VERSION ""

NS_ :

BS_:

BU_: VMCU TECU OBDScanT2 IC3 HPCU EMS ECUspare2 ECUspare1 DACU CIOM BBM

BO_ 2671813364 DiagReqMsgIntTGW2_A2_F4_BB2: 8 IC3
 SG_ InternalTesterDiagSig_A2_F4_ISig : 0|64@1+ (1,0) [0|0] ""  CIOM

BO_ 2671813108 DiagReqMsgIntTGW2_A1_F4_BB2: 8 IC3
 SG_ InternalTesterDiagSig_A1_F4_ISig : 0|64@1+ (1,0) [0|0] ""  CIOM

BO_ 2671812852 DiagReqMsgIntTGW2_A0_F4_BB2: 8 IC3
 SG_ InternalTesterDiagSig_A0_F4_ISig : 0|64@1+ (1,0) [0|0] ""  CIOM

BO_ 2671810804 DiagReqMsgIntTGW2_98_F4_BB2: 8 IC3
 SG_ InternalTesterDiagSig_98_F4_ISig : 0|64@1+ (1,0) [0|0] ""  CIOM

BO_ 2671807732 DiagReqMsgIntTGW2_8C_F4_BB2: 8 IC3
 SG_ InternalTesterDiagSig_8C_F4_ISig : 0|64@1+ (1,0) [0|0] ""  DACU

BO_ 2671801076 DiagReqMsgIntTGW2_72_F4_BB2: 8 IC3
 SG_ InternalTesterDiagSig_72_F4_ISig : 0|64@1+ (1,0) [0|0] ""  VMCU

BO_ 2671800820 DiagReqMsgIntTGW2_71_F4_BB2: 8 IC3
 SG_ InternalTesterDiagSig_71_F4_ISig : 0|64@1+ (1,0) [0|0] ""  VMCU

BO_ 2671793140 DiagReqMsgIntTGW2_53_F4_BB2: 8 IC3
 SG_ InternalTesterDiagSig_53_F4_ISig : 0|64@1+ (1,0) [0|0] ""  CIOM

BO_ 2671792884 DiagReqMsgIntTGW2_52_F4_BB2: 8 IC3
 SG_ InternalTesterDiagSig_52_F4_ISig : 0|64@1+ (1,0) [0|0] ""  DACU

BO_ 2671792628 DiagReqMsgIntTGW2_51_F4_BB2: 8 IC3
 SG_ InternalTesterDiagSig_51_F4_ISig : 0|64@1+ (1,0) [0|0] ""  DACU

BO_ 2671792372 DiagReqMsgIntTGW2_50_F4_BB2: 8 IC3
 SG_ InternalTesterDiagSig_50_F4_ISig : 0|64@1+ (1,0) [0|0] ""  DACU

BO_ 2671788276 DiagReqMsgIntTGW2_40_F4_BB2: 8 IC3
 SG_ InternalTesterDiagSig_40_F4_ISig : 0|64@1+ (1,0) [0|0] ""  CIOM

BO_ 2671784436 DiagReqMsgIntTGW2_31_F4_BB2: 8 IC3
 SG_ InternalTesterDiagSig_31_F4_ISig : 0|64@1+ (1,0) [0|0] ""  VMCU

BO_ 2671784180 DiagReqMsgIntTGW2_30_F4_BB2: 8 IC3
 SG_ InternalTesterDiagSig_30_F4_ISig : 0|64@1+ (1,0) [0|0] ""  VMCU

BO_ 2671781620 DiagReqMsgIntTGW2_26_F4_BB2: 8 IC3
 SG_ InternalTesterDiagSig_26_F4_ISig : 0|64@1+ (1,0) [0|0] ""  CIOM

BO_ 2671781364 DiagReqMsgIntTGW2_25_F4_BB2: 8 IC3
 SG_ InternalTesterDiagSig_25_F4_ISig : 0|64@1+ (1,0) [0|0] ""  VMCU

BO_ 2671781108 DiagReqMsgIntTGW2_24_F4_BB2: 8 IC3
 SG_ InternalTesterDiagSig_24_F4_ISig : 0|64@1+ (1,0) [0|0] ""  VMCU

BO_ 2671780852 DiagReqMsgIntTGW2_23_F4_BB2: 8 IC3
 SG_ InternalTesterDiagSig_23_F4_ISig : 0|64@1+ (1,0) [0|0] ""  VMCU

BO_ 2671780596 DiagReqMsgIntTGW2_22_F4_BB2: 8 IC3
 SG_ InternalTesterDiagSig_22_F4_ISig : 0|64@1+ (1,0) [0|0] ""  VMCU

BO_ 2671780340 DiagReqMsgIntTGW2_21_F4_BB2: 8 IC3
 SG_ InternalTesterDiagSig_21_F4_ISig : 0|64@1+ (1,0) [0|0] ""  VMCU

BO_ 2671780084 DiagReqMsgIntTGW2_20_F4_BB2: 8 IC3
 SG_ InternalTesterDiagSig_20_F4_ISig : 0|64@1+ (1,0) [0|0] ""  VMCU

BO_ 2671778548 DiagReqMsgIntTGW2_1A_F4_BB2: 8 IC3
 SG_ InternalTesterDiagSig_1A_F4_ISig : 0|64@1+ (1,0) [0|0] ""  VMCU

BO_ 2671778036 DiagReqMsgIntTGW2_18_F4_BB2: 8 IC3
 SG_ InternalTesterDiagSig_18_F4_ISig : 0|64@1+ (1,0) [0|0] ""  TECU

BO_ 2671775988 DiagReqMsgIntTGW2_10_F4_BB2: 8 IC3
 SG_ InternalTesterDiagSig_10_F4_ISig : 0|64@1+ (1,0) [0|0] ""  EMS

BO_ 2671833075 DiagReqMsgIntIC_EF_F3_BB2: 8 IC3
 SG_ InternalTesterDiagSig_EF_F3 : 0|64@1+ (1,0) [0|0] ""  HPCU

BO_ 2671821555 DiagReqMsgIntIC_C2_F3_BB2: 8 IC3
 SG_ InternalTesterDiagSig_C2_F3 : 0|64@1+ (1,0) [0|0] ""  HPCU

BO_ 2671814131 DiagReqMsgIntIC_A5_F3_BB2: 8 IC3
 SG_ InternalTesterDiagSig_A5_F3_ISig : 0|64@1+ (1,0) [0|0] ""  VMCU

BO_ 2671801331 DiagReqMsgIntIC_73_F3_BB2: 8 IC3
 SG_ InternalTesterDiagSig_73_F3_ISig : 0|64@1+ (1,0) [0|0] ""  VMCU

BO_ 2671797747 DiagReqMsgIntIC_65_F3_BB2: 8 IC3
 SG_ InternalTesterDiagSig_65_F3_ISig : 0|64@1+ (1,0) [0|0] ""  VMCU

BO_ 2671786227 DiagReqMsgIntIC_38_F3_BB2: 8 IC3
 SG_ InternalTesterDiagSig_38_F3_ISig : 0|64@1+ (1,0) [0|0] ""  VMCU

BO_ 2671830771 DiagReqMsgIntHMIIOM_E6_F3_BB2: 8 IC3
 SG_ InternalTesterDiagSig_E6_F3 : 0|64@1+ (1,0) [0|0] ""  BBM

BO_ 2671830515 DiagReqMsgIntHMIIOM_E5_F3_BB2: 8 IC3
 SG_ InternalTesterDiagSig_E5_F3_ISig : 0|64@1+ (1,0) [0|0] ""  BBM

BO_ 2671821043 DiagReqMsgIntHMIIOM_C0_F3_BB2: 8 IC3
 SG_ InternalTesterDiagSig_C0_F3_ISig : 0|64@1+ (1,0) [0|0] ""  CIOM

BO_ 2671813363 DiagReqMsgIntHMIIOM_A2_F3_BB2: 8 IC3
 SG_ InternalTesterDiagSig_A2_F3_ISig : 0|64@1+ (1,0) [0|0] ""  CIOM

BO_ 2671813107 DiagReqMsgIntHMIIOM_A1_F3_BB2: 8 IC3
 SG_ InternalTesterDiagSig_A1_F3_ISig : 0|64@1+ (1,0) [0|0] ""  CIOM

BO_ 2671812851 DiagReqMsgIntHMIIOM_A0_F3_BB2: 8 IC3
 SG_ InternalTesterDiagSig_A0_F3_ISig : 0|64@1+ (1,0) [0|0] ""  CIOM

BO_ 2671810803 DiagReqMsgIntHMIIOM_98_F3_BB2: 8 IC3
 SG_ InternalTesterDiagSig_98_F3_ISig : 0|64@1+ (1,0) [0|0] ""  CIOM

BO_ 2671807731 DiagReqMsgIntHMIIOM_8C_F3_BB2: 8 IC3
 SG_ InternalTesterDiagSig_8C_F3_ISig : 0|64@1+ (1,0) [0|0] ""  DACU

BO_ 2671801075 DiagReqMsgIntHMIIOM_72_F3_BB2: 8 IC3
 SG_ InternalTesterDiagSig_72_F3_ISig : 0|64@1+ (1,0) [0|0] ""  VMCU

BO_ 2671800819 DiagReqMsgIntHMIIOM_71_F3_BB2: 8 IC3
 SG_ InternalTesterDiagSig_71_F3_ISig : 0|64@1+ (1,0) [0|0] ""  VMCU

BO_ 2671793139 DiagReqMsgIntHMIIOM_53_F3_BB2: 8 IC3
 SG_ InternalTesterDiagSig_53_F3_ISig : 0|64@1+ (1,0) [0|0] ""  CIOM

BO_ 2671792883 DiagReqMsgIntHMIIOM_52_F3_BB2: 8 IC3
 SG_ InternalTesterDiagSig_52_F3_ISig : 0|64@1+ (1,0) [0|0] ""  DACU

BO_ 2671792627 DiagReqMsgIntHMIIOM_51_F3_BB2: 8 IC3
 SG_ InternalTesterDiagSig_51_F3_ISig : 0|64@1+ (1,0) [0|0] ""  DACU

BO_ 2671792371 DiagReqMsgIntHMIIOM_50_F3_BB2: 8 IC3
 SG_ InternalTesterDiagSig_50_F3 : 0|64@1+ (1,0) [0|0] ""  DACU

BO_ 2671788275 DiagReqMsgIntHMIIOM_40_F3_BB2: 8 IC3
 SG_ InternalTesterDiagSig_40_F3 : 0|64@1+ (1,0) [0|0] ""  CIOM

BO_ 2671784435 DiagReqMsgIntHMIIOM_31_F3_BB2: 8 IC3
 SG_ InternalTesterDiagSig_31_F3_ISig : 0|64@1+ (1,0) [0|0] ""  VMCU

BO_ 2671784179 DiagReqMsgIntHMIIOM_30_F3_BB2: 8 IC3
 SG_ InternalTesterDiagSig_30_F3_ISig : 0|64@1+ (1,0) [0|0] ""  VMCU

BO_ 2671781619 DiagReqMsgIntHMIIOM_26_F3_BB2: 8 IC3
 SG_ InternalTesterDiagSig_26_F3_ISig : 0|64@1+ (1,0) [0|0] ""  CIOM

BO_ 2671781363 DiagReqMsgIntHMIIOM_25_F3_BB2: 8 IC3
 SG_ InternalTesterDiagSig_25_F3_ISig : 0|64@1+ (1,0) [0|0] ""  VMCU

BO_ 2671781107 DiagReqMsgIntHMIIOM_24_F3_BB2: 8 IC3
 SG_ InternalTesterDiagSig_24_F3 : 0|64@1+ (1,0) [0|0] ""  VMCU

BO_ 2671780851 DiagReqMsgIntHMIIOM_23_F3_BB2: 8 IC3
 SG_ InternalTesterDiagSig_23_F3_ISig : 0|64@1+ (1,0) [0|0] ""  VMCU

BO_ 2671780595 DiagReqMsgIntHMIIOM_22_F3_BB2: 8 IC3
 SG_ InternalTesterDiagSig_22_F3_ISig : 0|64@1+ (1,0) [0|0] ""  VMCU

BO_ 2671780339 DiagReqMsgIntHMIIOM_21_F3_BB2: 8 IC3
 SG_ InternalTesterDiagSig_21_F3_ISig : 0|64@1+ (1,0) [0|0] ""  VMCU

BO_ 2671780083 DiagReqMsgIntHMIIOM_20_F3_BB2: 8 IC3
 SG_ InternalTesterDiagSig_20_F3_ISig : 0|64@1+ (1,0) [0|0] ""  VMCU

BO_ 2671778547 DiagReqMsgIntHMIIOM_1A_F3_BB2: 8 IC3
 SG_ InternalTesterDiagSig_1A_F3_ISig : 0|64@1+ (1,0) [0|0] ""  VMCU

BO_ 2671778035 DiagReqMsgIntHMIIOM_18_F3_BB2: 8 IC3
 SG_ InternalTesterDiagSig_18_F3 : 0|64@1+ (1,0) [0|0] ""  TECU

BO_ 2671775987 DiagReqMsgIntHMIIOM_10_F3_BB2: 8 IC3
 SG_ InternalTesterDiagSig_10_F3 : 0|64@1+ (1,0) [0|0] ""  EMS

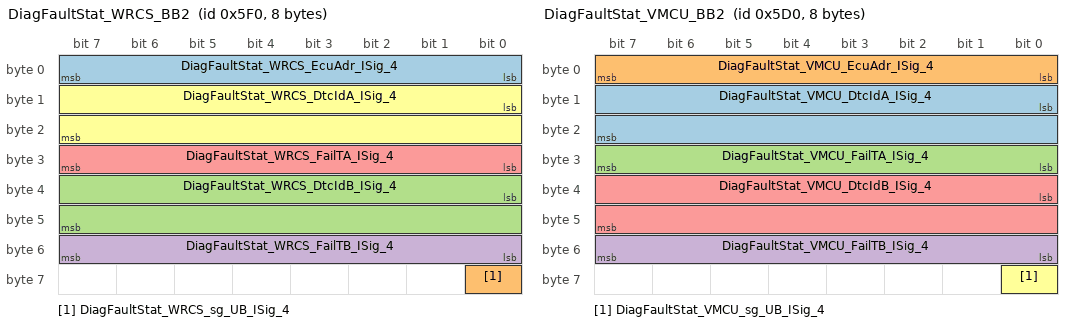
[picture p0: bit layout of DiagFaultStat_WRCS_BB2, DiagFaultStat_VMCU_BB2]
BO_ 1520 DiagFaultStat_WRCS_BB2: 8 CIOM
 SG_ DiagFaultStat_WRCS_EcuAdr_ISig_4 : 0|8@1+ (1,0) [0|255] ""  IC3
 SG_ DiagFaultStat_WRCS_sg_UB_ISig_4 : 56|1@1+ (1,0) [0|0] ""  IC3
 SG_ DiagFaultStat_WRCS_DtcIdB_ISig_4 : 32|16@1+ (1,0) [0|65535] ""  IC3
 SG_ DiagFaultStat_WRCS_FailTB_ISig_4 : 48|8@1+ (1,0) [0|255] ""  IC3
 SG_ DiagFaultStat_WRCS_FailTA_ISig_4 : 24|8@1+ (1,0) [0|255] ""  IC3
 SG_ DiagFaultStat_WRCS_DtcIdA_ISig_4 : 8|16@1+ (1,0) [0|65535] ""  IC3

BO_ 1488 DiagFaultStat_VMCU_BB2: 8 VMCU
 SG_ DiagFaultStat_VMCU_DtcIdA_ISig_4 : 8|16@1+ (1,0) [0|65535] ""  IC3
 SG_ DiagFaultStat_VMCU_EcuAdr_ISig_4 : 0|8@1+ (1,0) [0|255] ""  IC3
 SG_ DiagFaultStat_VMCU_FailTA_ISig_4 : 24|8@1+ (1,0) [0|255] ""  IC3
 SG_ DiagFaultStat_VMCU_FailTB_ISig_4 : 48|8@1+ (1,0) [0|255] ""  IC3
 SG_ DiagFaultStat_VMCU_DtcIdB_ISig_4 : 32|16@1+ (1,0) [0|65535] ""  IC3
 SG_ DiagFaultStat_VMCU_sg_UB_ISig_4 : 56|1@1+ (1,0) [0|0] ""  IC3

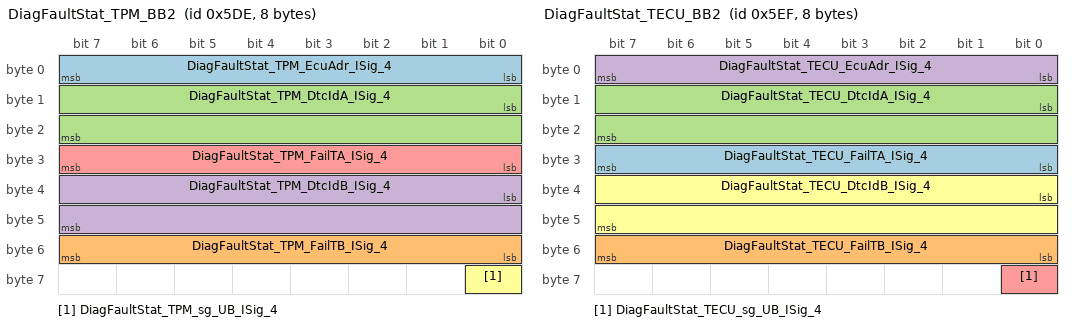
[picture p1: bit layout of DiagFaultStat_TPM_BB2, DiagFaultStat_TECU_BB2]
BO_ 1502 DiagFaultStat_TPM_BB2: 8 VMCU
 SG_ DiagFaultStat_TPM_EcuAdr_ISig_4 : 0|8@1+ (1,0) [0|255] ""  IC3
 SG_ DiagFaultStat_TPM_FailTB_ISig_4 : 48|8@1+ (1,0) [0|255] ""  IC3
 SG_ DiagFaultStat_TPM_DtcIdA_ISig_4 : 8|16@1+ (1,0) [0|65535] ""  IC3
 SG_ DiagFaultStat_TPM_DtcIdB_ISig_4 : 32|16@1+ (1,0) [0|65535] ""  IC3
 SG_ DiagFaultStat_TPM_FailTA_ISig_4 : 24|8@1+ (1,0) [0|255] ""  IC3
 SG_ DiagFaultStat_TPM_sg_UB_ISig_4 : 56|1@1+ (1,0) [0|0] ""  IC3

BO_ 1519 DiagFaultStat_TECU_BB2: 8 TECU
 SG_ DiagFaultStat_TECU_FailTA_ISig_4 : 24|8@1+ (1,0) [0|255] ""  IC3
 SG_ DiagFaultStat_TECU_FailTB_ISig_4 : 48|8@1+ (1,0) [0|255] ""  IC3
 SG_ DiagFaultStat_TECU_DtcIdA_ISig_4 : 8|16@1+ (1,0) [0|65535] ""  IC3
 SG_ DiagFaultStat_TECU_EcuAdr_ISig_4 : 0|8@1+ (1,0) [0|255] ""  IC3
 SG_ DiagFaultStat_TECU_sg_UB_ISig_4 : 56|1@1+ (1,0) [0|0] ""  IC3
 SG_ DiagFaultStat_TECU_DtcIdB_ISig_4 : 32|16@1+ (1,0) [0|65535] ""  IC3

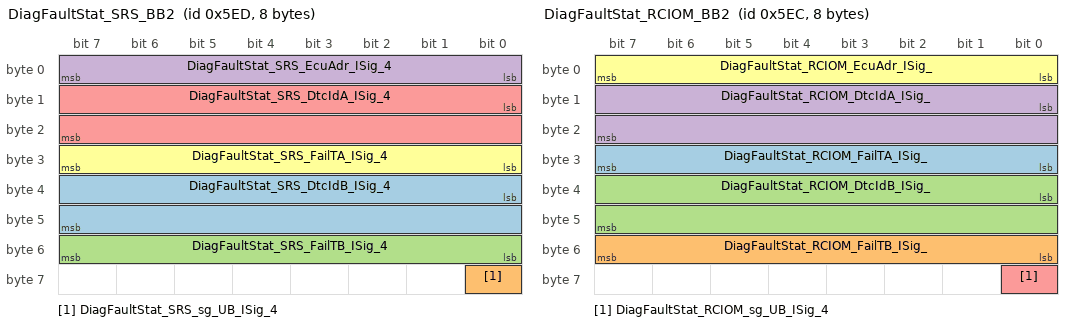
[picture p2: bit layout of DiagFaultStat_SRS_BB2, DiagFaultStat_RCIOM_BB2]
BO_ 1517 DiagFaultStat_SRS_BB2: 8 CIOM
 SG_ DiagFaultStat_SRS_DtcIdB_ISig_4 : 32|16@1+ (1,0) [0|65535] ""  IC3
 SG_ DiagFaultStat_SRS_sg_UB_ISig_4 : 56|1@1+ (1,0) [0|0] ""  IC3
 SG_ DiagFaultStat_SRS_FailTB_ISig_4 : 48|8@1+ (1,0) [0|255] ""  IC3
 SG_ DiagFaultStat_SRS_EcuAdr_ISig_4 : 0|8@1+ (1,0) [0|255] ""  IC3
 SG_ DiagFaultStat_SRS_DtcIdA_ISig_4 : 8|16@1+ (1,0) [0|65535] ""  IC3
 SG_ DiagFaultStat_SRS_FailTA_ISig_4 : 24|8@1+ (1,0) [0|255] ""  IC3

BO_ 1516 DiagFaultStat_RCIOM_BB2: 8 VMCU
 SG_ DiagFaultStat_RCIOM_FailTA_ISig_ : 24|8@1+ (1,0) [0|255] ""  IC3
 SG_ DiagFaultStat_RCIOM_FailTB_ISig_ : 48|8@1+ (1,0) [0|255] ""  IC3
 SG_ DiagFaultStat_RCIOM_DtcIdB_ISig_ : 32|16@1+ (1,0) [0|65535] ""  IC3
 SG_ DiagFaultStat_RCIOM_DtcIdA_ISig_ : 8|16@1+ (1,0) [0|65535] ""  IC3
 SG_ DiagFaultStat_RCIOM_sg_UB_ISig_4 : 56|1@1+ (1,0) [0|0] ""  IC3
 SG_ DiagFaultStat_RCIOM_EcuAdr_ISig_ : 0|8@1+ (1,0) [0|255] ""  IC3

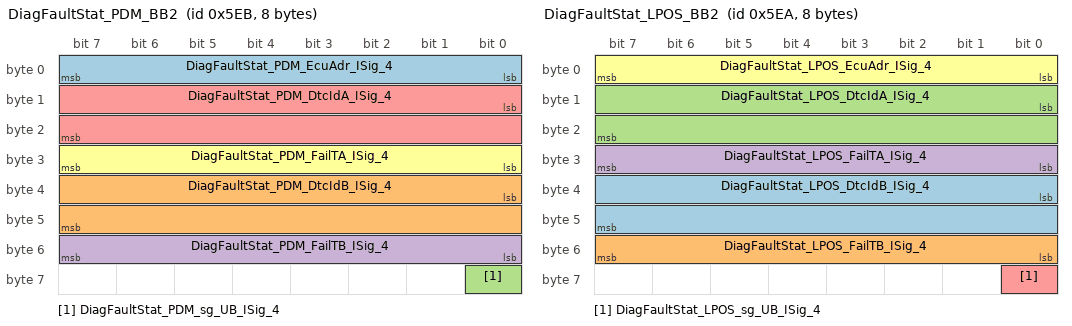
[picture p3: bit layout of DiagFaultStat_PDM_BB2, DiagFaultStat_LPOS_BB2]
BO_ 1515 DiagFaultStat_PDM_BB2: 8 CIOM
 SG_ DiagFaultStat_PDM_EcuAdr_ISig_4 : 0|8@1+ (1,0) [0|255] ""  IC3
 SG_ DiagFaultStat_PDM_DtcIdB_ISig_4 : 32|16@1+ (1,0) [0|65535] ""  IC3
 SG_ DiagFaultStat_PDM_sg_UB_ISig_4 : 56|1@1+ (1,0) [0|0] ""  IC3
 SG_ DiagFaultStat_PDM_FailTB_ISig_4 : 48|8@1+ (1,0) [0|255] ""  IC3
 SG_ DiagFaultStat_PDM_DtcIdA_ISig_4 : 8|16@1+ (1,0) [0|65535] ""  IC3
 SG_ DiagFaultStat_PDM_FailTA_ISig_4 : 24|8@1+ (1,0) [0|255] ""  IC3

BO_ 1514 DiagFaultStat_LPOS_BB2: 8 DACU
 SG_ DiagFaultStat_LPOS_DtcIdB_ISig_4 : 32|16@1+ (1,0) [0|65535] ""  IC3
 SG_ DiagFaultStat_LPOS_FailTB_ISig_4 : 48|8@1+ (1,0) [0|255] ""  IC3
 SG_ DiagFaultStat_LPOS_DtcIdA_ISig_4 : 8|16@1+ (1,0) [0|65535] ""  IC3
 SG_ DiagFaultStat_LPOS_FailTA_ISig_4 : 24|8@1+ (1,0) [0|255] ""  IC3
 SG_ DiagFaultStat_LPOS_sg_UB_ISig_4 : 56|1@1+ (1,0) [0|0] ""  IC3
 SG_ DiagFaultStat_LPOS_EcuAdr_ISig_4 : 0|8@1+ (1,0) [0|255] ""  IC3

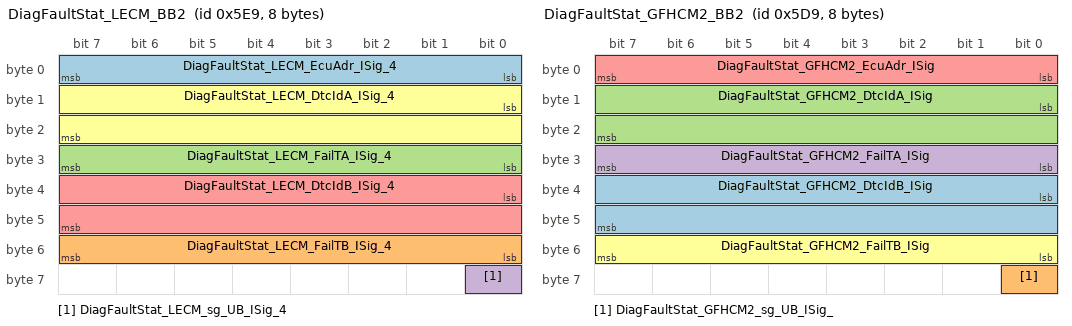
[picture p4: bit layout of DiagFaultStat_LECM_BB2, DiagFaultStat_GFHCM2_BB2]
BO_ 1513 DiagFaultStat_LECM_BB2: 8 CIOM
 SG_ DiagFaultStat_LECM_EcuAdr_ISig_4 : 0|8@1+ (1,0) [0|255] ""  IC3
 SG_ DiagFaultStat_LECM_FailTB_ISig_4 : 48|8@1+ (1,0) [0|255] ""  IC3
 SG_ DiagFaultStat_LECM_FailTA_ISig_4 : 24|8@1+ (1,0) [0|255] ""  IC3
 SG_ DiagFaultStat_LECM_sg_UB_ISig_4 : 56|1@1+ (1,0) [0|0] ""  IC3
 SG_ DiagFaultStat_LECM_DtcIdB_ISig_4 : 32|16@1+ (1,0) [0|65535] ""  IC3
 SG_ DiagFaultStat_LECM_DtcIdA_ISig_4 : 8|16@1+ (1,0) [0|65535] ""  IC3

BO_ 1497 DiagFaultStat_GFHCM2_BB2: 8 VMCU
 SG_ DiagFaultStat_GFHCM2_DtcIdB_ISig : 32|16@1+ (1,0) [0|65535] ""  IC3
 SG_ DiagFaultStat_GFHCM2_sg_UB_ISig_ : 56|1@1+ (1,0) [0|0] ""  IC3
 SG_ DiagFaultStat_GFHCM2_DtcIdA_ISig : 8|16@1+ (1,0) [0|65535] ""  IC3
 SG_ DiagFaultStat_GFHCM2_FailTA_ISig : 24|8@1+ (1,0) [0|255] ""  IC3
 SG_ DiagFaultStat_GFHCM2_EcuAdr_ISig : 0|8@1+ (1,0) [0|255] ""  IC3
 SG_ DiagFaultStat_GFHCM2_FailTB_ISig : 48|8@1+ (1,0) [0|255] ""  IC3

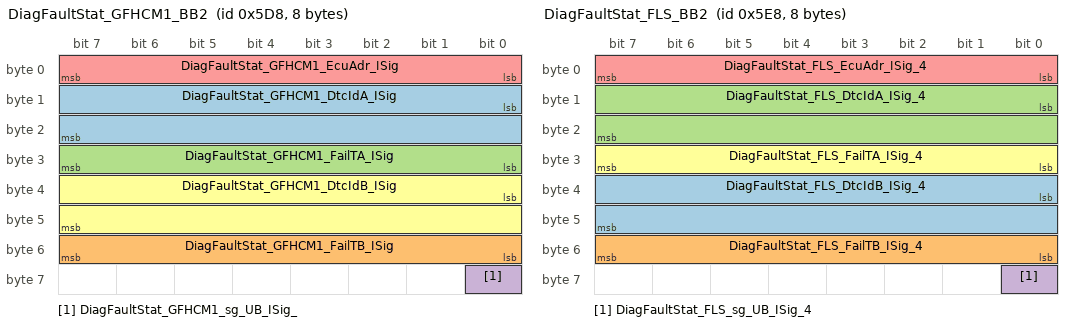
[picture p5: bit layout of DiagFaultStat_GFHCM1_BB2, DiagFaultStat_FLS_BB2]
BO_ 1496 DiagFaultStat_GFHCM1_BB2: 8 VMCU
 SG_ DiagFaultStat_GFHCM1_DtcIdA_ISig : 8|16@1+ (1,0) [0|65535] ""  IC3
 SG_ DiagFaultStat_GFHCM1_FailTB_ISig : 48|8@1+ (1,0) [0|255] ""  IC3
 SG_ DiagFaultStat_GFHCM1_FailTA_ISig : 24|8@1+ (1,0) [0|255] ""  IC3
 SG_ DiagFaultStat_GFHCM1_sg_UB_ISig_ : 56|1@1+ (1,0) [0|0] ""  IC3
 SG_ DiagFaultStat_GFHCM1_EcuAdr_ISig : 0|8@1+ (1,0) [0|255] ""  IC3
 SG_ DiagFaultStat_GFHCM1_DtcIdB_ISig : 32|16@1+ (1,0) [0|65535] ""  IC3

BO_ 1512 DiagFaultStat_FLS_BB2: 8 DACU
 SG_ DiagFaultStat_FLS_DtcIdB_ISig_4 : 32|16@1+ (1,0) [0|65535] ""  IC3
 SG_ DiagFaultStat_FLS_FailTB_ISig_4 : 48|8@1+ (1,0) [0|255] ""  IC3
 SG_ DiagFaultStat_FLS_DtcIdA_ISig_4 : 8|16@1+ (1,0) [0|65535] ""  IC3
 SG_ DiagFaultStat_FLS_sg_UB_ISig_4 : 56|1@1+ (1,0) [0|0] ""  IC3
 SG_ DiagFaultStat_FLS_EcuAdr_ISig_4 : 0|8@1+ (1,0) [0|255] ""  IC3
 SG_ DiagFaultStat_FLS_FailTA_ISig_4 : 24|8@1+ (1,0) [0|255] ""  IC3

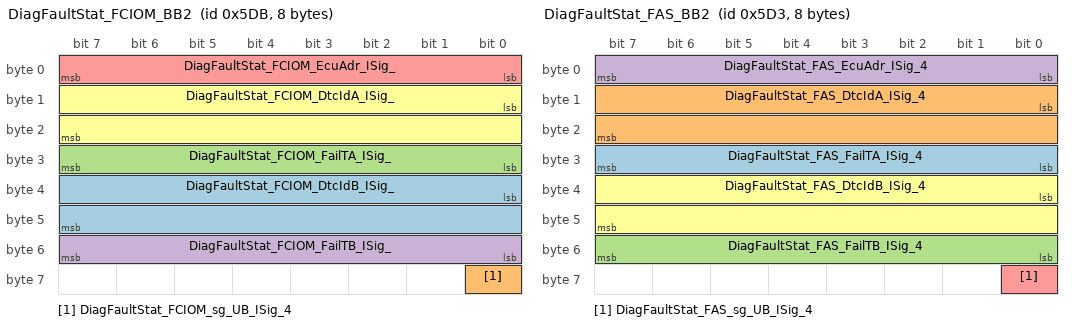
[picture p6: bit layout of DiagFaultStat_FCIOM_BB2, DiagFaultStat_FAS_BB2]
BO_ 1499 DiagFaultStat_FCIOM_BB2: 8 VMCU
 SG_ DiagFaultStat_FCIOM_DtcIdB_ISig_ : 32|16@1+ (1,0) [0|65535] ""  IC3
 SG_ DiagFaultStat_FCIOM_sg_UB_ISig_4 : 56|1@1+ (1,0) [0|0] ""  IC3
 SG_ DiagFaultStat_FCIOM_FailTA_ISig_ : 24|8@1+ (1,0) [0|255] ""  IC3
 SG_ DiagFaultStat_FCIOM_FailTB_ISig_ : 48|8@1+ (1,0) [0|255] ""  IC3
 SG_ DiagFaultStat_FCIOM_EcuAdr_ISig_ : 0|8@1+ (1,0) [0|255] ""  IC3
 SG_ DiagFaultStat_FCIOM_DtcIdA_ISig_ : 8|16@1+ (1,0) [0|65535] ""  IC3

BO_ 1491 DiagFaultStat_FAS_BB2: 8 VMCU
 SG_ DiagFaultStat_FAS_FailTA_ISig_4 : 24|8@1+ (1,0) [0|255] ""  IC3
 SG_ DiagFaultStat_FAS_DtcIdA_ISig_4 : 8|16@1+ (1,0) [0|65535] ""  IC3
 SG_ DiagFaultStat_FAS_FailTB_ISig_4 : 48|8@1+ (1,0) [0|255] ""  IC3
 SG_ DiagFaultStat_FAS_EcuAdr_ISig_4 : 0|8@1+ (1,0) [0|255] ""  IC3
 SG_ DiagFaultStat_FAS_sg_UB_ISig_4 : 56|1@1+ (1,0) [0|0] ""  IC3
 SG_ DiagFaultStat_FAS_DtcIdB_ISig_4 : 32|16@1+ (1,0) [0|65535] ""  IC3

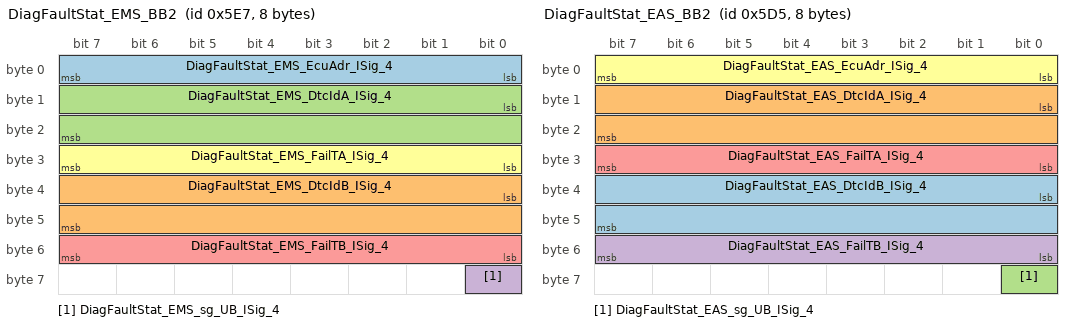
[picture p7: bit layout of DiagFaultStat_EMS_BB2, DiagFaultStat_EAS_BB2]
BO_ 1511 DiagFaultStat_EMS_BB2: 8 EMS
 SG_ DiagFaultStat_EMS_EcuAdr_ISig_4 : 0|8@1+ (1,0) [0|255] ""  IC3
 SG_ DiagFaultStat_EMS_DtcIdB_ISig_4 : 32|16@1+ (1,0) [0|65535] ""  IC3
 SG_ DiagFaultStat_EMS_DtcIdA_ISig_4 : 8|16@1+ (1,0) [0|65535] ""  IC3
 SG_ DiagFaultStat_EMS_sg_UB_ISig_4 : 56|1@1+ (1,0) [0|0] ""  IC3
 SG_ DiagFaultStat_EMS_FailTB_ISig_4 : 48|8@1+ (1,0) [0|255] ""  IC3
 SG_ DiagFaultStat_EMS_FailTA_ISig_4 : 24|8@1+ (1,0) [0|255] ""  IC3

BO_ 1493 DiagFaultStat_EAS_BB2: 8 VMCU
 SG_ DiagFaultStat_EAS_DtcIdB_ISig_4 : 32|16@1+ (1,0) [0|65535] ""  IC3
 SG_ DiagFaultStat_EAS_DtcIdA_ISig_4 : 8|16@1+ (1,0) [0|65535] ""  IC3
 SG_ DiagFaultStat_EAS_sg_UB_ISig_4 : 56|1@1+ (1,0) [0|0] ""  IC3
 SG_ DiagFaultStat_EAS_FailTB_ISig_4 : 48|8@1+ (1,0) [0|255] ""  IC3
 SG_ DiagFaultStat_EAS_FailTA_ISig_4 : 24|8@1+ (1,0) [0|255] ""  IC3
 SG_ DiagFaultStat_EAS_EcuAdr_ISig_4 : 0|8@1+ (1,0) [0|255] ""  IC3

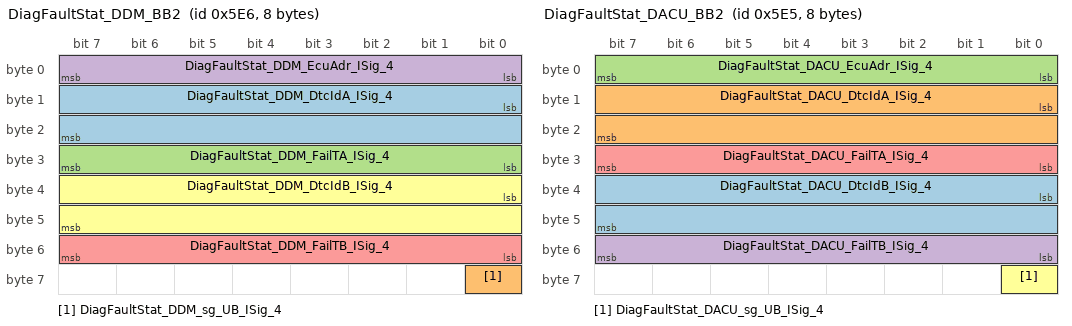
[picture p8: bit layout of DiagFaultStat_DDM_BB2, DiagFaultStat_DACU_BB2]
BO_ 1510 DiagFaultStat_DDM_BB2: 8 CIOM
 SG_ DiagFaultStat_DDM_DtcIdA_ISig_4 : 8|16@1+ (1,0) [0|65535] ""  IC3
 SG_ DiagFaultStat_DDM_sg_UB_ISig_4 : 56|1@1+ (1,0) [0|0] ""  IC3
 SG_ DiagFaultStat_DDM_FailTA_ISig_4 : 24|8@1+ (1,0) [0|255] ""  IC3
 SG_ DiagFaultStat_DDM_EcuAdr_ISig_4 : 0|8@1+ (1,0) [0|255] ""  IC3
 SG_ DiagFaultStat_DDM_FailTB_ISig_4 : 48|8@1+ (1,0) [0|255] ""  IC3
 SG_ DiagFaultStat_DDM_DtcIdB_ISig_4 : 32|16@1+ (1,0) [0|65535] ""  IC3

BO_ 1509 DiagFaultStat_DACU_BB2: 8 DACU
 SG_ DiagFaultStat_DACU_DtcIdB_ISig_4 : 32|16@1+ (1,0) [0|65535] ""  IC3
 SG_ DiagFaultStat_DACU_DtcIdA_ISig_4 : 8|16@1+ (1,0) [0|65535] ""  IC3
 SG_ DiagFaultStat_DACU_EcuAdr_ISig_4 : 0|8@1+ (1,0) [0|255] ""  IC3
 SG_ DiagFaultStat_DACU_FailTB_ISig_4 : 48|8@1+ (1,0) [0|255] ""  IC3
 SG_ DiagFaultStat_DACU_FailTA_ISig_4 : 24|8@1+ (1,0) [0|255] ""  IC3
 SG_ DiagFaultStat_DACU_sg_UB_ISig_4 : 56|1@1+ (1,0) [0|0] ""  IC3

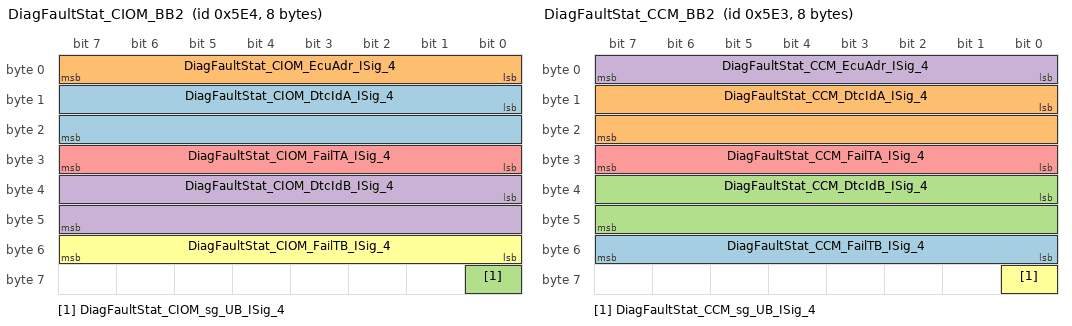
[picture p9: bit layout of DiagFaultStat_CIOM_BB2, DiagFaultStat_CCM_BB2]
BO_ 1508 DiagFaultStat_CIOM_BB2: 8 CIOM
 SG_ DiagFaultStat_CIOM_DtcIdA_ISig_4 : 8|16@1+ (1,0) [0|65535] ""  IC3
 SG_ DiagFaultStat_CIOM_EcuAdr_ISig_4 : 0|8@1+ (1,0) [0|255] ""  IC3
 SG_ DiagFaultStat_CIOM_sg_UB_ISig_4 : 56|1@1+ (1,0) [0|0] ""  IC3
 SG_ DiagFaultStat_CIOM_DtcIdB_ISig_4 : 32|16@1+ (1,0) [0|65535] ""  IC3
 SG_ DiagFaultStat_CIOM_FailTA_ISig_4 : 24|8@1+ (1,0) [0|255] ""  IC3
 SG_ DiagFaultStat_CIOM_FailTB_ISig_4 : 48|8@1+ (1,0) [0|255] ""  IC3

BO_ 1507 DiagFaultStat_CCM_BB2: 8 CIOM
 SG_ DiagFaultStat_CCM_FailTB_ISig_4 : 48|8@1+ (1,0) [0|255] ""  IC3
 SG_ DiagFaultStat_CCM_DtcIdA_ISig_4 : 8|16@1+ (1,0) [0|65535] ""  IC3
 SG_ DiagFaultStat_CCM_DtcIdB_ISig_4 : 32|16@1+ (1,0) [0|65535] ""  IC3
 SG_ DiagFaultStat_CCM_EcuAdr_ISig_4 : 0|8@1+ (1,0) [0|255] ""  IC3
 SG_ DiagFaultStat_CCM_FailTA_ISig_4 : 24|8@1+ (1,0) [0|255] ""  IC3
 SG_ DiagFaultStat_CCM_sg_UB_ISig_4 : 56|1@1+ (1,0) [0|0] ""  IC3

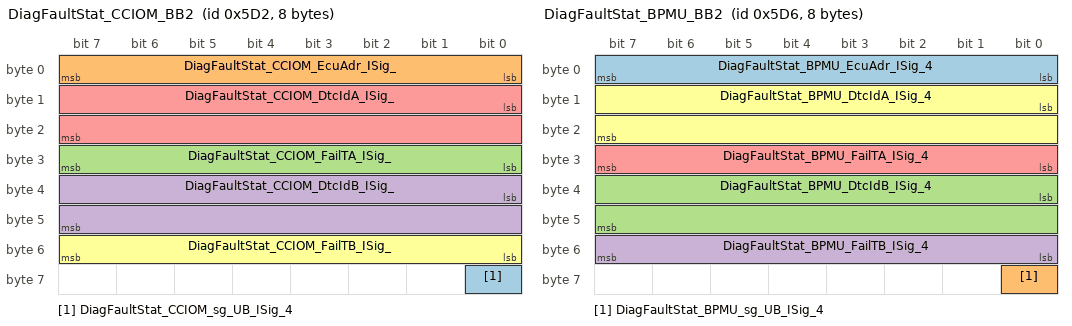
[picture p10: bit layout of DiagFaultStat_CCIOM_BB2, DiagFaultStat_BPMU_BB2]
BO_ 1490 DiagFaultStat_CCIOM_BB2: 8 VMCU
 SG_ DiagFaultStat_CCIOM_sg_UB_ISig_4 : 56|1@1+ (1,0) [0|0] ""  IC3
 SG_ DiagFaultStat_CCIOM_EcuAdr_ISig_ : 0|8@1+ (1,0) [0|255] ""  IC3
 SG_ DiagFaultStat_CCIOM_FailTA_ISig_ : 24|8@1+ (1,0) [0|255] ""  IC3
 SG_ DiagFaultStat_CCIOM_DtcIdB_ISig_ : 32|16@1+ (1,0) [0|65535] ""  IC3
 SG_ DiagFaultStat_CCIOM_DtcIdA_ISig_ : 8|16@1+ (1,0) [0|65535] ""  IC3
 SG_ DiagFaultStat_CCIOM_FailTB_ISig_ : 48|8@1+ (1,0) [0|255] ""  IC3

BO_ 1494 DiagFaultStat_BPMU_BB2: 8 VMCU
 SG_ DiagFaultStat_BPMU_EcuAdr_ISig_4 : 0|8@1+ (1,0) [0|255] ""  IC3
 SG_ DiagFaultStat_BPMU_sg_UB_ISig_4 : 56|1@1+ (1,0) [0|0] ""  IC3
 SG_ DiagFaultStat_BPMU_DtcIdB_ISig_4 : 32|16@1+ (1,0) [0|65535] ""  IC3
 SG_ DiagFaultStat_BPMU_FailTB_ISig_4 : 48|8@1+ (1,0) [0|255] ""  IC3
 SG_ DiagFaultStat_BPMU_FailTA_ISig_4 : 24|8@1+ (1,0) [0|255] ""  IC3
 SG_ DiagFaultStat_BPMU_DtcIdA_ISig_4 : 8|16@1+ (1,0) [0|65535] ""  IC3

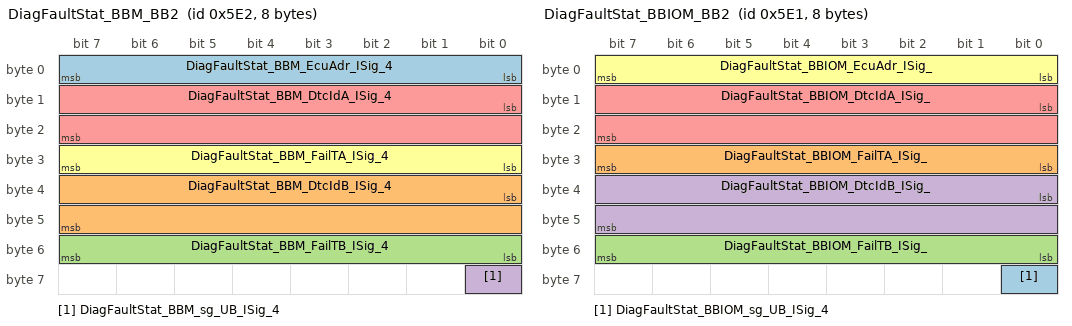
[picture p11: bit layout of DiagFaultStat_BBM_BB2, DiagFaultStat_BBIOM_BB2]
BO_ 1506 DiagFaultStat_BBM_BB2: 8 BBM
 SG_ DiagFaultStat_BBM_EcuAdr_ISig_4 : 0|8@1+ (1,0) [0|255] ""  IC3
 SG_ DiagFaultStat_BBM_DtcIdB_ISig_4 : 32|16@1+ (1,0) [0|65535] ""  IC3
 SG_ DiagFaultStat_BBM_FailTB_ISig_4 : 48|8@1+ (1,0) [0|255] ""  IC3
 SG_ DiagFaultStat_BBM_sg_UB_ISig_4 : 56|1@1+ (1,0) [0|0] ""  IC3
 SG_ DiagFaultStat_BBM_DtcIdA_ISig_4 : 8|16@1+ (1,0) [0|65535] ""  IC3
 SG_ DiagFaultStat_BBM_FailTA_ISig_4 : 24|8@1+ (1,0) [0|255] ""  IC3

BO_ 1505 DiagFaultStat_BBIOM_BB2: 8 BBM
 SG_ DiagFaultStat_BBIOM_sg_UB_ISig_4 : 56|1@1+ (1,0) [0|0] ""  IC3
 SG_ DiagFaultStat_BBIOM_FailTA_ISig_ : 24|8@1+ (1,0) [0|255] ""  IC3
 SG_ DiagFaultStat_BBIOM_FailTB_ISig_ : 48|8@1+ (1,0) [0|255] ""  IC3
 SG_ DiagFaultStat_BBIOM_DtcIdB_ISig_ : 32|16@1+ (1,0) [0|65535] ""  IC3
 SG_ DiagFaultStat_BBIOM_DtcIdA_ISig_ : 8|16@1+ (1,0) [0|65535] ""  IC3
 SG_ DiagFaultStat_BBIOM_EcuAdr_ISig_ : 0|8@1+ (1,0) [0|255] ""  IC3

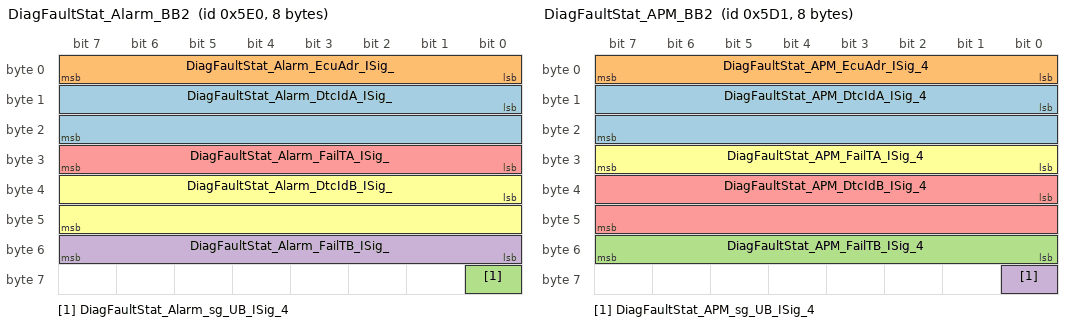
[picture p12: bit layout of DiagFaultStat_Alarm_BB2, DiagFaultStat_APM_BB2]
BO_ 1504 DiagFaultStat_Alarm_BB2: 8 CIOM
 SG_ DiagFaultStat_Alarm_DtcIdA_ISig_ : 8|16@1+ (1,0) [0|65535] ""  IC3
 SG_ DiagFaultStat_Alarm_EcuAdr_ISig_ : 0|8@1+ (1,0) [0|255] ""  IC3
 SG_ DiagFaultStat_Alarm_sg_UB_ISig_4 : 56|1@1+ (1,0) [0|0] ""  IC3
 SG_ DiagFaultStat_Alarm_FailTB_ISig_ : 48|8@1+ (1,0) [0|255] ""  IC3
 SG_ DiagFaultStat_Alarm_FailTA_ISig_ : 24|8@1+ (1,0) [0|255] ""  IC3
 SG_ DiagFaultStat_Alarm_DtcIdB_ISig_ : 32|16@1+ (1,0) [0|65535] ""  IC3

BO_ 1489 DiagFaultStat_APM_BB2: 8 VMCU
 SG_ DiagFaultStat_APM_DtcIdA_ISig_4 : 8|16@1+ (1,0) [0|65535] ""  IC3
 SG_ DiagFaultStat_APM_EcuAdr_ISig_4 : 0|8@1+ (1,0) [0|255] ""  IC3
 SG_ DiagFaultStat_APM_FailTB_ISig_4 : 48|8@1+ (1,0) [0|255] ""  IC3
 SG_ DiagFaultStat_APM_sg_UB_ISig_4 : 56|1@1+ (1,0) [0|0] ""  IC3
 SG_ DiagFaultStat_APM_DtcIdB_ISig_4 : 32|16@1+ (1,0) [0|65535] ""  IC3
 SG_ DiagFaultStat_APM_FailTA_ISig_4 : 24|8@1+ (1,0) [0|255] ""  IC3

BO_ 1919 Debug9_TECU_BB2: 8 TECU
 SG_ Debug_9_TECU : 0|64@1+ (1,0) [0|0] "" Vector__XXX

BO_ 1972 Debug9_DACU_BB2: 8 DACU
 SG_ Debug_9_DACU : 0|64@1+ (1,0) [0|0] "" Vector__XXX

BO_ 1918 Debug8_TECU_BB2: 8 TECU
 SG_ Debug_8_TECU : 0|64@1+ (1,0) [0|0] "" Vector__XXX

BO_ 1976 Debug8_IC_BB2: 8 IC3
 SG_ Debug_8_IC_BB2 : 0|64@1+ (1,0) [0|0] "" Vector__XXX

BO_ 1971 Debug8_DACU_BB2: 8 DACU
 SG_ Debug_8_DACU : 0|64@1+ (1,0) [0|0] "" Vector__XXX

BO_ 1917 Debug7_TECU_BB2: 8 TECU
 SG_ Debug_7_TECU : 0|64@1+ (1,0) [0|0] "" Vector__XXX

BO_ 1975 Debug7_IC_BB2: 8 IC3
 SG_ Debug_7_IC_BB2 : 0|64@1+ (1,0) [0|0] "" Vector__XXX

BO_ 1969 Debug7_DACU_BB2: 8 DACU
 SG_ Debug_7_DACU : 0|64@1+ (1,0) [0|0] "" Vector__XXX

BO_ 1970 Debug7_BBM_BB2: 8 BBM
 SG_ Debug_7_BBM : 0|64@1+ (1,0) [0|0] "" Vector__XXX

BO_ 1963 Debug6_VMCU_BB2: 8 VMCU
 SG_ Debug_6_VMCU : 0|64@1+ (1,0) [0|0] "" Vector__XXX

BO_ 1916 Debug6_TECU_BB2: 8 TECU
 SG_ Debug_6_TECU : 0|64@1+ (1,0) [0|0] "" Vector__XXX

BO_ 1878 Debug6_HPCU_BB2: 8 HPCU
 SG_ Debug_6_HPCU : 0|64@1+ (1,0) [0|0] "" Vector__XXX

BO_ 1966 Debug6_HMIIOM_BB2: 8 IC3
 SG_ Debug_6_HMIIOM : 0|64@1+ (1,0) [0|0] "" Vector__XXX

BO_ 1961 Debug6_EMS_BB2: 8 EMS
 SG_ Debug_6_EMS : 0|64@1+ (1,0) [0|0] "" Vector__XXX

BO_ 1965 Debug6_DACU_BB2: 8 DACU
 SG_ Debug_6_DACU : 0|64@1+ (1,0) [0|0] "" Vector__XXX

BO_ 1964 Debug6_CIOM_BB2: 8 CIOM
 SG_ Debug_6_CIOM : 0|64@1+ (1,0) [0|0] "" Vector__XXX

BO_ 1967 Debug6_BBM_BB2: 8 BBM
 SG_ Debug_6_BBM : 0|64@1+ (1,0) [0|0] "" Vector__XXX

BO_ 1956 Debug5_VMCU_BB2: 8 VMCU
 SG_ Debug_5_VMCU : 0|64@1+ (1,0) [0|0] "" Vector__XXX

BO_ 1915 Debug5_TECU_BB2: 8 TECU
 SG_ Debug_5_TECU : 0|64@1+ (1,0) [0|0] "" Vector__XXX

BO_ 1877 Debug5_HPCU_BB2: 8 HPCU
 SG_ Debug_5_HPCU : 0|64@1+ (1,0) [0|0] "" Vector__XXX

BO_ 1959 Debug5_HMIIOM_BB2: 8 IC3
 SG_ Debug_5_HMIIOM : 0|64@1+ (1,0) [0|0] "" Vector__XXX

BO_ 1954 Debug5_EMS_BB2: 8 EMS
 SG_ Debug_5_EMS : 0|64@1+ (1,0) [0|0] "" Vector__XXX

BO_ 1958 Debug5_DACU_BB2: 8 DACU
 SG_ Debug_5_DACU : 0|64@1+ (1,0) [0|0] "" Vector__XXX

BO_ 1957 Debug5_CIOM_BB2: 8 CIOM
 SG_ Debug_5_CIOM : 0|64@1+ (1,0) [0|0] "" Vector__XXX

BO_ 1960 Debug5_BBM_BB2: 8 BBM
 SG_ Debug_5_BBM : 0|64@1+ (1,0) [0|0] "" Vector__XXX

BO_ 1949 Debug4_VMCU_BB2: 8 VMCU
 SG_ Debug_4_VMCU : 0|64@1+ (1,0) [0|0] "" Vector__XXX

BO_ 1914 Debug4_TECU_BB2: 8 TECU
 SG_ Debug_4_TECU : 0|64@1+ (1,0) [0|0] "" Vector__XXX

BO_ 1876 Debug4_HPCU_BB2: 8 HPCU
 SG_ Debug_4_HPCU : 0|64@1+ (1,0) [0|0] "" Vector__XXX

BO_ 1952 Debug4_HMIIOM_BB2: 8 IC3
 SG_ Debug_4_HMIIOM : 0|64@1+ (1,0) [0|0] "" Vector__XXX

BO_ 1947 Debug4_EMS_BB2: 8 EMS
 SG_ Debug_4_EMS : 0|64@1+ (1,0) [0|0] "" Vector__XXX

BO_ 1951 Debug4_DACU_BB2: 8 DACU
 SG_ Debug_4_DACU : 0|64@1+ (1,0) [0|0] "" Vector__XXX

BO_ 1950 Debug4_CIOM_BB2: 8 CIOM
 SG_ Debug_4_CIOM : 0|64@1+ (1,0) [0|0] "" Vector__XXX

BO_ 1953 Debug4_BBM_BB2: 8 BBM
 SG_ Debug_4_BBM : 0|64@1+ (1,0) [0|0] "" Vector__XXX

BO_ 1942 Debug3_VMCU_BB2: 8 VMCU
 SG_ Debug_3_VMCU : 0|64@1+ (1,0) [0|0] "" Vector__XXX

BO_ 1897 Debug3_TECU_BB2: 8 TECU
 SG_ Debug_3_TECU : 0|64@1+ (1,0) [0|0] "" Vector__XXX

BO_ 1875 Debug3_HPCU_BB2: 8 HPCU
 SG_ Debug_3_HPCU : 0|64@1+ (1,0) [0|0] "" Vector__XXX

BO_ 1945 Debug3_HMIIOM_BB2: 8 IC3
 SG_ Debug_3_HMIIOM : 0|64@1+ (1,0) [0|0] "" Vector__XXX

BO_ 1940 Debug3_EMS_BB2: 8 EMS
 SG_ Debug_3_EMS : 0|64@1+ (1,0) [0|0] "" Vector__XXX

BO_ 1944 Debug3_DACU_BB2: 8 DACU
 SG_ Debug_3_DACU : 0|64@1+ (1,0) [0|0] "" Vector__XXX

BO_ 1943 Debug3_CIOM_BB2: 8 CIOM
 SG_ Debug_3_CIOM : 0|64@1+ (1,0) [0|0] "" Vector__XXX

BO_ 1946 Debug3_BBM_BB2: 8 BBM
 SG_ Debug_3_BBM : 0|64@1+ (1,0) [0|0] "" Vector__XXX

BO_ 1935 Debug2_VMCU_BB2: 8 VMCU
 SG_ Debug_2_VMCU : 0|64@1+ (1,0) [0|0] "" Vector__XXX

BO_ 1896 Debug2_TECU_BB2: 8 TECU
 SG_ Debug_2_TECU : 0|64@1+ (1,0) [0|0] "" Vector__XXX

BO_ 1874 Debug2_HPCU_BB2: 8 HPCU
 SG_ Debug_2_HPCU : 0|64@1+ (1,0) [0|0] "" Vector__XXX

BO_ 1938 Debug2_HMIIOM_BB2: 8 IC3
 SG_ Debug_2_HMIIOM : 0|64@1+ (1,0) [0|0] "" Vector__XXX

BO_ 1933 Debug2_EMS_BB2: 8 EMS
 SG_ Debug_2_EMS : 0|64@1+ (1,0) [0|0] "" Vector__XXX

BO_ 1937 Debug2_DACU_BB2: 8 DACU
 SG_ Debug_2_DACU : 0|64@1+ (1,0) [0|0] "" Vector__XXX

BO_ 1936 Debug2_CIOM_BB2: 8 CIOM
 SG_ Debug_2_CIOM : 0|64@1+ (1,0) [0|0] "" Vector__XXX

BO_ 1939 Debug2_BBM_BB2: 8 BBM
 SG_ Debug_2_BBM : 0|64@1+ (1,0) [0|0] "" Vector__XXX

BO_ 1968 Debug21_TECU_BB2: 8 TECU
 SG_ Debug_21_TECU : 0|64@1+ (1,0) [0|0] "" Vector__XXX

BO_ 1962 Debug20_TECU_BB2: 8 TECU
 SG_ Debug_20_TECU : 0|64@1+ (1,0) [0|0] "" Vector__XXX

BO_ 1928 Debug1_VMCU_BB2: 8 Vector__XXX
 SG_ Debug_1_VMCU : 0|64@1+ (1,0) [0|0] ""  VMCU

BO_ 1927 Debug1_TECU_BB2: 8 Vector__XXX
 SG_ Debug_1_TECU : 0|64@1+ (1,0) [0|0] ""  TECU

BO_ 1873 Debug1_HPCU_BB2: 8 Vector__XXX
 SG_ Debug_1_HPCU : 0|64@1+ (1,0) [0|0] ""  HPCU

BO_ 1931 Debug1_HMIIOM_BB2: 8 Vector__XXX
 SG_ Debug_1_HMIIOM : 0|64@1+ (1,0) [0|0] ""  IC3

BO_ 1926 Debug1_EMS_BB2: 8 Vector__XXX
 SG_ Debug_1_EMS : 0|64@1+ (1,0) [0|0] ""  EMS

BO_ 1930 Debug1_DACU_BB2: 8 Vector__XXX
 SG_ Debug_1_DACU : 0|64@1+ (1,0) [0|0] ""  DACU

BO_ 1929 Debug1_CIOM_BB2: 8 Vector__XXX
 SG_ Debug_1_CIOM : 0|64@1+ (1,0) [0|0] ""  CIOM

BO_ 1932 Debug1_BBM_BB2: 8 Vector__XXX
 SG_ Debug_1_BBM : 0|64@1+ (1,0) [0|0] ""  BBM

BO_ 1955 Debug19_TECU_BB2: 8 TECU
 SG_ Debug_19_TECU : 0|64@1+ (1,0) [0|0] "" Vector__XXX

BO_ 1948 Debug18_TECU_BB2: 8 TECU
 SG_ Debug_18_TECU : 0|64@1+ (1,0) [0|0] "" Vector__XXX

BO_ 1941 Debug17_TECU_BB2: 8 TECU
 SG_ Debug_17_TECU : 0|64@1+ (1,0) [0|0] "" Vector__XXX

BO_ 1934 Debug16_TECU_BB2: 8 TECU
 SG_ Debug_16_TECU : 0|64@1+ (1,0) [0|0] "" Vector__XXX

BO_ 1925 Debug15_TECU_BB2: 8 TECU
 SG_ Debug_15_TECU : 0|64@1+ (1,0) [0|0] "" Vector__XXX

BO_ 1924 Debug14_TECU_BB2: 8 TECU
 SG_ Debug_14_TECU : 0|64@1+ (1,0) [0|0] "" Vector__XXX

BO_ 1923 Debug13_TECU_BB2: 8 TECU
 SG_ Debug_13_TECU : 0|64@1+ (1,0) [0|0] "" Vector__XXX

BO_ 1922 Debug12_TECU_BB2: 8 TECU
 SG_ Debug_12_TECU : 0|64@1+ (1,0) [0|0] "" Vector__XXX

BO_ 1921 Debug11_TECU_BB2: 8 TECU
 SG_ Debug_11_TECU : 0|64@1+ (1,0) [0|0] "" Vector__XXX

BO_ 1974 Debug11_DACU_BB2: 8 DACU
 SG_ Debug_11_DACU : 0|64@1+ (1,0) [0|0] "" Vector__XXX

BO_ 1920 Debug10_TECU_BB2: 8 TECU
 SG_ Debug_10_TECU : 0|64@1+ (1,0) [0|0] "" Vector__XXX

BO_ 1973 Debug10_DACU_BB2: 8 DACU
 SG_ Debug_10_DACU : 0|64@1+ (1,0) [0|0] "" Vector__XXX

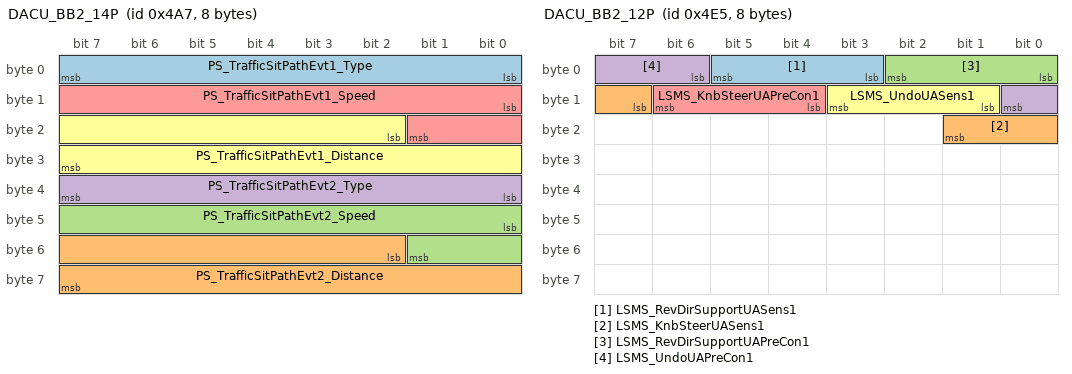
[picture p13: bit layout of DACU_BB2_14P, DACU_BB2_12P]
BO_ 1191 DACU_BB2_14P: 8 DACU
 SG_ PS_TrafficSitPathEvt1_Type : 0|8@1+ (1,0) [0|0] ""  IC3
 SG_ PS_TrafficSitPathEvt2_Distance : 50|14@1+ (1,0) [0|16383] "m"  IC3
 SG_ PS_TrafficSitPathEvt2_Speed : 40|10@1+ (0.25,0) [0|255.75] "Km_per_h"  IC3
 SG_ PS_TrafficSitPathEvt2_Type : 32|8@1+ (1,0) [0|0] ""  IC3
 SG_ PS_TrafficSitPathEvt1_Speed : 8|10@1+ (0.25,0) [0|255.75] "Km_per_h"  IC3
 SG_ PS_TrafficSitPathEvt1_Distance : 18|14@1+ (1,0) [0|16383] "m"  IC3

BO_ 1484 DACU_BB2_13P: 8 DACU
 SG_ DACU_Available_Log_ISig_4 : 0|8@1+ (1,0) [0|0] ""  IC3

BO_ 1253 DACU_BB2_12P: 8 DACU
 SG_ LSMS_RevDirSupportUASens1 : 3|3@1+ (1,0) [0|0] ""  IC3
 SG_ LSMS_KnbSteerUASens1 : 15|3@1+ (1,0) [0|0] ""  IC3
 SG_ LSMS_RevDirSupportUAPreCon1 : 0|3@1+ (1,0) [0|0] ""  IC3
 SG_ LSMS_UndoUAPreCon1 : 6|3@1+ (1,0) [0|0] ""  IC3
 SG_ LSMS_KnbSteerUAPreCon1 : 12|3@1+ (1,0) [0|0] ""  IC3
 SG_ LSMS_UndoUASens1 : 9|3@1+ (1,0) [0|0] ""  IC3

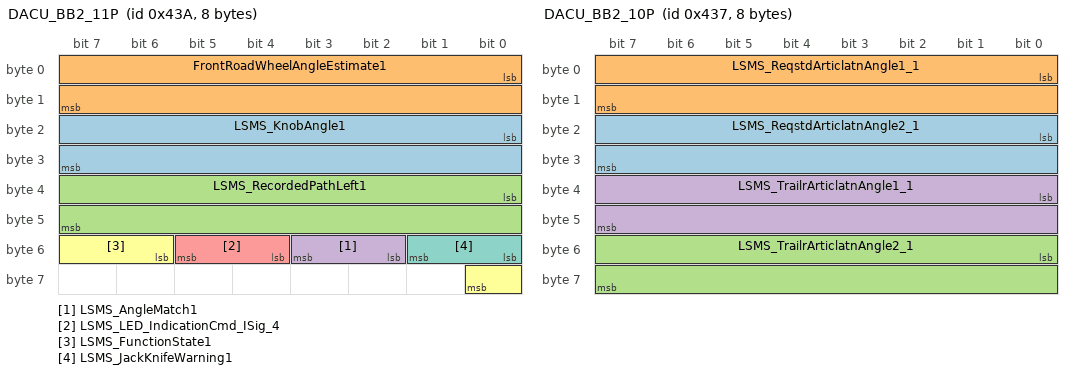
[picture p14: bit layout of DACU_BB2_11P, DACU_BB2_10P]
BO_ 1082 DACU_BB2_11P: 8 DACU
 SG_ LSMS_KnobAngle1 : 16|16@1+ (5E-005,-1.6) [-1.6|1.67675] ""  IC3
 SG_ FrontRoadWheelAngleEstimate1 : 0|16@1+ (5E-005,-1.6) [-1.6|1.67675] "rad"  IC3
 SG_ LSMS_RecordedPathLeft1 : 32|16@1+ (0.1,0) [0|6553.5] "m"  IC3
 SG_ LSMS_AngleMatch1 : 50|2@1+ (1,0) [0|0] ""  IC3
 SG_ LSMS_LED_IndicationCmd_ISig_4 : 52|2@1+ (1,0) [0|0] ""  IC3
 SG_ LSMS_FunctionState1 : 54|3@1+ (1,0) [0|0] ""  IC3
 SG_ LSMS_JackKnifeWarning1 : 48|2@1+ (1,0) [0|0] ""  IC3

BO_ 1079 DACU_BB2_10P: 8 DACU
 SG_ LSMS_ReqstdArticlatnAngle2_1 : 16|16@1+ (0.0001,-3.14) [-3.14|3.4135] "rad"  IC3
 SG_ LSMS_ReqstdArticlatnAngle1_1 : 0|16@1+ (0.0001,-3.14) [-3.14|3.4135] "rad"  IC3
 SG_ LSMS_TrailrArticlatnAngle2_1 : 48|16@1+ (0.0001,-3.14) [-3.14|3.4135] "rad"  IC3
 SG_ LSMS_TrailrArticlatnAngle1_1 : 32|16@1+ (0.0001,-3.14) [-3.14|3.4135] "rad"  IC3

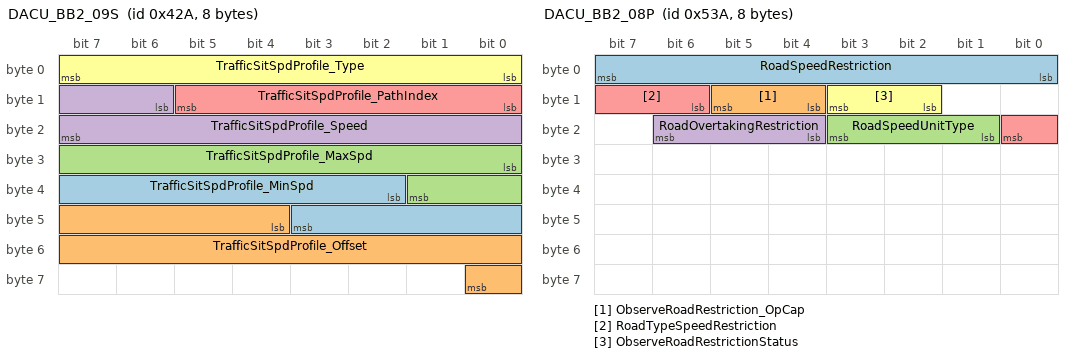
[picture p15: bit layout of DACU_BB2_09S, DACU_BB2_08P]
BO_ 1066 DACU_BB2_09S: 8 DACU
 SG_ TrafficSitSpdProfile_MinSpd : 34|10@1+ (0.25,0) [0|255.75] "Km_per_h"  TECU
 SG_ TrafficSitSpdProfile_Offset : 44|13@1+ (1,0) [0|8191] "m"  TECU
 SG_ TrafficSitSpdProfile_MaxSpd : 24|10@1+ (0.25,0) [0|255.75] "Km_per_h"  TECU
 SG_ TrafficSitSpdProfile_Speed : 14|10@1+ (0.25,0) [0|255.75] "Km_per_h"  TECU
 SG_ TrafficSitSpdProfile_PathIndex : 8|6@1+ (1,0) [0|0] ""  TECU
 SG_ TrafficSitSpdProfile_Type : 0|8@1+ (1,0) [0|0] ""  TECU

BO_ 1338 DACU_BB2_08P: 8 DACU
 SG_ RoadSpeedRestriction : 0|8@1+ (1,0) [0|255] "NotApplicable"  IC3
 SG_ ObserveRoadRestriction_OpCap : 12|2@1+ (1,0) [0|0] ""  IC3
 SG_ RoadSpeedUnitType : 17|3@1+ (1,0) [0|0] ""  IC3
 SG_ RoadOvertakingRestriction : 20|3@1+ (1,0) [0|0] ""  IC3
 SG_ RoadTypeSpeedRestriction : 14|3@1+ (1,0) [0|0] ""  IC3
 SG_ ObserveRoadRestrictionStatus : 10|2@1+ (1,0) [0|0] ""  IC3

BA_DEF_ BO_  "GenMsgStartDelayTime" INT 0 0;
BA_DEF_ BO_  "GenMsgDelayTime" INT 0 0;
BA_DEF_ BO_  "GenMsgCycleTime" INT 0 0;
BA_DEF_ BO_  "GenMsgSendType" ENUM  "Cyclic","NotUsed","NotUsed","NotUsed","NotUsed","NotUsed","NotUsed","IfActive","NoMsgSendType","NotUsed";
BA_DEF_ SG_  "GenSigStartValue" INT 0 0;
BA_DEF_ SG_  "GenSigCycleTimeActive" INT 0 0;
BA_DEF_ SG_  "GenSigCycleTime" INT 0 0;
BA_DEF_ SG_  "GenSigSendType" ENUM  "Cyclic","OnWrite","OnWriteWithRepetition","OnChange","OnChangeWithRepetition","IfActive","IfActiveWithRepetition","NoSigSendType","NotUsed","NotUsed","NotUsed","NotUsed","NotUsed";
BA_DEF_ BO_  "VFrameFormat" ENUM  "StandardCAN","ExtendedCAN","reserved","J1939PG","reserved","reserved","reserved","reserved","reserved","reserved","reserved","reserved","reserved","reserved","StandardCAN_FD","ExtendedCAN_FD";
BA_DEF_ SG_  "SigType" ENUM  "Default","Range","RangeSigned","ASCII","Discrete","Control","ReferencePGN","DTC","StringDelimiter","StringLength","StringLengthControl";
BA_DEF_ SG_  "SeToolVersion_SIGNAL" STRING ;
BA_DEF_ SG_  "SeToolUniqueID_SIGNAL" STRING ;
BA_DEF_ SG_  "SeToolOwnerSigGroup_SIGNAL" STRING ;
BA_DEF_ SG_  "SeToolOwnerSigGroupID_SIGNAL" STRING ;
BA_DEF_ SG_  "SeToolName_SIGNAL" STRING ;
BA_DEF_ SG_  "SeToolItemID_SIGNAL" STRING ;
BA_DEF_ SG_  "SeToolAncestorID_SIGNAL" STRING ;
BA_DEF_ SG_  "Platform_VMCU1_Sig" ENUM  "No","Yes";
BA_DEF_ SG_  "Platform_FactoryIf_Sig" ENUM  "No","Yes";
BA_DEF_ BO_  "NmAsrMessage" ENUM  "No","Yes";
BA_DEF_ SG_  "NeedsUpdateBit" ENUM  "No","Yes";
BA_DEF_ SG_  "MmAnSignal" ENUM  "No","Yes";
BA_DEF_ SG_  "GenSigMaxLatency" INT 0 65535;
BA_DEF_ SG_  "GenSigILSupport" ENUM  "Yes","No";
BA_DEF_ BO_  "GenMsgILSupport" ENUM  "No","Yes";
BA_DEF_ BO_  "DiagUUDTResponse" ENUM  "No","Yes";
BA_DEF_ BO_  "DiagState" ENUM  "No","Yes";
BA_DEF_ BO_  "DiagResponse" ENUM  "No","Yes";
BA_DEF_ BO_  "DiagRequest" ENUM  "No","Yes";
BA_DEF_ BO_  "DiagConnection" HEX 0 65535;
BA_DEF_ BO_  "CanTpSTmin" INT 0 255;
BA_DEF_ BO_  "CanTpFcFrameId" HEX 0 2147483647;
BA_DEF_ BO_  "CanTpBs" INT 0 255;
BA_DEF_ SG_  "SystemSignalLongSymbol" STRING ;
BA_DEF_REL_ BU_SG_REL_  "GenSigTimeoutTime" INT 0 65535;
BA_DEF_REL_ BU_SG_REL_  "GenSigFirstTimeoutTime" INT 0 65535;
BA_DEF_DEF_  "GenMsgStartDelayTime" 0;
BA_DEF_DEF_  "GenMsgDelayTime" 0;
BA_DEF_DEF_  "GenMsgCycleTime" 0;
BA_DEF_DEF_  "GenMsgSendType" "Cyclic";
BA_DEF_DEF_  "GenSigStartValue" 0;
BA_DEF_DEF_  "GenSigCycleTimeActive" 0;
BA_DEF_DEF_  "GenSigCycleTime" 0;
BA_DEF_DEF_  "GenSigSendType" "Cyclic";
BA_DEF_DEF_  "VFrameFormat" "ExtendedCAN";
BA_DEF_DEF_  "SigType" "Default";
BA_DEF_DEF_  "SeToolVersion_SIGNAL" "";
BA_DEF_DEF_  "SeToolUniqueID_SIGNAL" "";
BA_DEF_DEF_  "SeToolOwnerSigGroup_SIGNAL" "";
BA_DEF_DEF_  "SeToolOwnerSigGroupID_SIGNAL" "";
BA_DEF_DEF_  "SeToolName_SIGNAL" "";
BA_DEF_DEF_  "SeToolItemID_SIGNAL" "";
BA_DEF_DEF_  "SeToolAncestorID_SIGNAL" "";
BA_DEF_DEF_  "Platform_VMCU1_Sig" "No";
BA_DEF_DEF_  "Platform_FactoryIf_Sig" "No";
BA_DEF_DEF_  "NmAsrMessage" "No";
BA_DEF_DEF_  "NeedsUpdateBit" "No";
BA_DEF_DEF_  "MmAnSignal" "No";
BA_DEF_DEF_  "GenSigMaxLatency" 0;
BA_DEF_DEF_  "GenSigILSupport" "Yes";
BA_DEF_DEF_  "GenMsgILSupport" "Yes";
BA_DEF_DEF_  "DiagUUDTResponse" "No";
BA_DEF_DEF_  "DiagState" "No";
BA_DEF_DEF_  "DiagResponse" "No";
BA_DEF_DEF_  "DiagRequest" "No";
BA_DEF_DEF_  "DiagConnection" 0;
BA_DEF_DEF_  "CanTpSTmin" 0;
BA_DEF_DEF_  "CanTpFcFrameId" 2147483647;
BA_DEF_DEF_  "CanTpBs" 255;
BA_DEF_DEF_REL_ "GenSigTimeoutTime" 0;
BA_DEF_DEF_REL_ "GenSigFirstTimeoutTime" 0;
BA_DEF_DEF_  "SystemSignalLongSymbol" "";
BA_ "DiagConnection" BO_ 2671813364 62626;
BA_ "DiagRequest" BO_ 2671813364 1;
BA_ "GenMsgILSupport" BO_ 2671813364 0;
BA_ "GenMsgSendType" BO_ 2671813364 8;
BA_ "DiagConnection" BO_ 2671813108 62625;
BA_ "DiagRequest" BO_ 2671813108 1;
BA_ "GenMsgILSupport" BO_ 2671813108 0;
BA_ "GenMsgSendType" BO_ 2671813108 8;
BA_ "DiagConnection" BO_ 2671812852 62624;
BA_ "DiagRequest" BO_ 2671812852 1;
BA_ "GenMsgILSupport" BO_ 2671812852 0;
BA_ "GenMsgSendType" BO_ 2671812852 8;
BA_ "DiagConnection" BO_ 2671810804 62616;
BA_ "DiagRequest" BO_ 2671810804 1;
BA_ "GenMsgILSupport" BO_ 2671810804 0;
BA_ "GenMsgSendType" BO_ 2671810804 8;
BA_ "DiagConnection" BO_ 2671807732 62604;
BA_ "DiagRequest" BO_ 2671807732 1;
BA_ "GenMsgILSupport" BO_ 2671807732 0;
BA_ "GenMsgSendType" BO_ 2671807732 8;
BA_ "DiagConnection" BO_ 2671801076 62578;
BA_ "DiagRequest" BO_ 2671801076 1;
BA_ "GenMsgILSupport" BO_ 2671801076 0;
BA_ "GenMsgSendType" BO_ 2671801076 8;
BA_ "DiagConnection" BO_ 2671800820 62577;
BA_ "DiagRequest" BO_ 2671800820 1;
BA_ "GenMsgILSupport" BO_ 2671800820 0;
BA_ "GenMsgSendType" BO_ 2671800820 8;
BA_ "DiagConnection" BO_ 2671793140 62547;
BA_ "DiagRequest" BO_ 2671793140 1;
BA_ "GenMsgILSupport" BO_ 2671793140 0;
BA_ "GenMsgSendType" BO_ 2671793140 8;
BA_ "DiagConnection" BO_ 2671792884 62546;
BA_ "DiagRequest" BO_ 2671792884 1;
BA_ "GenMsgILSupport" BO_ 2671792884 0;
BA_ "GenMsgSendType" BO_ 2671792884 8;
BA_ "DiagConnection" BO_ 2671792628 62545;
BA_ "DiagRequest" BO_ 2671792628 1;
BA_ "GenMsgILSupport" BO_ 2671792628 0;
BA_ "GenMsgSendType" BO_ 2671792628 8;
BA_ "DiagConnection" BO_ 2671792372 62544;
BA_ "DiagRequest" BO_ 2671792372 1;
BA_ "GenMsgILSupport" BO_ 2671792372 0;
BA_ "GenMsgSendType" BO_ 2671792372 8;
BA_ "DiagConnection" BO_ 2671788276 62528;
BA_ "DiagRequest" BO_ 2671788276 1;
BA_ "GenMsgILSupport" BO_ 2671788276 0;
BA_ "GenMsgSendType" BO_ 2671788276 8;
BA_ "DiagConnection" BO_ 2671784436 62513;
BA_ "DiagRequest" BO_ 2671784436 1;
BA_ "GenMsgILSupport" BO_ 2671784436 0;
BA_ "GenMsgSendType" BO_ 2671784436 8;
BA_ "DiagConnection" BO_ 2671784180 62512;
BA_ "DiagRequest" BO_ 2671784180 1;
BA_ "GenMsgILSupport" BO_ 2671784180 0;
BA_ "GenMsgSendType" BO_ 2671784180 8;
BA_ "DiagConnection" BO_ 2671781620 62502;
BA_ "DiagRequest" BO_ 2671781620 1;
BA_ "GenMsgILSupport" BO_ 2671781620 0;
BA_ "GenMsgSendType" BO_ 2671781620 8;
BA_ "DiagConnection" BO_ 2671781364 62501;
BA_ "DiagRequest" BO_ 2671781364 1;
BA_ "GenMsgILSupport" BO_ 2671781364 0;
BA_ "GenMsgSendType" BO_ 2671781364 8;
BA_ "DiagConnection" BO_ 2671781108 62500;
BA_ "DiagRequest" BO_ 2671781108 1;
BA_ "GenMsgILSupport" BO_ 2671781108 0;
BA_ "GenMsgSendType" BO_ 2671781108 8;
BA_ "DiagConnection" BO_ 2671780852 62499;
BA_ "DiagRequest" BO_ 2671780852 1;
BA_ "GenMsgILSupport" BO_ 2671780852 0;
BA_ "GenMsgSendType" BO_ 2671780852 8;
BA_ "DiagConnection" BO_ 2671780596 62498;
BA_ "DiagRequest" BO_ 2671780596 1;
BA_ "GenMsgILSupport" BO_ 2671780596 0;
BA_ "GenMsgSendType" BO_ 2671780596 8;
BA_ "DiagConnection" BO_ 2671780340 62497;
BA_ "DiagRequest" BO_ 2671780340 1;
BA_ "GenMsgILSupport" BO_ 2671780340 0;
BA_ "GenMsgSendType" BO_ 2671780340 8;
BA_ "DiagConnection" BO_ 2671780084 62496;
BA_ "DiagRequest" BO_ 2671780084 1;
BA_ "GenMsgILSupport" BO_ 2671780084 0;
BA_ "GenMsgSendType" BO_ 2671780084 8;
BA_ "DiagConnection" BO_ 2671778548 62490;
BA_ "DiagRequest" BO_ 2671778548 1;
BA_ "GenMsgILSupport" BO_ 2671778548 0;
BA_ "GenMsgSendType" BO_ 2671778548 8;
BA_ "DiagConnection" BO_ 2671778036 62488;
BA_ "DiagRequest" BO_ 2671778036 1;
BA_ "GenMsgILSupport" BO_ 2671778036 0;
BA_ "GenMsgSendType" BO_ 2671778036 8;
BA_ "DiagConnection" BO_ 2671775988 62480;
BA_ "DiagRequest" BO_ 2671775988 1;
BA_ "GenMsgILSupport" BO_ 2671775988 0;
BA_ "GenMsgSendType" BO_ 2671775988 8;
BA_ "DiagConnection" BO_ 2671833075 62447;
BA_ "DiagRequest" BO_ 2671833075 1;
BA_ "GenMsgILSupport" BO_ 2671833075 0;
BA_ "GenMsgSendType" BO_ 2671833075 8;
BA_ "DiagConnection" BO_ 2671821555 62402;
BA_ "DiagRequest" BO_ 2671821555 1;
BA_ "GenMsgILSupport" BO_ 2671821555 0;
BA_ "GenMsgSendType" BO_ 2671821555 8;
BA_ "DiagConnection" BO_ 2671814131 62373;
BA_ "DiagRequest" BO_ 2671814131 1;
BA_ "GenMsgILSupport" BO_ 2671814131 0;
BA_ "GenMsgSendType" BO_ 2671814131 8;
BA_ "DiagConnection" BO_ 2671801331 62323;
BA_ "DiagRequest" BO_ 2671801331 1;
BA_ "GenMsgILSupport" BO_ 2671801331 0;
BA_ "GenMsgSendType" BO_ 2671801331 8;
BA_ "DiagConnection" BO_ 2671797747 62309;
BA_ "DiagRequest" BO_ 2671797747 1;
BA_ "GenMsgILSupport" BO_ 2671797747 0;
BA_ "GenMsgSendType" BO_ 2671797747 8;
BA_ "DiagConnection" BO_ 2671786227 62264;
BA_ "DiagRequest" BO_ 2671786227 1;
BA_ "GenMsgILSupport" BO_ 2671786227 0;
BA_ "GenMsgSendType" BO_ 2671786227 8;
BA_ "DiagConnection" BO_ 2671830771 62438;
BA_ "DiagRequest" BO_ 2671830771 1;
BA_ "GenMsgILSupport" BO_ 2671830771 0;
BA_ "GenMsgSendType" BO_ 2671830771 8;
BA_ "DiagConnection" BO_ 2671830515 62437;
BA_ "DiagRequest" BO_ 2671830515 1;
BA_ "GenMsgILSupport" BO_ 2671830515 0;
BA_ "GenMsgSendType" BO_ 2671830515 8;
BA_ "DiagConnection" BO_ 2671821043 62400;
BA_ "DiagRequest" BO_ 2671821043 1;
BA_ "GenMsgILSupport" BO_ 2671821043 0;
BA_ "GenMsgSendType" BO_ 2671821043 8;
BA_ "DiagConnection" BO_ 2671813363 62370;
BA_ "DiagRequest" BO_ 2671813363 1;
BA_ "GenMsgILSupport" BO_ 2671813363 0;
BA_ "GenMsgSendType" BO_ 2671813363 8;
BA_ "DiagConnection" BO_ 2671813107 62369;
BA_ "DiagRequest" BO_ 2671813107 1;
BA_ "GenMsgILSupport" BO_ 2671813107 0;
BA_ "GenMsgSendType" BO_ 2671813107 8;
BA_ "DiagConnection" BO_ 2671812851 62368;
BA_ "DiagRequest" BO_ 2671812851 1;
BA_ "GenMsgILSupport" BO_ 2671812851 0;
BA_ "GenMsgSendType" BO_ 2671812851 8;
BA_ "DiagConnection" BO_ 2671810803 62360;
BA_ "DiagRequest" BO_ 2671810803 1;
BA_ "GenMsgILSupport" BO_ 2671810803 0;
BA_ "GenMsgSendType" BO_ 2671810803 8;
BA_ "DiagConnection" BO_ 2671807731 62348;
BA_ "DiagRequest" BO_ 2671807731 1;
BA_ "GenMsgILSupport" BO_ 2671807731 0;
BA_ "GenMsgSendType" BO_ 2671807731 8;
BA_ "DiagConnection" BO_ 2671801075 62322;
BA_ "DiagRequest" BO_ 2671801075 1;
BA_ "GenMsgILSupport" BO_ 2671801075 0;
BA_ "GenMsgSendType" BO_ 2671801075 8;
BA_ "DiagConnection" BO_ 2671800819 62321;
BA_ "DiagRequest" BO_ 2671800819 1;
BA_ "GenMsgILSupport" BO_ 2671800819 0;
BA_ "GenMsgSendType" BO_ 2671800819 8;
BA_ "DiagConnection" BO_ 2671793139 62291;
BA_ "DiagRequest" BO_ 2671793139 1;
BA_ "GenMsgILSupport" BO_ 2671793139 0;
BA_ "GenMsgSendType" BO_ 2671793139 8;
BA_ "DiagConnection" BO_ 2671792883 62290;
BA_ "DiagRequest" BO_ 2671792883 1;
BA_ "GenMsgILSupport" BO_ 2671792883 0;
BA_ "GenMsgSendType" BO_ 2671792883 8;
BA_ "DiagConnection" BO_ 2671792627 62289;
BA_ "DiagRequest" BO_ 2671792627 1;
BA_ "GenMsgILSupport" BO_ 2671792627 0;
BA_ "GenMsgSendType" BO_ 2671792627 8;
BA_ "DiagConnection" BO_ 2671792371 62288;
BA_ "DiagRequest" BO_ 2671792371 1;
BA_ "GenMsgILSupport" BO_ 2671792371 0;
BA_ "GenMsgSendType" BO_ 2671792371 8;
BA_ "DiagConnection" BO_ 2671788275 62272;
BA_ "DiagRequest" BO_ 2671788275 1;
BA_ "GenMsgILSupport" BO_ 2671788275 0;
BA_ "GenMsgSendType" BO_ 2671788275 8;
BA_ "DiagConnection" BO_ 2671784435 62257;
BA_ "DiagRequest" BO_ 2671784435 1;
BA_ "GenMsgILSupport" BO_ 2671784435 0;
BA_ "GenMsgSendType" BO_ 2671784435 8;
BA_ "DiagConnection" BO_ 2671784179 62256;
BA_ "DiagRequest" BO_ 2671784179 1;
BA_ "GenMsgILSupport" BO_ 2671784179 0;
BA_ "GenMsgSendType" BO_ 2671784179 8;
BA_ "DiagConnection" BO_ 2671781619 62246;
BA_ "DiagRequest" BO_ 2671781619 1;
BA_ "GenMsgILSupport" BO_ 2671781619 0;
BA_ "GenMsgSendType" BO_ 2671781619 8;
BA_ "DiagConnection" BO_ 2671781363 62245;
BA_ "DiagRequest" BO_ 2671781363 1;
BA_ "GenMsgILSupport" BO_ 2671781363 0;
BA_ "GenMsgSendType" BO_ 2671781363 8;
BA_ "DiagConnection" BO_ 2671781107 62244;
BA_ "DiagRequest" BO_ 2671781107 1;
BA_ "GenMsgILSupport" BO_ 2671781107 0;
BA_ "GenMsgSendType" BO_ 2671781107 8;
BA_ "DiagConnection" BO_ 2671780851 62243;
BA_ "DiagRequest" BO_ 2671780851 1;
BA_ "GenMsgILSupport" BO_ 2671780851 0;
BA_ "GenMsgSendType" BO_ 2671780851 8;
BA_ "DiagConnection" BO_ 2671780595 62242;
BA_ "DiagRequest" BO_ 2671780595 1;
BA_ "GenMsgILSupport" BO_ 2671780595 0;
BA_ "GenMsgSendType" BO_ 2671780595 8;
BA_ "DiagConnection" BO_ 2671780339 62241;
BA_ "DiagRequest" BO_ 2671780339 1;
BA_ "GenMsgILSupport" BO_ 2671780339 0;
BA_ "GenMsgSendType" BO_ 2671780339 8;
BA_ "DiagConnection" BO_ 2671780083 62240;
BA_ "DiagRequest" BO_ 2671780083 1;
BA_ "GenMsgILSupport" BO_ 2671780083 0;
BA_ "GenMsgSendType" BO_ 2671780083 8;
BA_ "DiagConnection" BO_ 2671778547 62234;
BA_ "DiagRequest" BO_ 2671778547 1;
BA_ "GenMsgILSupport" BO_ 2671778547 0;
BA_ "GenMsgSendType" BO_ 2671778547 8;
BA_ "DiagConnection" BO_ 2671778035 62232;
BA_ "DiagRequest" BO_ 2671778035 1;
BA_ "GenMsgILSupport" BO_ 2671778035 0;
BA_ "GenMsgSendType" BO_ 2671778035 8;
BA_ "DiagConnection" BO_ 2671775987 62224;
BA_ "DiagRequest" BO_ 2671775987 1;
BA_ "GenMsgILSupport" BO_ 2671775987 0;
BA_ "GenMsgSendType" BO_ 2671775987 8;
BA_ "VFrameFormat" BO_ 1520 0;
BA_ "GenMsgSendType" BO_ 1520 8;
BA_ "GenMsgDelayTime" BO_ 1520 75;
BA_ "VFrameFormat" BO_ 1488 0;
BA_ "GenMsgCycleTime" BO_ 1488 1000;
BA_ "GenMsgDelayTime" BO_ 1488 85;
BA_ "GenMsgStartDelayTime" BO_ 1488 15;
BA_ "VFrameFormat" BO_ 1502 0;
BA_ "GenMsgSendType" BO_ 1502 8;
BA_ "GenMsgDelayTime" BO_ 1502 75;
BA_ "VFrameFormat" BO_ 1519 0;
BA_ "GenMsgCycleTime" BO_ 1519 1000;
BA_ "GenMsgDelayTime" BO_ 1519 85;
BA_ "GenMsgStartDelayTime" BO_ 1519 25;
BA_ "VFrameFormat" BO_ 1517 0;
BA_ "GenMsgSendType" BO_ 1517 8;
BA_ "GenMsgDelayTime" BO_ 1517 75;
BA_ "VFrameFormat" BO_ 1516 0;
BA_ "GenMsgSendType" BO_ 1516 8;
BA_ "GenMsgDelayTime" BO_ 1516 75;
BA_ "VFrameFormat" BO_ 1515 0;
BA_ "GenMsgSendType" BO_ 1515 8;
BA_ "GenMsgDelayTime" BO_ 1515 75;
BA_ "VFrameFormat" BO_ 1514 0;
BA_ "GenMsgSendType" BO_ 1514 8;
BA_ "GenMsgDelayTime" BO_ 1514 75;
BA_ "VFrameFormat" BO_ 1513 0;
BA_ "GenMsgSendType" BO_ 1513 8;
BA_ "GenMsgDelayTime" BO_ 1513 75;
BA_ "VFrameFormat" BO_ 1497 0;
BA_ "GenMsgSendType" BO_ 1497 8;
BA_ "GenMsgDelayTime" BO_ 1497 75;
BA_ "VFrameFormat" BO_ 1496 0;
BA_ "GenMsgSendType" BO_ 1496 8;
BA_ "GenMsgDelayTime" BO_ 1496 75;
BA_ "VFrameFormat" BO_ 1512 0;
BA_ "GenMsgSendType" BO_ 1512 8;
BA_ "GenMsgDelayTime" BO_ 1512 75;
BA_ "VFrameFormat" BO_ 1499 0;
BA_ "GenMsgSendType" BO_ 1499 8;
BA_ "GenMsgDelayTime" BO_ 1499 75;
BA_ "VFrameFormat" BO_ 1491 0;
BA_ "GenMsgSendType" BO_ 1491 8;
BA_ "GenMsgDelayTime" BO_ 1491 75;
BA_ "VFrameFormat" BO_ 1511 0;
BA_ "GenMsgCycleTime" BO_ 1511 1000;
BA_ "GenMsgDelayTime" BO_ 1511 85;
BA_ "GenMsgStartDelayTime" BO_ 1511 25;
BA_ "VFrameFormat" BO_ 1493 0;
BA_ "GenMsgSendType" BO_ 1493 8;
BA_ "GenMsgDelayTime" BO_ 1493 75;
BA_ "VFrameFormat" BO_ 1510 0;
BA_ "GenMsgSendType" BO_ 1510 8;
BA_ "GenMsgDelayTime" BO_ 1510 75;
BA_ "VFrameFormat" BO_ 1509 0;
BA_ "GenMsgCycleTime" BO_ 1509 1000;
BA_ "GenMsgDelayTime" BO_ 1509 85;
BA_ "GenMsgStartDelayTime" BO_ 1509 25;
BA_ "VFrameFormat" BO_ 1508 0;
BA_ "GenMsgCycleTime" BO_ 1508 1000;
BA_ "GenMsgDelayTime" BO_ 1508 85;
BA_ "GenMsgStartDelayTime" BO_ 1508 145;
BA_ "VFrameFormat" BO_ 1507 0;
BA_ "GenMsgSendType" BO_ 1507 8;
BA_ "GenMsgDelayTime" BO_ 1507 75;
BA_ "VFrameFormat" BO_ 1490 0;
BA_ "GenMsgSendType" BO_ 1490 8;
BA_ "GenMsgDelayTime" BO_ 1490 75;
BA_ "VFrameFormat" BO_ 1494 0;
BA_ "GenMsgSendType" BO_ 1494 8;
BA_ "GenMsgDelayTime" BO_ 1494 75;
BA_ "VFrameFormat" BO_ 1506 0;
BA_ "GenMsgCycleTime" BO_ 1506 1000;
BA_ "GenMsgDelayTime" BO_ 1506 85;
BA_ "GenMsgStartDelayTime" BO_ 1506 35;
BA_ "VFrameFormat" BO_ 1505 0;
BA_ "GenMsgSendType" BO_ 1505 8;
BA_ "GenMsgDelayTime" BO_ 1505 85;
BA_ "VFrameFormat" BO_ 1504 0;
BA_ "GenMsgSendType" BO_ 1504 8;
BA_ "GenMsgDelayTime" BO_ 1504 75;
BA_ "VFrameFormat" BO_ 1489 0;
BA_ "GenMsgSendType" BO_ 1489 8;
BA_ "GenMsgDelayTime" BO_ 1489 75;
BA_ "VFrameFormat" BO_ 1919 0;
BA_ "GenMsgSendType" BO_ 1919 8;
BA_ "GenMsgDelayTime" BO_ 1919 15;
BA_ "GenMsgStartDelayTime" BO_ 1919 50;
BA_ "VFrameFormat" BO_ 1972 0;
BA_ "GenMsgSendType" BO_ 1972 8;
BA_ "GenMsgDelayTime" BO_ 1972 20;
BA_ "GenMsgStartDelayTime" BO_ 1972 50;
BA_ "VFrameFormat" BO_ 1918 0;
BA_ "GenMsgSendType" BO_ 1918 8;
BA_ "GenMsgDelayTime" BO_ 1918 15;
BA_ "GenMsgStartDelayTime" BO_ 1918 50;
BA_ "VFrameFormat" BO_ 1976 0;
BA_ "GenMsgSendType" BO_ 1976 8;
BA_ "VFrameFormat" BO_ 1971 0;
BA_ "GenMsgSendType" BO_ 1971 8;
BA_ "GenMsgDelayTime" BO_ 1971 20;
BA_ "GenMsgStartDelayTime" BO_ 1971 50;
BA_ "VFrameFormat" BO_ 1917 0;
BA_ "GenMsgSendType" BO_ 1917 8;
BA_ "GenMsgDelayTime" BO_ 1917 15;
BA_ "GenMsgStartDelayTime" BO_ 1917 50;
BA_ "VFrameFormat" BO_ 1975 0;
BA_ "GenMsgSendType" BO_ 1975 8;
BA_ "VFrameFormat" BO_ 1969 0;
BA_ "GenMsgSendType" BO_ 1969 8;
BA_ "GenMsgDelayTime" BO_ 1969 20;
BA_ "GenMsgStartDelayTime" BO_ 1969 50;
BA_ "VFrameFormat" BO_ 1970 0;
BA_ "GenMsgSendType" BO_ 1970 8;
BA_ "GenMsgDelayTime" BO_ 1970 50;
BA_ "VFrameFormat" BO_ 1963 0;
BA_ "GenMsgSendType" BO_ 1963 8;
BA_ "GenMsgDelayTime" BO_ 1963 40;
BA_ "GenMsgStartDelayTime" BO_ 1963 50;
BA_ "VFrameFormat" BO_ 1916 0;
BA_ "GenMsgSendType" BO_ 1916 8;
BA_ "GenMsgDelayTime" BO_ 1916 15;
BA_ "GenMsgStartDelayTime" BO_ 1916 50;
BA_ "VFrameFormat" BO_ 1878 0;
BA_ "GenMsgSendType" BO_ 1878 8;
BA_ "GenMsgDelayTime" BO_ 1878 50;
BA_ "VFrameFormat" BO_ 1966 0;
BA_ "GenMsgSendType" BO_ 1966 8;
BA_ "GenMsgDelayTime" BO_ 1966 40;
BA_ "GenMsgStartDelayTime" BO_ 1966 50;
BA_ "VFrameFormat" BO_ 1961 0;
BA_ "GenMsgSendType" BO_ 1961 8;
BA_ "GenMsgDelayTime" BO_ 1961 40;
BA_ "GenMsgStartDelayTime" BO_ 1961 50;
BA_ "VFrameFormat" BO_ 1965 0;
BA_ "GenMsgSendType" BO_ 1965 8;
BA_ "GenMsgDelayTime" BO_ 1965 20;
BA_ "GenMsgStartDelayTime" BO_ 1965 50;
BA_ "VFrameFormat" BO_ 1964 0;
BA_ "GenMsgSendType" BO_ 1964 8;
BA_ "GenMsgDelayTime" BO_ 1964 50;
BA_ "GenMsgStartDelayTime" BO_ 1964 50;
BA_ "VFrameFormat" BO_ 1967 0;
BA_ "GenMsgSendType" BO_ 1967 8;
BA_ "GenMsgDelayTime" BO_ 1967 50;
BA_ "GenMsgStartDelayTime" BO_ 1967 50;
BA_ "VFrameFormat" BO_ 1956 0;
BA_ "GenMsgSendType" BO_ 1956 8;
BA_ "GenMsgDelayTime" BO_ 1956 40;
BA_ "GenMsgStartDelayTime" BO_ 1956 50;
BA_ "VFrameFormat" BO_ 1915 0;
BA_ "GenMsgSendType" BO_ 1915 8;
BA_ "GenMsgDelayTime" BO_ 1915 15;
BA_ "GenMsgStartDelayTime" BO_ 1915 50;
BA_ "VFrameFormat" BO_ 1877 0;
BA_ "GenMsgSendType" BO_ 1877 8;
BA_ "GenMsgDelayTime" BO_ 1877 50;
BA_ "VFrameFormat" BO_ 1959 0;
BA_ "GenMsgSendType" BO_ 1959 8;
BA_ "GenMsgDelayTime" BO_ 1959 40;
BA_ "GenMsgStartDelayTime" BO_ 1959 50;
BA_ "VFrameFormat" BO_ 1954 0;
BA_ "GenMsgSendType" BO_ 1954 8;
BA_ "GenMsgDelayTime" BO_ 1954 40;
BA_ "GenMsgStartDelayTime" BO_ 1954 50;
BA_ "VFrameFormat" BO_ 1958 0;
BA_ "GenMsgSendType" BO_ 1958 8;
BA_ "GenMsgDelayTime" BO_ 1958 20;
BA_ "GenMsgStartDelayTime" BO_ 1958 50;
BA_ "VFrameFormat" BO_ 1957 0;
BA_ "GenMsgSendType" BO_ 1957 8;
BA_ "GenMsgDelayTime" BO_ 1957 50;
BA_ "GenMsgStartDelayTime" BO_ 1957 50;
BA_ "VFrameFormat" BO_ 1960 0;
BA_ "GenMsgSendType" BO_ 1960 8;
BA_ "GenMsgDelayTime" BO_ 1960 50;
BA_ "GenMsgStartDelayTime" BO_ 1960 50;
BA_ "VFrameFormat" BO_ 1949 0;
BA_ "GenMsgSendType" BO_ 1949 8;
BA_ "GenMsgDelayTime" BO_ 1949 40;
BA_ "GenMsgStartDelayTime" BO_ 1949 50;
BA_ "VFrameFormat" BO_ 1914 0;
BA_ "GenMsgSendType" BO_ 1914 8;
BA_ "GenMsgDelayTime" BO_ 1914 15;
BA_ "GenMsgStartDelayTime" BO_ 1914 50;
BA_ "VFrameFormat" BO_ 1876 0;
BA_ "GenMsgSendType" BO_ 1876 8;
BA_ "GenMsgDelayTime" BO_ 1876 50;
BA_ "VFrameFormat" BO_ 1952 0;
BA_ "GenMsgSendType" BO_ 1952 8;
BA_ "GenMsgDelayTime" BO_ 1952 40;
BA_ "GenMsgStartDelayTime" BO_ 1952 50;
BA_ "VFrameFormat" BO_ 1947 0;
BA_ "GenMsgSendType" BO_ 1947 8;
BA_ "GenMsgDelayTime" BO_ 1947 40;
BA_ "GenMsgStartDelayTime" BO_ 1947 50;
BA_ "VFrameFormat" BO_ 1951 0;
BA_ "GenMsgSendType" BO_ 1951 8;
BA_ "GenMsgDelayTime" BO_ 1951 20;
BA_ "GenMsgStartDelayTime" BO_ 1951 50;
BA_ "VFrameFormat" BO_ 1950 0;
BA_ "GenMsgSendType" BO_ 1950 8;
BA_ "GenMsgDelayTime" BO_ 1950 50;
BA_ "GenMsgStartDelayTime" BO_ 1950 50;
BA_ "VFrameFormat" BO_ 1953 0;
BA_ "GenMsgSendType" BO_ 1953 8;
BA_ "GenMsgDelayTime" BO_ 1953 50;
BA_ "GenMsgStartDelayTime" BO_ 1953 50;
BA_ "VFrameFormat" BO_ 1942 0;
BA_ "GenMsgSendType" BO_ 1942 8;
BA_ "GenMsgDelayTime" BO_ 1942 40;
BA_ "GenMsgStartDelayTime" BO_ 1942 50;
BA_ "VFrameFormat" BO_ 1897 0;
BA_ "GenMsgSendType" BO_ 1897 8;
BA_ "GenMsgDelayTime" BO_ 1897 5;
BA_ "GenMsgStartDelayTime" BO_ 1897 50;
BA_ "VFrameFormat" BO_ 1875 0;
BA_ "GenMsgSendType" BO_ 1875 8;
BA_ "GenMsgDelayTime" BO_ 1875 50;
BA_ "VFrameFormat" BO_ 1945 0;
BA_ "GenMsgSendType" BO_ 1945 8;
BA_ "GenMsgDelayTime" BO_ 1945 40;
BA_ "GenMsgStartDelayTime" BO_ 1945 50;
BA_ "VFrameFormat" BO_ 1940 0;
BA_ "GenMsgSendType" BO_ 1940 8;
BA_ "GenMsgDelayTime" BO_ 1940 50;
BA_ "GenMsgStartDelayTime" BO_ 1940 50;
BA_ "VFrameFormat" BO_ 1944 0;
BA_ "GenMsgSendType" BO_ 1944 8;
BA_ "GenMsgDelayTime" BO_ 1944 10;
BA_ "VFrameFormat" BO_ 1943 0;
BA_ "GenMsgSendType" BO_ 1943 8;
BA_ "GenMsgDelayTime" BO_ 1943 50;
BA_ "GenMsgStartDelayTime" BO_ 1943 50;
BA_ "VFrameFormat" BO_ 1946 0;
BA_ "GenMsgSendType" BO_ 1946 8;
BA_ "GenMsgDelayTime" BO_ 1946 50;
BA_ "GenMsgStartDelayTime" BO_ 1946 50;
BA_ "VFrameFormat" BO_ 1935 0;
BA_ "GenMsgSendType" BO_ 1935 8;
BA_ "GenMsgDelayTime" BO_ 1935 40;
BA_ "GenMsgStartDelayTime" BO_ 1935 50;
BA_ "VFrameFormat" BO_ 1896 0;
BA_ "GenMsgSendType" BO_ 1896 8;
BA_ "GenMsgDelayTime" BO_ 1896 5;
BA_ "GenMsgStartDelayTime" BO_ 1896 50;
BA_ "VFrameFormat" BO_ 1874 0;
BA_ "GenMsgSendType" BO_ 1874 8;
BA_ "GenMsgDelayTime" BO_ 1874 50;
BA_ "VFrameFormat" BO_ 1938 0;
BA_ "GenMsgSendType" BO_ 1938 8;
BA_ "GenMsgDelayTime" BO_ 1938 40;
BA_ "GenMsgStartDelayTime" BO_ 1938 50;
BA_ "VFrameFormat" BO_ 1933 0;
BA_ "GenMsgSendType" BO_ 1933 8;
BA_ "GenMsgDelayTime" BO_ 1933 50;
BA_ "GenMsgStartDelayTime" BO_ 1933 50;
BA_ "VFrameFormat" BO_ 1937 0;
BA_ "GenMsgSendType" BO_ 1937 8;
BA_ "GenMsgDelayTime" BO_ 1937 10;
BA_ "VFrameFormat" BO_ 1936 0;
BA_ "GenMsgSendType" BO_ 1936 8;
BA_ "GenMsgDelayTime" BO_ 1936 50;
BA_ "GenMsgStartDelayTime" BO_ 1936 50;
BA_ "VFrameFormat" BO_ 1939 0;
BA_ "GenMsgSendType" BO_ 1939 8;
BA_ "GenMsgDelayTime" BO_ 1939 50;
BA_ "GenMsgStartDelayTime" BO_ 1939 50;
BA_ "VFrameFormat" BO_ 1968 0;
BA_ "GenMsgSendType" BO_ 1968 8;
BA_ "GenMsgDelayTime" BO_ 1968 155;
BA_ "GenMsgStartDelayTime" BO_ 1968 50;
BA_ "VFrameFormat" BO_ 1962 0;
BA_ "GenMsgSendType" BO_ 1962 8;
BA_ "GenMsgDelayTime" BO_ 1962 155;
BA_ "GenMsgStartDelayTime" BO_ 1962 50;
BA_ "VFrameFormat" BO_ 1928 0;
BA_ "VFrameFormat" BO_ 1927 0;
BA_ "VFrameFormat" BO_ 1873 0;
BA_ "VFrameFormat" BO_ 1931 0;
BA_ "VFrameFormat" BO_ 1926 0;
BA_ "VFrameFormat" BO_ 1930 0;
BA_ "VFrameFormat" BO_ 1929 0;
BA_ "VFrameFormat" BO_ 1932 0;
BA_ "VFrameFormat" BO_ 1955 0;
BA_ "GenMsgSendType" BO_ 1955 8;
BA_ "GenMsgDelayTime" BO_ 1955 4995;
BA_ "GenMsgStartDelayTime" BO_ 1955 50;
BA_ "VFrameFormat" BO_ 1948 0;
BA_ "GenMsgSendType" BO_ 1948 8;
BA_ "GenMsgDelayTime" BO_ 1948 995;
BA_ "GenMsgStartDelayTime" BO_ 1948 50;
BA_ "VFrameFormat" BO_ 1941 0;
BA_ "GenMsgSendType" BO_ 1941 8;
BA_ "GenMsgDelayTime" BO_ 1941 155;
BA_ "GenMsgStartDelayTime" BO_ 1941 50;
BA_ "VFrameFormat" BO_ 1934 0;
BA_ "GenMsgSendType" BO_ 1934 8;
BA_ "GenMsgDelayTime" BO_ 1934 155;
BA_ "GenMsgStartDelayTime" BO_ 1934 50;
BA_ "VFrameFormat" BO_ 1925 0;
BA_ "GenMsgSendType" BO_ 1925 8;
BA_ "GenMsgDelayTime" BO_ 1925 155;
BA_ "GenMsgStartDelayTime" BO_ 1925 50;
BA_ "VFrameFormat" BO_ 1924 0;
BA_ "GenMsgSendType" BO_ 1924 8;
BA_ "GenMsgDelayTime" BO_ 1924 155;
BA_ "GenMsgStartDelayTime" BO_ 1924 50;
BA_ "VFrameFormat" BO_ 1923 0;
BA_ "GenMsgSendType" BO_ 1923 8;
BA_ "GenMsgDelayTime" BO_ 1923 155;
BA_ "GenMsgStartDelayTime" BO_ 1923 50;
BA_ "VFrameFormat" BO_ 1922 0;
BA_ "GenMsgSendType" BO_ 1922 8;
BA_ "GenMsgDelayTime" BO_ 1922 155;
BA_ "GenMsgStartDelayTime" BO_ 1922 50;
BA_ "VFrameFormat" BO_ 1921 0;
BA_ "GenMsgSendType" BO_ 1921 8;
BA_ "GenMsgDelayTime" BO_ 1921 155;
BA_ "GenMsgStartDelayTime" BO_ 1921 50;
BA_ "VFrameFormat" BO_ 1974 0;
BA_ "GenMsgSendType" BO_ 1974 8;
BA_ "GenMsgDelayTime" BO_ 1974 20;
BA_ "GenMsgStartDelayTime" BO_ 1974 50;
BA_ "VFrameFormat" BO_ 1920 0;
BA_ "GenMsgSendType" BO_ 1920 8;
BA_ "GenMsgDelayTime" BO_ 1920 15;
BA_ "GenMsgStartDelayTime" BO_ 1920 50;
BA_ "VFrameFormat" BO_ 1973 0;
BA_ "GenMsgSendType" BO_ 1973 8;
BA_ "GenMsgDelayTime" BO_ 1973 20;
BA_ "GenMsgStartDelayTime" BO_ 1973 50;
BA_ "VFrameFormat" BO_ 1191 0;
BA_ "GenMsgCycleTime" BO_ 1191 100;
BA_ "GenMsgStartDelayTime" BO_ 1191 25;
BA_ "VFrameFormat" BO_ 1484 0;
BA_ "GenMsgCycleTime" BO_ 1484 5000;
BA_ "GenMsgStartDelayTime" BO_ 1484 185;
BA_ "VFrameFormat" BO_ 1253 0;
BA_ "GenMsgCycleTime" BO_ 1253 250;
BA_ "GenMsgStartDelayTime" BO_ 1253 70;
BA_ "VFrameFormat" BO_ 1082 0;
BA_ "GenMsgCycleTime" BO_ 1082 100;
BA_ "GenMsgStartDelayTime" BO_ 1082 45;
BA_ "VFrameFormat" BO_ 1079 0;
BA_ "GenMsgCycleTime" BO_ 1079 100;
BA_ "GenMsgStartDelayTime" BO_ 1079 30;
BA_ "VFrameFormat" BO_ 1066 0;
BA_ "GenMsgSendType" BO_ 1066 8;
BA_ "GenMsgDelayTime" BO_ 1066 20;
BA_ "VFrameFormat" BO_ 1338 0;
BA_ "GenMsgCycleTime" BO_ 1338 500;
BA_ "GenMsgStartDelayTime" BO_ 1338 35;
BA_ "GenSigSendType" SG_ 2671813364 InternalTesterDiagSig_A2_F4_ISig 7;
BA_ "Platform_VMCU1_Sig" SG_ 2671813364 InternalTesterDiagSig_A2_F4_ISig 1;
BA_ "SystemSignalLongSymbol" SG_ 2671813364 InternalTesterDiagSig_A2_F4_ISig "InternalTesterDiagSig_A2_F4_ISig_4";
BA_ "GenSigSendType" SG_ 2671813108 InternalTesterDiagSig_A1_F4_ISig 7;
BA_ "Platform_VMCU1_Sig" SG_ 2671813108 InternalTesterDiagSig_A1_F4_ISig 1;
BA_ "SystemSignalLongSymbol" SG_ 2671813108 InternalTesterDiagSig_A1_F4_ISig "InternalTesterDiagSig_A1_F4_ISig_4";
BA_ "GenSigSendType" SG_ 2671812852 InternalTesterDiagSig_A0_F4_ISig 7;
BA_ "Platform_VMCU1_Sig" SG_ 2671812852 InternalTesterDiagSig_A0_F4_ISig 1;
BA_ "SystemSignalLongSymbol" SG_ 2671812852 InternalTesterDiagSig_A0_F4_ISig "InternalTesterDiagSig_A0_F4_ISig_4";
BA_ "GenSigSendType" SG_ 2671810804 InternalTesterDiagSig_98_F4_ISig 7;
BA_ "Platform_VMCU1_Sig" SG_ 2671810804 InternalTesterDiagSig_98_F4_ISig 1;
BA_ "SystemSignalLongSymbol" SG_ 2671810804 InternalTesterDiagSig_98_F4_ISig "InternalTesterDiagSig_98_F4_ISig_4";
BA_ "GenSigSendType" SG_ 2671807732 InternalTesterDiagSig_8C_F4_ISig 7;
BA_ "SystemSignalLongSymbol" SG_ 2671807732 InternalTesterDiagSig_8C_F4_ISig "InternalTesterDiagSig_8C_F4_ISig_4";
BA_ "GenSigSendType" SG_ 2671801076 InternalTesterDiagSig_72_F4_ISig 7;
BA_ "SystemSignalLongSymbol" SG_ 2671801076 InternalTesterDiagSig_72_F4_ISig "InternalTesterDiagSig_72_F4_ISig_4";
BA_ "GenSigSendType" SG_ 2671800820 InternalTesterDiagSig_71_F4_ISig 7;
BA_ "SystemSignalLongSymbol" SG_ 2671800820 InternalTesterDiagSig_71_F4_ISig "InternalTesterDiagSig_71_F4_ISig_4";
BA_ "GenSigSendType" SG_ 2671793140 InternalTesterDiagSig_53_F4_ISig 7;
BA_ "Platform_VMCU1_Sig" SG_ 2671793140 InternalTesterDiagSig_53_F4_ISig 1;
BA_ "SystemSignalLongSymbol" SG_ 2671793140 InternalTesterDiagSig_53_F4_ISig "InternalTesterDiagSig_53_F4_ISig_4";
BA_ "GenSigSendType" SG_ 2671792884 InternalTesterDiagSig_52_F4_ISig 7;
BA_ "Platform_VMCU1_Sig" SG_ 2671792884 InternalTesterDiagSig_52_F4_ISig 1;
BA_ "SystemSignalLongSymbol" SG_ 2671792884 InternalTesterDiagSig_52_F4_ISig "InternalTesterDiagSig_52_F4_ISig_4";
BA_ "GenSigSendType" SG_ 2671792628 InternalTesterDiagSig_51_F4_ISig 7;
BA_ "Platform_VMCU1_Sig" SG_ 2671792628 InternalTesterDiagSig_51_F4_ISig 1;
BA_ "SystemSignalLongSymbol" SG_ 2671792628 InternalTesterDiagSig_51_F4_ISig "InternalTesterDiagSig_51_F4_ISig_4";
BA_ "GenSigSendType" SG_ 2671792372 InternalTesterDiagSig_50_F4_ISig 7;
BA_ "Platform_VMCU1_Sig" SG_ 2671792372 InternalTesterDiagSig_50_F4_ISig 1;
BA_ "SystemSignalLongSymbol" SG_ 2671792372 InternalTesterDiagSig_50_F4_ISig "InternalTesterDiagSig_50_F4_ISig_4";
BA_ "GenSigSendType" SG_ 2671788276 InternalTesterDiagSig_40_F4_ISig 7;
BA_ "Platform_VMCU1_Sig" SG_ 2671788276 InternalTesterDiagSig_40_F4_ISig 1;
BA_ "SystemSignalLongSymbol" SG_ 2671788276 InternalTesterDiagSig_40_F4_ISig "InternalTesterDiagSig_40_F4_ISig_4";
BA_ "GenSigSendType" SG_ 2671784436 InternalTesterDiagSig_31_F4_ISig 7;
BA_ "Platform_VMCU1_Sig" SG_ 2671784436 InternalTesterDiagSig_31_F4_ISig 1;
BA_ "SystemSignalLongSymbol" SG_ 2671784436 InternalTesterDiagSig_31_F4_ISig "InternalTesterDiagSig_31_F4_ISig_4";
BA_ "GenSigSendType" SG_ 2671784180 InternalTesterDiagSig_30_F4_ISig 7;
BA_ "Platform_VMCU1_Sig" SG_ 2671784180 InternalTesterDiagSig_30_F4_ISig 1;
BA_ "SystemSignalLongSymbol" SG_ 2671784180 InternalTesterDiagSig_30_F4_ISig "InternalTesterDiagSig_30_F4_ISig_4";
BA_ "GenSigSendType" SG_ 2671781620 InternalTesterDiagSig_26_F4_ISig 7;
BA_ "Platform_VMCU1_Sig" SG_ 2671781620 InternalTesterDiagSig_26_F4_ISig 1;
BA_ "SystemSignalLongSymbol" SG_ 2671781620 InternalTesterDiagSig_26_F4_ISig "InternalTesterDiagSig_26_F4_ISig_4";
BA_ "GenSigSendType" SG_ 2671781364 InternalTesterDiagSig_25_F4_ISig 7;
BA_ "Platform_VMCU1_Sig" SG_ 2671781364 InternalTesterDiagSig_25_F4_ISig 1;
BA_ "SystemSignalLongSymbol" SG_ 2671781364 InternalTesterDiagSig_25_F4_ISig "InternalTesterDiagSig_25_F4_ISig_4";
BA_ "GenSigSendType" SG_ 2671781108 InternalTesterDiagSig_24_F4_ISig 7;
BA_ "Platform_VMCU1_Sig" SG_ 2671781108 InternalTesterDiagSig_24_F4_ISig 1;
BA_ "SystemSignalLongSymbol" SG_ 2671781108 InternalTesterDiagSig_24_F4_ISig "InternalTesterDiagSig_24_F4_ISig_4";
BA_ "GenSigSendType" SG_ 2671780852 InternalTesterDiagSig_23_F4_ISig 7;
BA_ "Platform_VMCU1_Sig" SG_ 2671780852 InternalTesterDiagSig_23_F4_ISig 1;
BA_ "SystemSignalLongSymbol" SG_ 2671780852 InternalTesterDiagSig_23_F4_ISig "InternalTesterDiagSig_23_F4_ISig_4";
BA_ "GenSigSendType" SG_ 2671780596 InternalTesterDiagSig_22_F4_ISig 7;
BA_ "Platform_VMCU1_Sig" SG_ 2671780596 InternalTesterDiagSig_22_F4_ISig 1;
BA_ "SystemSignalLongSymbol" SG_ 2671780596 InternalTesterDiagSig_22_F4_ISig "InternalTesterDiagSig_22_F4_ISig_4";
BA_ "GenSigSendType" SG_ 2671780340 InternalTesterDiagSig_21_F4_ISig 7;
BA_ "Platform_VMCU1_Sig" SG_ 2671780340 InternalTesterDiagSig_21_F4_ISig 1;
BA_ "SystemSignalLongSymbol" SG_ 2671780340 InternalTesterDiagSig_21_F4_ISig "InternalTesterDiagSig_21_F4_ISig_4";
BA_ "GenSigSendType" SG_ 2671780084 InternalTesterDiagSig_20_F4_ISig 7;
BA_ "Platform_VMCU1_Sig" SG_ 2671780084 InternalTesterDiagSig_20_F4_ISig 1;
BA_ "SystemSignalLongSymbol" SG_ 2671780084 InternalTesterDiagSig_20_F4_ISig "InternalTesterDiagSig_20_F4_ISig_4";
BA_ "GenSigSendType" SG_ 2671778548 InternalTesterDiagSig_1A_F4_ISig 7;
BA_ "SystemSignalLongSymbol" SG_ 2671778548 InternalTesterDiagSig_1A_F4_ISig "InternalTesterDiagSig_1A_F4_ISig_4";
BA_ "GenSigSendType" SG_ 2671778036 InternalTesterDiagSig_18_F4_ISig 7;
BA_ "Platform_VMCU1_Sig" SG_ 2671778036 InternalTesterDiagSig_18_F4_ISig 1;
BA_ "SystemSignalLongSymbol" SG_ 2671778036 InternalTesterDiagSig_18_F4_ISig "InternalTesterDiagSig_18_F4_ISig_4";
BA_ "GenSigSendType" SG_ 2671775988 InternalTesterDiagSig_10_F4_ISig 7;
BA_ "Platform_VMCU1_Sig" SG_ 2671775988 InternalTesterDiagSig_10_F4_ISig 1;
BA_ "SystemSignalLongSymbol" SG_ 2671775988 InternalTesterDiagSig_10_F4_ISig "InternalTesterDiagSig_10_F4_ISig_4";
BA_ "GenSigSendType" SG_ 2671833075 InternalTesterDiagSig_EF_F3 7;
BA_ "GenSigSendType" SG_ 2671821555 InternalTesterDiagSig_C2_F3 7;
BA_ "GenSigCycleTimeActive" SG_ 2671821555 InternalTesterDiagSig_C2_F3 100;
BA_ "GenSigSendType" SG_ 2671814131 InternalTesterDiagSig_A5_F3_ISig 7;
BA_ "SystemSignalLongSymbol" SG_ 2671814131 InternalTesterDiagSig_A5_F3_ISig "InternalTesterDiagSig_A5_F3_ISig_4";
BA_ "GenSigSendType" SG_ 2671801331 InternalTesterDiagSig_73_F3_ISig 7;
BA_ "SystemSignalLongSymbol" SG_ 2671801331 InternalTesterDiagSig_73_F3_ISig "InternalTesterDiagSig_73_F3_ISig_4";
BA_ "GenSigSendType" SG_ 2671797747 InternalTesterDiagSig_65_F3_ISig 7;
BA_ "SystemSignalLongSymbol" SG_ 2671797747 InternalTesterDiagSig_65_F3_ISig "InternalTesterDiagSig_65_F3_ISig_4";
BA_ "GenSigSendType" SG_ 2671786227 InternalTesterDiagSig_38_F3_ISig 7;
BA_ "SystemSignalLongSymbol" SG_ 2671786227 InternalTesterDiagSig_38_F3_ISig "InternalTesterDiagSig_38_F3_ISig_4";
BA_ "GenSigSendType" SG_ 2671830771 InternalTesterDiagSig_E6_F3 7;
BA_ "Platform_VMCU1_Sig" SG_ 2671830771 InternalTesterDiagSig_E6_F3 1;
BA_ "GenSigSendType" SG_ 2671830515 InternalTesterDiagSig_E5_F3_ISig 7;
BA_ "SystemSignalLongSymbol" SG_ 2671830515 InternalTesterDiagSig_E5_F3_ISig "InternalTesterDiagSig_E5_F3_ISig_4";
BA_ "GenSigSendType" SG_ 2671821043 InternalTesterDiagSig_C0_F3_ISig 7;
BA_ "Platform_VMCU1_Sig" SG_ 2671821043 InternalTesterDiagSig_C0_F3_ISig 1;
BA_ "SystemSignalLongSymbol" SG_ 2671821043 InternalTesterDiagSig_C0_F3_ISig "InternalTesterDiagSig_C0_F3_ISig_4";
BA_ "GenSigSendType" SG_ 2671813363 InternalTesterDiagSig_A2_F3_ISig 7;
BA_ "Platform_VMCU1_Sig" SG_ 2671813363 InternalTesterDiagSig_A2_F3_ISig 1;
BA_ "SystemSignalLongSymbol" SG_ 2671813363 InternalTesterDiagSig_A2_F3_ISig "InternalTesterDiagSig_A2_F3_ISig_4";
BA_ "GenSigSendType" SG_ 2671813107 InternalTesterDiagSig_A1_F3_ISig 7;
BA_ "Platform_VMCU1_Sig" SG_ 2671813107 InternalTesterDiagSig_A1_F3_ISig 1;
BA_ "SystemSignalLongSymbol" SG_ 2671813107 InternalTesterDiagSig_A1_F3_ISig "InternalTesterDiagSig_A1_F3_ISig_4";
BA_ "GenSigSendType" SG_ 2671812851 InternalTesterDiagSig_A0_F3_ISig 7;
BA_ "Platform_VMCU1_Sig" SG_ 2671812851 InternalTesterDiagSig_A0_F3_ISig 1;
BA_ "SystemSignalLongSymbol" SG_ 2671812851 InternalTesterDiagSig_A0_F3_ISig "InternalTesterDiagSig_A0_F3_ISig_4";
BA_ "GenSigSendType" SG_ 2671810803 InternalTesterDiagSig_98_F3_ISig 7;
BA_ "Platform_VMCU1_Sig" SG_ 2671810803 InternalTesterDiagSig_98_F3_ISig 1;
BA_ "SystemSignalLongSymbol" SG_ 2671810803 InternalTesterDiagSig_98_F3_ISig "InternalTesterDiagSig_98_F3_ISig_4";
BA_ "GenSigSendType" SG_ 2671807731 InternalTesterDiagSig_8C_F3_ISig 7;
BA_ "SystemSignalLongSymbol" SG_ 2671807731 InternalTesterDiagSig_8C_F3_ISig "InternalTesterDiagSig_8C_F3_ISig_4";
BA_ "GenSigSendType" SG_ 2671801075 InternalTesterDiagSig_72_F3_ISig 7;
BA_ "SystemSignalLongSymbol" SG_ 2671801075 InternalTesterDiagSig_72_F3_ISig "InternalTesterDiagSig_72_F3_ISig_4";
BA_ "GenSigSendType" SG_ 2671800819 InternalTesterDiagSig_71_F3_ISig 7;
BA_ "SystemSignalLongSymbol" SG_ 2671800819 InternalTesterDiagSig_71_F3_ISig "InternalTesterDiagSig_71_F3_ISig_4";
BA_ "GenSigSendType" SG_ 2671793139 InternalTesterDiagSig_53_F3_ISig 7;
BA_ "Platform_VMCU1_Sig" SG_ 2671793139 InternalTesterDiagSig_53_F3_ISig 1;
BA_ "SystemSignalLongSymbol" SG_ 2671793139 InternalTesterDiagSig_53_F3_ISig "InternalTesterDiagSig_53_F3_ISig_4";
BA_ "GenSigSendType" SG_ 2671792883 InternalTesterDiagSig_52_F3_ISig 7;
BA_ "Platform_VMCU1_Sig" SG_ 2671792883 InternalTesterDiagSig_52_F3_ISig 1;
BA_ "SystemSignalLongSymbol" SG_ 2671792883 InternalTesterDiagSig_52_F3_ISig "InternalTesterDiagSig_52_F3_ISig_4";
BA_ "GenSigSendType" SG_ 2671792627 InternalTesterDiagSig_51_F3_ISig 7;
BA_ "Platform_VMCU1_Sig" SG_ 2671792627 InternalTesterDiagSig_51_F3_ISig 1;
BA_ "SystemSignalLongSymbol" SG_ 2671792627 InternalTesterDiagSig_51_F3_ISig "InternalTesterDiagSig_51_F3_ISig_4";
BA_ "GenSigSendType" SG_ 2671792371 InternalTesterDiagSig_50_F3 7;
BA_ "Platform_VMCU1_Sig" SG_ 2671792371 InternalTesterDiagSig_50_F3 1;
BA_ "GenSigSendType" SG_ 2671788275 InternalTesterDiagSig_40_F3 7;
BA_ "Platform_VMCU1_Sig" SG_ 2671788275 InternalTesterDiagSig_40_F3 1;
BA_ "GenSigSendType" SG_ 2671784435 InternalTesterDiagSig_31_F3_ISig 7;
BA_ "Platform_VMCU1_Sig" SG_ 2671784435 InternalTesterDiagSig_31_F3_ISig 1;
BA_ "SystemSignalLongSymbol" SG_ 2671784435 InternalTesterDiagSig_31_F3_ISig "InternalTesterDiagSig_31_F3_ISig_4";
BA_ "GenSigSendType" SG_ 2671784179 InternalTesterDiagSig_30_F3_ISig 7;
BA_ "Platform_VMCU1_Sig" SG_ 2671784179 InternalTesterDiagSig_30_F3_ISig 1;
BA_ "SystemSignalLongSymbol" SG_ 2671784179 InternalTesterDiagSig_30_F3_ISig "InternalTesterDiagSig_30_F3_ISig_4";
BA_ "GenSigSendType" SG_ 2671781619 InternalTesterDiagSig_26_F3_ISig 7;
BA_ "Platform_VMCU1_Sig" SG_ 2671781619 InternalTesterDiagSig_26_F3_ISig 1;
BA_ "SystemSignalLongSymbol" SG_ 2671781619 InternalTesterDiagSig_26_F3_ISig "InternalTesterDiagSig_26_F3_ISig_4";
BA_ "GenSigSendType" SG_ 2671781363 InternalTesterDiagSig_25_F3_ISig 7;
BA_ "Platform_VMCU1_Sig" SG_ 2671781363 InternalTesterDiagSig_25_F3_ISig 1;
BA_ "SystemSignalLongSymbol" SG_ 2671781363 InternalTesterDiagSig_25_F3_ISig "InternalTesterDiagSig_25_F3_ISig_4";
BA_ "GenSigSendType" SG_ 2671781107 InternalTesterDiagSig_24_F3 7;
BA_ "Platform_VMCU1_Sig" SG_ 2671781107 InternalTesterDiagSig_24_F3 1;
BA_ "GenSigSendType" SG_ 2671780851 InternalTesterDiagSig_23_F3_ISig 7;
BA_ "Platform_VMCU1_Sig" SG_ 2671780851 InternalTesterDiagSig_23_F3_ISig 1;
BA_ "SystemSignalLongSymbol" SG_ 2671780851 InternalTesterDiagSig_23_F3_ISig "InternalTesterDiagSig_23_F3_ISig_4";
BA_ "GenSigSendType" SG_ 2671780595 InternalTesterDiagSig_22_F3_ISig 7;
BA_ "Platform_VMCU1_Sig" SG_ 2671780595 InternalTesterDiagSig_22_F3_ISig 1;
BA_ "SystemSignalLongSymbol" SG_ 2671780595 InternalTesterDiagSig_22_F3_ISig "InternalTesterDiagSig_22_F3_ISig_4";
BA_ "GenSigSendType" SG_ 2671780339 InternalTesterDiagSig_21_F3_ISig 7;
BA_ "Platform_VMCU1_Sig" SG_ 2671780339 InternalTesterDiagSig_21_F3_ISig 1;
BA_ "SystemSignalLongSymbol" SG_ 2671780339 InternalTesterDiagSig_21_F3_ISig "InternalTesterDiagSig_21_F3_ISig_4";
BA_ "GenSigSendType" SG_ 2671780083 InternalTesterDiagSig_20_F3_ISig 7;
BA_ "Platform_VMCU1_Sig" SG_ 2671780083 InternalTesterDiagSig_20_F3_ISig 1;
BA_ "SystemSignalLongSymbol" SG_ 2671780083 InternalTesterDiagSig_20_F3_ISig "InternalTesterDiagSig_20_F3_ISig_4";
BA_ "GenSigSendType" SG_ 2671778547 InternalTesterDiagSig_1A_F3_ISig 7;
BA_ "SystemSignalLongSymbol" SG_ 2671778547 InternalTesterDiagSig_1A_F3_ISig "InternalTesterDiagSig_1A_F3_ISig_4";
BA_ "GenSigSendType" SG_ 2671778035 InternalTesterDiagSig_18_F3 7;
BA_ "Platform_VMCU1_Sig" SG_ 2671778035 InternalTesterDiagSig_18_F3 1;
BA_ "GenSigSendType" SG_ 2671775987 InternalTesterDiagSig_10_F3 7;
BA_ "Platform_VMCU1_Sig" SG_ 2671775987 InternalTesterDiagSig_10_F3 1;
BA_ "GenSigSendType" SG_ 1520 DiagFaultStat_WRCS_EcuAdr_ISig_4 1;
BA_ "GenSigStartValue" SG_ 1520 DiagFaultStat_WRCS_EcuAdr_ISig_4 255;
BA_ "NeedsUpdateBit" SG_ 1520 DiagFaultStat_WRCS_EcuAdr_ISig_4 1;
BA_ "Platform_VMCU1_Sig" SG_ 1520 DiagFaultStat_WRCS_EcuAdr_ISig_4 1;
BA_ "GenSigSendType" SG_ 1520 DiagFaultStat_WRCS_sg_UB_ISig_4 7;
BA_ "Platform_VMCU1_Sig" SG_ 1520 DiagFaultStat_WRCS_sg_UB_ISig_4 1;
BA_ "GenSigSendType" SG_ 1520 DiagFaultStat_WRCS_DtcIdB_ISig_4 1;
BA_ "NeedsUpdateBit" SG_ 1520 DiagFaultStat_WRCS_DtcIdB_ISig_4 1;
BA_ "Platform_VMCU1_Sig" SG_ 1520 DiagFaultStat_WRCS_DtcIdB_ISig_4 1;
BA_ "GenSigSendType" SG_ 1520 DiagFaultStat_WRCS_FailTB_ISig_4 1;
BA_ "NeedsUpdateBit" SG_ 1520 DiagFaultStat_WRCS_FailTB_ISig_4 1;
BA_ "Platform_VMCU1_Sig" SG_ 1520 DiagFaultStat_WRCS_FailTB_ISig_4 1;
BA_ "GenSigSendType" SG_ 1520 DiagFaultStat_WRCS_FailTA_ISig_4 1;
BA_ "NeedsUpdateBit" SG_ 1520 DiagFaultStat_WRCS_FailTA_ISig_4 1;
BA_ "Platform_VMCU1_Sig" SG_ 1520 DiagFaultStat_WRCS_FailTA_ISig_4 1;
BA_ "GenSigSendType" SG_ 1520 DiagFaultStat_WRCS_DtcIdA_ISig_4 1;
BA_ "NeedsUpdateBit" SG_ 1520 DiagFaultStat_WRCS_DtcIdA_ISig_4 1;
BA_ "Platform_VMCU1_Sig" SG_ 1520 DiagFaultStat_WRCS_DtcIdA_ISig_4 1;
BA_ "GenSigSendType" SG_ 1488 DiagFaultStat_VMCU_DtcIdA_ISig_4 3;
BA_ "NeedsUpdateBit" SG_ 1488 DiagFaultStat_VMCU_DtcIdA_ISig_4 1;
BA_ "Platform_VMCU1_Sig" SG_ 1488 DiagFaultStat_VMCU_DtcIdA_ISig_4 1;
BA_ "GenSigSendType" SG_ 1488 DiagFaultStat_VMCU_EcuAdr_ISig_4 3;
BA_ "GenSigStartValue" SG_ 1488 DiagFaultStat_VMCU_EcuAdr_ISig_4 255;
BA_ "NeedsUpdateBit" SG_ 1488 DiagFaultStat_VMCU_EcuAdr_ISig_4 1;
BA_ "Platform_VMCU1_Sig" SG_ 1488 DiagFaultStat_VMCU_EcuAdr_ISig_4 1;
BA_ "GenSigSendType" SG_ 1488 DiagFaultStat_VMCU_FailTA_ISig_4 3;
BA_ "NeedsUpdateBit" SG_ 1488 DiagFaultStat_VMCU_FailTA_ISig_4 1;
BA_ "Platform_VMCU1_Sig" SG_ 1488 DiagFaultStat_VMCU_FailTA_ISig_4 1;
BA_ "GenSigSendType" SG_ 1488 DiagFaultStat_VMCU_FailTB_ISig_4 3;
BA_ "NeedsUpdateBit" SG_ 1488 DiagFaultStat_VMCU_FailTB_ISig_4 1;
BA_ "Platform_VMCU1_Sig" SG_ 1488 DiagFaultStat_VMCU_FailTB_ISig_4 1;
BA_ "GenSigSendType" SG_ 1488 DiagFaultStat_VMCU_DtcIdB_ISig_4 3;
BA_ "NeedsUpdateBit" SG_ 1488 DiagFaultStat_VMCU_DtcIdB_ISig_4 1;
BA_ "Platform_VMCU1_Sig" SG_ 1488 DiagFaultStat_VMCU_DtcIdB_ISig_4 1;
BA_ "GenSigSendType" SG_ 1488 DiagFaultStat_VMCU_sg_UB_ISig_4 7;
BA_ "Platform_VMCU1_Sig" SG_ 1488 DiagFaultStat_VMCU_sg_UB_ISig_4 1;
BA_ "GenSigSendType" SG_ 1502 DiagFaultStat_TPM_EcuAdr_ISig_4 1;
BA_ "GenSigStartValue" SG_ 1502 DiagFaultStat_TPM_EcuAdr_ISig_4 255;
BA_ "NeedsUpdateBit" SG_ 1502 DiagFaultStat_TPM_EcuAdr_ISig_4 1;
BA_ "Platform_VMCU1_Sig" SG_ 1502 DiagFaultStat_TPM_EcuAdr_ISig_4 1;
BA_ "GenSigSendType" SG_ 1502 DiagFaultStat_TPM_FailTB_ISig_4 1;
BA_ "NeedsUpdateBit" SG_ 1502 DiagFaultStat_TPM_FailTB_ISig_4 1;
BA_ "Platform_VMCU1_Sig" SG_ 1502 DiagFaultStat_TPM_FailTB_ISig_4 1;
BA_ "GenSigSendType" SG_ 1502 DiagFaultStat_TPM_DtcIdA_ISig_4 1;
BA_ "NeedsUpdateBit" SG_ 1502 DiagFaultStat_TPM_DtcIdA_ISig_4 1;
BA_ "Platform_VMCU1_Sig" SG_ 1502 DiagFaultStat_TPM_DtcIdA_ISig_4 1;
BA_ "GenSigSendType" SG_ 1502 DiagFaultStat_TPM_DtcIdB_ISig_4 1;
BA_ "NeedsUpdateBit" SG_ 1502 DiagFaultStat_TPM_DtcIdB_ISig_4 1;
BA_ "Platform_VMCU1_Sig" SG_ 1502 DiagFaultStat_TPM_DtcIdB_ISig_4 1;
BA_ "GenSigSendType" SG_ 1502 DiagFaultStat_TPM_FailTA_ISig_4 1;
BA_ "NeedsUpdateBit" SG_ 1502 DiagFaultStat_TPM_FailTA_ISig_4 1;
BA_ "Platform_VMCU1_Sig" SG_ 1502 DiagFaultStat_TPM_FailTA_ISig_4 1;
BA_ "GenSigSendType" SG_ 1502 DiagFaultStat_TPM_sg_UB_ISig_4 7;
BA_ "Platform_VMCU1_Sig" SG_ 1502 DiagFaultStat_TPM_sg_UB_ISig_4 1;
BA_ "GenSigSendType" SG_ 1519 DiagFaultStat_TECU_FailTA_ISig_4 3;
BA_ "GenSigMaxLatency" SG_ 1519 DiagFaultStat_TECU_FailTA_ISig_4 85;
BA_ "NeedsUpdateBit" SG_ 1519 DiagFaultStat_TECU_FailTA_ISig_4 1;
BA_ "Platform_VMCU1_Sig" SG_ 1519 DiagFaultStat_TECU_FailTA_ISig_4 1;
BA_ "GenSigSendType" SG_ 1519 DiagFaultStat_TECU_FailTB_ISig_4 3;
BA_ "GenSigMaxLatency" SG_ 1519 DiagFaultStat_TECU_FailTB_ISig_4 85;
BA_ "NeedsUpdateBit" SG_ 1519 DiagFaultStat_TECU_FailTB_ISig_4 1;
BA_ "Platform_VMCU1_Sig" SG_ 1519 DiagFaultStat_TECU_FailTB_ISig_4 1;
BA_ "GenSigSendType" SG_ 1519 DiagFaultStat_TECU_DtcIdA_ISig_4 3;
BA_ "GenSigMaxLatency" SG_ 1519 DiagFaultStat_TECU_DtcIdA_ISig_4 85;
BA_ "NeedsUpdateBit" SG_ 1519 DiagFaultStat_TECU_DtcIdA_ISig_4 1;
BA_ "Platform_VMCU1_Sig" SG_ 1519 DiagFaultStat_TECU_DtcIdA_ISig_4 1;
BA_ "GenSigSendType" SG_ 1519 DiagFaultStat_TECU_EcuAdr_ISig_4 3;
BA_ "GenSigStartValue" SG_ 1519 DiagFaultStat_TECU_EcuAdr_ISig_4 255;
BA_ "GenSigMaxLatency" SG_ 1519 DiagFaultStat_TECU_EcuAdr_ISig_4 85;
BA_ "NeedsUpdateBit" SG_ 1519 DiagFaultStat_TECU_EcuAdr_ISig_4 1;
BA_ "Platform_VMCU1_Sig" SG_ 1519 DiagFaultStat_TECU_EcuAdr_ISig_4 1;
BA_ "GenSigSendType" SG_ 1519 DiagFaultStat_TECU_sg_UB_ISig_4 7;
BA_ "Platform_VMCU1_Sig" SG_ 1519 DiagFaultStat_TECU_sg_UB_ISig_4 1;
BA_ "GenSigSendType" SG_ 1519 DiagFaultStat_TECU_DtcIdB_ISig_4 3;
BA_ "GenSigMaxLatency" SG_ 1519 DiagFaultStat_TECU_DtcIdB_ISig_4 85;
BA_ "NeedsUpdateBit" SG_ 1519 DiagFaultStat_TECU_DtcIdB_ISig_4 1;
BA_ "Platform_VMCU1_Sig" SG_ 1519 DiagFaultStat_TECU_DtcIdB_ISig_4 1;
BA_ "GenSigSendType" SG_ 1517 DiagFaultStat_SRS_DtcIdB_ISig_4 1;
BA_ "NeedsUpdateBit" SG_ 1517 DiagFaultStat_SRS_DtcIdB_ISig_4 1;
BA_ "Platform_VMCU1_Sig" SG_ 1517 DiagFaultStat_SRS_DtcIdB_ISig_4 1;
BA_ "GenSigSendType" SG_ 1517 DiagFaultStat_SRS_sg_UB_ISig_4 7;
BA_ "Platform_VMCU1_Sig" SG_ 1517 DiagFaultStat_SRS_sg_UB_ISig_4 1;
BA_ "GenSigSendType" SG_ 1517 DiagFaultStat_SRS_FailTB_ISig_4 1;
BA_ "NeedsUpdateBit" SG_ 1517 DiagFaultStat_SRS_FailTB_ISig_4 1;
BA_ "Platform_VMCU1_Sig" SG_ 1517 DiagFaultStat_SRS_FailTB_ISig_4 1;
BA_ "GenSigSendType" SG_ 1517 DiagFaultStat_SRS_EcuAdr_ISig_4 1;
BA_ "GenSigStartValue" SG_ 1517 DiagFaultStat_SRS_EcuAdr_ISig_4 255;
BA_ "NeedsUpdateBit" SG_ 1517 DiagFaultStat_SRS_EcuAdr_ISig_4 1;
BA_ "Platform_VMCU1_Sig" SG_ 1517 DiagFaultStat_SRS_EcuAdr_ISig_4 1;
BA_ "GenSigSendType" SG_ 1517 DiagFaultStat_SRS_DtcIdA_ISig_4 1;
BA_ "NeedsUpdateBit" SG_ 1517 DiagFaultStat_SRS_DtcIdA_ISig_4 1;
BA_ "Platform_VMCU1_Sig" SG_ 1517 DiagFaultStat_SRS_DtcIdA_ISig_4 1;
BA_ "GenSigSendType" SG_ 1517 DiagFaultStat_SRS_FailTA_ISig_4 1;
BA_ "NeedsUpdateBit" SG_ 1517 DiagFaultStat_SRS_FailTA_ISig_4 1;
BA_ "Platform_VMCU1_Sig" SG_ 1517 DiagFaultStat_SRS_FailTA_ISig_4 1;
BA_ "GenSigSendType" SG_ 1516 DiagFaultStat_RCIOM_FailTA_ISig_ 1;
BA_ "NeedsUpdateBit" SG_ 1516 DiagFaultStat_RCIOM_FailTA_ISig_ 1;
BA_ "Platform_VMCU1_Sig" SG_ 1516 DiagFaultStat_RCIOM_FailTA_ISig_ 1;
BA_ "SystemSignalLongSymbol" SG_ 1516 DiagFaultStat_RCIOM_FailTA_ISig_ "DiagFaultStat_RCIOM_FailTA_ISig_4";
BA_ "GenSigSendType" SG_ 1516 DiagFaultStat_RCIOM_FailTB_ISig_ 1;
BA_ "NeedsUpdateBit" SG_ 1516 DiagFaultStat_RCIOM_FailTB_ISig_ 1;
BA_ "Platform_VMCU1_Sig" SG_ 1516 DiagFaultStat_RCIOM_FailTB_ISig_ 1;
BA_ "SystemSignalLongSymbol" SG_ 1516 DiagFaultStat_RCIOM_FailTB_ISig_ "DiagFaultStat_RCIOM_FailTB_ISig_4";
BA_ "GenSigSendType" SG_ 1516 DiagFaultStat_RCIOM_DtcIdB_ISig_ 1;
BA_ "NeedsUpdateBit" SG_ 1516 DiagFaultStat_RCIOM_DtcIdB_ISig_ 1;
BA_ "Platform_VMCU1_Sig" SG_ 1516 DiagFaultStat_RCIOM_DtcIdB_ISig_ 1;
BA_ "SystemSignalLongSymbol" SG_ 1516 DiagFaultStat_RCIOM_DtcIdB_ISig_ "DiagFaultStat_RCIOM_DtcIdB_ISig_4";
BA_ "GenSigSendType" SG_ 1516 DiagFaultStat_RCIOM_DtcIdA_ISig_ 1;
BA_ "NeedsUpdateBit" SG_ 1516 DiagFaultStat_RCIOM_DtcIdA_ISig_ 1;
BA_ "Platform_VMCU1_Sig" SG_ 1516 DiagFaultStat_RCIOM_DtcIdA_ISig_ 1;
BA_ "SystemSignalLongSymbol" SG_ 1516 DiagFaultStat_RCIOM_DtcIdA_ISig_ "DiagFaultStat_RCIOM_DtcIdA_ISig_4";
BA_ "GenSigSendType" SG_ 1516 DiagFaultStat_RCIOM_sg_UB_ISig_4 7;
BA_ "Platform_VMCU1_Sig" SG_ 1516 DiagFaultStat_RCIOM_sg_UB_ISig_4 1;
BA_ "GenSigSendType" SG_ 1516 DiagFaultStat_RCIOM_EcuAdr_ISig_ 1;
BA_ "GenSigStartValue" SG_ 1516 DiagFaultStat_RCIOM_EcuAdr_ISig_ 255;
BA_ "NeedsUpdateBit" SG_ 1516 DiagFaultStat_RCIOM_EcuAdr_ISig_ 1;
BA_ "Platform_VMCU1_Sig" SG_ 1516 DiagFaultStat_RCIOM_EcuAdr_ISig_ 1;
BA_ "SystemSignalLongSymbol" SG_ 1516 DiagFaultStat_RCIOM_EcuAdr_ISig_ "DiagFaultStat_RCIOM_EcuAdr_ISig_4";
BA_ "GenSigSendType" SG_ 1515 DiagFaultStat_PDM_EcuAdr_ISig_4 1;
BA_ "GenSigStartValue" SG_ 1515 DiagFaultStat_PDM_EcuAdr_ISig_4 255;
BA_ "NeedsUpdateBit" SG_ 1515 DiagFaultStat_PDM_EcuAdr_ISig_4 1;
BA_ "Platform_VMCU1_Sig" SG_ 1515 DiagFaultStat_PDM_EcuAdr_ISig_4 1;
BA_ "GenSigSendType" SG_ 1515 DiagFaultStat_PDM_DtcIdB_ISig_4 1;
BA_ "NeedsUpdateBit" SG_ 1515 DiagFaultStat_PDM_DtcIdB_ISig_4 1;
BA_ "Platform_VMCU1_Sig" SG_ 1515 DiagFaultStat_PDM_DtcIdB_ISig_4 1;
BA_ "GenSigSendType" SG_ 1515 DiagFaultStat_PDM_sg_UB_ISig_4 7;
BA_ "Platform_VMCU1_Sig" SG_ 1515 DiagFaultStat_PDM_sg_UB_ISig_4 1;
BA_ "GenSigSendType" SG_ 1515 DiagFaultStat_PDM_FailTB_ISig_4 1;
BA_ "NeedsUpdateBit" SG_ 1515 DiagFaultStat_PDM_FailTB_ISig_4 1;
BA_ "Platform_VMCU1_Sig" SG_ 1515 DiagFaultStat_PDM_FailTB_ISig_4 1;
BA_ "GenSigSendType" SG_ 1515 DiagFaultStat_PDM_DtcIdA_ISig_4 1;
BA_ "NeedsUpdateBit" SG_ 1515 DiagFaultStat_PDM_DtcIdA_ISig_4 1;
BA_ "Platform_VMCU1_Sig" SG_ 1515 DiagFaultStat_PDM_DtcIdA_ISig_4 1;
BA_ "GenSigSendType" SG_ 1515 DiagFaultStat_PDM_FailTA_ISig_4 1;
BA_ "NeedsUpdateBit" SG_ 1515 DiagFaultStat_PDM_FailTA_ISig_4 1;
BA_ "Platform_VMCU1_Sig" SG_ 1515 DiagFaultStat_PDM_FailTA_ISig_4 1;
BA_ "GenSigSendType" SG_ 1514 DiagFaultStat_LPOS_DtcIdB_ISig_4 1;
BA_ "NeedsUpdateBit" SG_ 1514 DiagFaultStat_LPOS_DtcIdB_ISig_4 1;
BA_ "Platform_VMCU1_Sig" SG_ 1514 DiagFaultStat_LPOS_DtcIdB_ISig_4 1;
BA_ "GenSigSendType" SG_ 1514 DiagFaultStat_LPOS_FailTB_ISig_4 1;
BA_ "NeedsUpdateBit" SG_ 1514 DiagFaultStat_LPOS_FailTB_ISig_4 1;
BA_ "Platform_VMCU1_Sig" SG_ 1514 DiagFaultStat_LPOS_FailTB_ISig_4 1;
BA_ "GenSigSendType" SG_ 1514 DiagFaultStat_LPOS_DtcIdA_ISig_4 1;
BA_ "NeedsUpdateBit" SG_ 1514 DiagFaultStat_LPOS_DtcIdA_ISig_4 1;
BA_ "Platform_VMCU1_Sig" SG_ 1514 DiagFaultStat_LPOS_DtcIdA_ISig_4 1;
BA_ "GenSigSendType" SG_ 1514 DiagFaultStat_LPOS_FailTA_ISig_4 1;
BA_ "NeedsUpdateBit" SG_ 1514 DiagFaultStat_LPOS_FailTA_ISig_4 1;
BA_ "Platform_VMCU1_Sig" SG_ 1514 DiagFaultStat_LPOS_FailTA_ISig_4 1;
BA_ "GenSigSendType" SG_ 1514 DiagFaultStat_LPOS_sg_UB_ISig_4 7;
BA_ "Platform_VMCU1_Sig" SG_ 1514 DiagFaultStat_LPOS_sg_UB_ISig_4 1;
BA_ "GenSigSendType" SG_ 1514 DiagFaultStat_LPOS_EcuAdr_ISig_4 1;
BA_ "GenSigStartValue" SG_ 1514 DiagFaultStat_LPOS_EcuAdr_ISig_4 255;
BA_ "NeedsUpdateBit" SG_ 1514 DiagFaultStat_LPOS_EcuAdr_ISig_4 1;
BA_ "Platform_VMCU1_Sig" SG_ 1514 DiagFaultStat_LPOS_EcuAdr_ISig_4 1;
BA_ "GenSigSendType" SG_ 1513 DiagFaultStat_LECM_EcuAdr_ISig_4 1;
BA_ "GenSigStartValue" SG_ 1513 DiagFaultStat_LECM_EcuAdr_ISig_4 255;
BA_ "NeedsUpdateBit" SG_ 1513 DiagFaultStat_LECM_EcuAdr_ISig_4 1;
BA_ "Platform_VMCU1_Sig" SG_ 1513 DiagFaultStat_LECM_EcuAdr_ISig_4 1;
BA_ "GenSigSendType" SG_ 1513 DiagFaultStat_LECM_FailTB_ISig_4 1;
BA_ "NeedsUpdateBit" SG_ 1513 DiagFaultStat_LECM_FailTB_ISig_4 1;
BA_ "Platform_VMCU1_Sig" SG_ 1513 DiagFaultStat_LECM_FailTB_ISig_4 1;
BA_ "GenSigSendType" SG_ 1513 DiagFaultStat_LECM_FailTA_ISig_4 1;
BA_ "NeedsUpdateBit" SG_ 1513 DiagFaultStat_LECM_FailTA_ISig_4 1;
BA_ "Platform_VMCU1_Sig" SG_ 1513 DiagFaultStat_LECM_FailTA_ISig_4 1;
BA_ "GenSigSendType" SG_ 1513 DiagFaultStat_LECM_sg_UB_ISig_4 7;
BA_ "Platform_VMCU1_Sig" SG_ 1513 DiagFaultStat_LECM_sg_UB_ISig_4 1;
BA_ "GenSigSendType" SG_ 1513 DiagFaultStat_LECM_DtcIdB_ISig_4 1;
BA_ "NeedsUpdateBit" SG_ 1513 DiagFaultStat_LECM_DtcIdB_ISig_4 1;
BA_ "Platform_VMCU1_Sig" SG_ 1513 DiagFaultStat_LECM_DtcIdB_ISig_4 1;
BA_ "GenSigSendType" SG_ 1513 DiagFaultStat_LECM_DtcIdA_ISig_4 1;
BA_ "NeedsUpdateBit" SG_ 1513 DiagFaultStat_LECM_DtcIdA_ISig_4 1;
BA_ "Platform_VMCU1_Sig" SG_ 1513 DiagFaultStat_LECM_DtcIdA_ISig_4 1;
BA_ "GenSigSendType" SG_ 1497 DiagFaultStat_GFHCM2_DtcIdB_ISig 1;
BA_ "NeedsUpdateBit" SG_ 1497 DiagFaultStat_GFHCM2_DtcIdB_ISig 1;
BA_ "SystemSignalLongSymbol" SG_ 1497 DiagFaultStat_GFHCM2_DtcIdB_ISig "DiagFaultStat_GFHCM2_DtcIdB_ISig_4";
BA_ "GenSigSendType" SG_ 1497 DiagFaultStat_GFHCM2_sg_UB_ISig_ 7;
BA_ "SystemSignalLongSymbol" SG_ 1497 DiagFaultStat_GFHCM2_sg_UB_ISig_ "DiagFaultStat_GFHCM2_sg_UB_ISig_4";
BA_ "GenSigSendType" SG_ 1497 DiagFaultStat_GFHCM2_DtcIdA_ISig 1;
BA_ "NeedsUpdateBit" SG_ 1497 DiagFaultStat_GFHCM2_DtcIdA_ISig 1;
BA_ "SystemSignalLongSymbol" SG_ 1497 DiagFaultStat_GFHCM2_DtcIdA_ISig "DiagFaultStat_GFHCM2_DtcIdA_ISig_4";
BA_ "GenSigSendType" SG_ 1497 DiagFaultStat_GFHCM2_FailTA_ISig 1;
BA_ "NeedsUpdateBit" SG_ 1497 DiagFaultStat_GFHCM2_FailTA_ISig 1;
BA_ "SystemSignalLongSymbol" SG_ 1497 DiagFaultStat_GFHCM2_FailTA_ISig "DiagFaultStat_GFHCM2_FailTA_ISig_4";
BA_ "GenSigSendType" SG_ 1497 DiagFaultStat_GFHCM2_EcuAdr_ISig 1;
BA_ "GenSigStartValue" SG_ 1497 DiagFaultStat_GFHCM2_EcuAdr_ISig 255;
BA_ "NeedsUpdateBit" SG_ 1497 DiagFaultStat_GFHCM2_EcuAdr_ISig 1;
BA_ "SystemSignalLongSymbol" SG_ 1497 DiagFaultStat_GFHCM2_EcuAdr_ISig "DiagFaultStat_GFHCM2_EcuAdr_ISig_4";
BA_ "GenSigSendType" SG_ 1497 DiagFaultStat_GFHCM2_FailTB_ISig 1;
BA_ "NeedsUpdateBit" SG_ 1497 DiagFaultStat_GFHCM2_FailTB_ISig 1;
BA_ "SystemSignalLongSymbol" SG_ 1497 DiagFaultStat_GFHCM2_FailTB_ISig "DiagFaultStat_GFHCM2_FailTB_ISig_4";
BA_ "GenSigSendType" SG_ 1496 DiagFaultStat_GFHCM1_DtcIdA_ISig 1;
BA_ "NeedsUpdateBit" SG_ 1496 DiagFaultStat_GFHCM1_DtcIdA_ISig 1;
BA_ "SystemSignalLongSymbol" SG_ 1496 DiagFaultStat_GFHCM1_DtcIdA_ISig "DiagFaultStat_GFHCM1_DtcIdA_ISig_4";
BA_ "GenSigSendType" SG_ 1496 DiagFaultStat_GFHCM1_FailTB_ISig 1;
BA_ "NeedsUpdateBit" SG_ 1496 DiagFaultStat_GFHCM1_FailTB_ISig 1;
BA_ "SystemSignalLongSymbol" SG_ 1496 DiagFaultStat_GFHCM1_FailTB_ISig "DiagFaultStat_GFHCM1_FailTB_ISig_4";
BA_ "GenSigSendType" SG_ 1496 DiagFaultStat_GFHCM1_FailTA_ISig 1;
BA_ "NeedsUpdateBit" SG_ 1496 DiagFaultStat_GFHCM1_FailTA_ISig 1;
BA_ "SystemSignalLongSymbol" SG_ 1496 DiagFaultStat_GFHCM1_FailTA_ISig "DiagFaultStat_GFHCM1_FailTA_ISig_4";
BA_ "GenSigSendType" SG_ 1496 DiagFaultStat_GFHCM1_sg_UB_ISig_ 7;
BA_ "SystemSignalLongSymbol" SG_ 1496 DiagFaultStat_GFHCM1_sg_UB_ISig_ "DiagFaultStat_GFHCM1_sg_UB_ISig_4";
BA_ "GenSigSendType" SG_ 1496 DiagFaultStat_GFHCM1_EcuAdr_ISig 1;
BA_ "GenSigStartValue" SG_ 1496 DiagFaultStat_GFHCM1_EcuAdr_ISig 255;
BA_ "NeedsUpdateBit" SG_ 1496 DiagFaultStat_GFHCM1_EcuAdr_ISig 1;
BA_ "SystemSignalLongSymbol" SG_ 1496 DiagFaultStat_GFHCM1_EcuAdr_ISig "DiagFaultStat_GFHCM1_EcuAdr_ISig_4";
BA_ "GenSigSendType" SG_ 1496 DiagFaultStat_GFHCM1_DtcIdB_ISig 1;
BA_ "NeedsUpdateBit" SG_ 1496 DiagFaultStat_GFHCM1_DtcIdB_ISig 1;
BA_ "SystemSignalLongSymbol" SG_ 1496 DiagFaultStat_GFHCM1_DtcIdB_ISig "DiagFaultStat_GFHCM1_DtcIdB_ISig_4";
BA_ "GenSigSendType" SG_ 1512 DiagFaultStat_FLS_DtcIdB_ISig_4 1;
BA_ "NeedsUpdateBit" SG_ 1512 DiagFaultStat_FLS_DtcIdB_ISig_4 1;
BA_ "Platform_VMCU1_Sig" SG_ 1512 DiagFaultStat_FLS_DtcIdB_ISig_4 1;
BA_ "GenSigSendType" SG_ 1512 DiagFaultStat_FLS_FailTB_ISig_4 1;
BA_ "NeedsUpdateBit" SG_ 1512 DiagFaultStat_FLS_FailTB_ISig_4 1;
BA_ "Platform_VMCU1_Sig" SG_ 1512 DiagFaultStat_FLS_FailTB_ISig_4 1;
BA_ "GenSigSendType" SG_ 1512 DiagFaultStat_FLS_DtcIdA_ISig_4 1;
BA_ "NeedsUpdateBit" SG_ 1512 DiagFaultStat_FLS_DtcIdA_ISig_4 1;
BA_ "Platform_VMCU1_Sig" SG_ 1512 DiagFaultStat_FLS_DtcIdA_ISig_4 1;
BA_ "GenSigSendType" SG_ 1512 DiagFaultStat_FLS_sg_UB_ISig_4 7;
BA_ "Platform_VMCU1_Sig" SG_ 1512 DiagFaultStat_FLS_sg_UB_ISig_4 1;
BA_ "GenSigSendType" SG_ 1512 DiagFaultStat_FLS_EcuAdr_ISig_4 1;
BA_ "GenSigStartValue" SG_ 1512 DiagFaultStat_FLS_EcuAdr_ISig_4 255;
BA_ "NeedsUpdateBit" SG_ 1512 DiagFaultStat_FLS_EcuAdr_ISig_4 1;
BA_ "Platform_VMCU1_Sig" SG_ 1512 DiagFaultStat_FLS_EcuAdr_ISig_4 1;
BA_ "GenSigSendType" SG_ 1512 DiagFaultStat_FLS_FailTA_ISig_4 1;
BA_ "NeedsUpdateBit" SG_ 1512 DiagFaultStat_FLS_FailTA_ISig_4 1;
BA_ "Platform_VMCU1_Sig" SG_ 1512 DiagFaultStat_FLS_FailTA_ISig_4 1;
BA_ "GenSigSendType" SG_ 1499 DiagFaultStat_FCIOM_DtcIdB_ISig_ 1;
BA_ "NeedsUpdateBit" SG_ 1499 DiagFaultStat_FCIOM_DtcIdB_ISig_ 1;
BA_ "Platform_VMCU1_Sig" SG_ 1499 DiagFaultStat_FCIOM_DtcIdB_ISig_ 1;
BA_ "SystemSignalLongSymbol" SG_ 1499 DiagFaultStat_FCIOM_DtcIdB_ISig_ "DiagFaultStat_FCIOM_DtcIdB_ISig_4";
BA_ "GenSigSendType" SG_ 1499 DiagFaultStat_FCIOM_sg_UB_ISig_4 7;
BA_ "Platform_VMCU1_Sig" SG_ 1499 DiagFaultStat_FCIOM_sg_UB_ISig_4 1;
BA_ "GenSigSendType" SG_ 1499 DiagFaultStat_FCIOM_FailTA_ISig_ 1;
BA_ "NeedsUpdateBit" SG_ 1499 DiagFaultStat_FCIOM_FailTA_ISig_ 1;
BA_ "Platform_VMCU1_Sig" SG_ 1499 DiagFaultStat_FCIOM_FailTA_ISig_ 1;
BA_ "SystemSignalLongSymbol" SG_ 1499 DiagFaultStat_FCIOM_FailTA_ISig_ "DiagFaultStat_FCIOM_FailTA_ISig_4";
BA_ "GenSigSendType" SG_ 1499 DiagFaultStat_FCIOM_FailTB_ISig_ 1;
BA_ "NeedsUpdateBit" SG_ 1499 DiagFaultStat_FCIOM_FailTB_ISig_ 1;
BA_ "Platform_VMCU1_Sig" SG_ 1499 DiagFaultStat_FCIOM_FailTB_ISig_ 1;
BA_ "SystemSignalLongSymbol" SG_ 1499 DiagFaultStat_FCIOM_FailTB_ISig_ "DiagFaultStat_FCIOM_FailTB_ISig_4";
BA_ "GenSigSendType" SG_ 1499 DiagFaultStat_FCIOM_EcuAdr_ISig_ 1;
BA_ "GenSigStartValue" SG_ 1499 DiagFaultStat_FCIOM_EcuAdr_ISig_ 255;
BA_ "NeedsUpdateBit" SG_ 1499 DiagFaultStat_FCIOM_EcuAdr_ISig_ 1;
BA_ "Platform_VMCU1_Sig" SG_ 1499 DiagFaultStat_FCIOM_EcuAdr_ISig_ 1;
BA_ "SystemSignalLongSymbol" SG_ 1499 DiagFaultStat_FCIOM_EcuAdr_ISig_ "DiagFaultStat_FCIOM_EcuAdr_ISig_4";
BA_ "GenSigSendType" SG_ 1499 DiagFaultStat_FCIOM_DtcIdA_ISig_ 1;
BA_ "NeedsUpdateBit" SG_ 1499 DiagFaultStat_FCIOM_DtcIdA_ISig_ 1;
BA_ "Platform_VMCU1_Sig" SG_ 1499 DiagFaultStat_FCIOM_DtcIdA_ISig_ 1;
BA_ "SystemSignalLongSymbol" SG_ 1499 DiagFaultStat_FCIOM_DtcIdA_ISig_ "DiagFaultStat_FCIOM_DtcIdA_ISig_4";
BA_ "GenSigSendType" SG_ 1491 DiagFaultStat_FAS_FailTA_ISig_4 1;
BA_ "NeedsUpdateBit" SG_ 1491 DiagFaultStat_FAS_FailTA_ISig_4 1;
BA_ "Platform_VMCU1_Sig" SG_ 1491 DiagFaultStat_FAS_FailTA_ISig_4 1;
BA_ "GenSigSendType" SG_ 1491 DiagFaultStat_FAS_DtcIdA_ISig_4 1;
BA_ "NeedsUpdateBit" SG_ 1491 DiagFaultStat_FAS_DtcIdA_ISig_4 1;
BA_ "Platform_VMCU1_Sig" SG_ 1491 DiagFaultStat_FAS_DtcIdA_ISig_4 1;
BA_ "GenSigSendType" SG_ 1491 DiagFaultStat_FAS_FailTB_ISig_4 1;
BA_ "NeedsUpdateBit" SG_ 1491 DiagFaultStat_FAS_FailTB_ISig_4 1;
BA_ "Platform_VMCU1_Sig" SG_ 1491 DiagFaultStat_FAS_FailTB_ISig_4 1;
BA_ "GenSigSendType" SG_ 1491 DiagFaultStat_FAS_EcuAdr_ISig_4 1;
BA_ "GenSigStartValue" SG_ 1491 DiagFaultStat_FAS_EcuAdr_ISig_4 255;
BA_ "NeedsUpdateBit" SG_ 1491 DiagFaultStat_FAS_EcuAdr_ISig_4 1;
BA_ "Platform_VMCU1_Sig" SG_ 1491 DiagFaultStat_FAS_EcuAdr_ISig_4 1;
BA_ "GenSigSendType" SG_ 1491 DiagFaultStat_FAS_sg_UB_ISig_4 7;
BA_ "Platform_VMCU1_Sig" SG_ 1491 DiagFaultStat_FAS_sg_UB_ISig_4 1;
BA_ "GenSigSendType" SG_ 1491 DiagFaultStat_FAS_DtcIdB_ISig_4 1;
BA_ "NeedsUpdateBit" SG_ 1491 DiagFaultStat_FAS_DtcIdB_ISig_4 1;
BA_ "Platform_VMCU1_Sig" SG_ 1491 DiagFaultStat_FAS_DtcIdB_ISig_4 1;
BA_ "GenSigSendType" SG_ 1511 DiagFaultStat_EMS_EcuAdr_ISig_4 3;
BA_ "GenSigStartValue" SG_ 1511 DiagFaultStat_EMS_EcuAdr_ISig_4 255;
BA_ "GenSigMaxLatency" SG_ 1511 DiagFaultStat_EMS_EcuAdr_ISig_4 85;
BA_ "NeedsUpdateBit" SG_ 1511 DiagFaultStat_EMS_EcuAdr_ISig_4 1;
BA_ "Platform_VMCU1_Sig" SG_ 1511 DiagFaultStat_EMS_EcuAdr_ISig_4 1;
BA_ "GenSigSendType" SG_ 1511 DiagFaultStat_EMS_DtcIdB_ISig_4 3;
BA_ "GenSigMaxLatency" SG_ 1511 DiagFaultStat_EMS_DtcIdB_ISig_4 85;
BA_ "NeedsUpdateBit" SG_ 1511 DiagFaultStat_EMS_DtcIdB_ISig_4 1;
BA_ "Platform_VMCU1_Sig" SG_ 1511 DiagFaultStat_EMS_DtcIdB_ISig_4 1;
BA_ "GenSigSendType" SG_ 1511 DiagFaultStat_EMS_DtcIdA_ISig_4 3;
BA_ "GenSigMaxLatency" SG_ 1511 DiagFaultStat_EMS_DtcIdA_ISig_4 85;
BA_ "NeedsUpdateBit" SG_ 1511 DiagFaultStat_EMS_DtcIdA_ISig_4 1;
BA_ "Platform_VMCU1_Sig" SG_ 1511 DiagFaultStat_EMS_DtcIdA_ISig_4 1;
BA_ "GenSigSendType" SG_ 1511 DiagFaultStat_EMS_sg_UB_ISig_4 7;
BA_ "Platform_VMCU1_Sig" SG_ 1511 DiagFaultStat_EMS_sg_UB_ISig_4 1;
BA_ "GenSigSendType" SG_ 1511 DiagFaultStat_EMS_FailTB_ISig_4 3;
BA_ "GenSigMaxLatency" SG_ 1511 DiagFaultStat_EMS_FailTB_ISig_4 85;
BA_ "NeedsUpdateBit" SG_ 1511 DiagFaultStat_EMS_FailTB_ISig_4 1;
BA_ "Platform_VMCU1_Sig" SG_ 1511 DiagFaultStat_EMS_FailTB_ISig_4 1;
BA_ "GenSigSendType" SG_ 1511 DiagFaultStat_EMS_FailTA_ISig_4 3;
BA_ "GenSigMaxLatency" SG_ 1511 DiagFaultStat_EMS_FailTA_ISig_4 85;
BA_ "NeedsUpdateBit" SG_ 1511 DiagFaultStat_EMS_FailTA_ISig_4 1;
BA_ "Platform_VMCU1_Sig" SG_ 1511 DiagFaultStat_EMS_FailTA_ISig_4 1;
BA_ "GenSigSendType" SG_ 1493 DiagFaultStat_EAS_DtcIdB_ISig_4 1;
BA_ "NeedsUpdateBit" SG_ 1493 DiagFaultStat_EAS_DtcIdB_ISig_4 1;
BA_ "Platform_VMCU1_Sig" SG_ 1493 DiagFaultStat_EAS_DtcIdB_ISig_4 1;
BA_ "GenSigSendType" SG_ 1493 DiagFaultStat_EAS_DtcIdA_ISig_4 1;
BA_ "NeedsUpdateBit" SG_ 1493 DiagFaultStat_EAS_DtcIdA_ISig_4 1;
BA_ "Platform_VMCU1_Sig" SG_ 1493 DiagFaultStat_EAS_DtcIdA_ISig_4 1;
BA_ "GenSigSendType" SG_ 1493 DiagFaultStat_EAS_sg_UB_ISig_4 7;
BA_ "Platform_VMCU1_Sig" SG_ 1493 DiagFaultStat_EAS_sg_UB_ISig_4 1;
BA_ "GenSigSendType" SG_ 1493 DiagFaultStat_EAS_FailTB_ISig_4 1;
BA_ "NeedsUpdateBit" SG_ 1493 DiagFaultStat_EAS_FailTB_ISig_4 1;
BA_ "Platform_VMCU1_Sig" SG_ 1493 DiagFaultStat_EAS_FailTB_ISig_4 1;
BA_ "GenSigSendType" SG_ 1493 DiagFaultStat_EAS_FailTA_ISig_4 1;
BA_ "NeedsUpdateBit" SG_ 1493 DiagFaultStat_EAS_FailTA_ISig_4 1;
BA_ "Platform_VMCU1_Sig" SG_ 1493 DiagFaultStat_EAS_FailTA_ISig_4 1;
BA_ "GenSigSendType" SG_ 1493 DiagFaultStat_EAS_EcuAdr_ISig_4 1;
BA_ "GenSigStartValue" SG_ 1493 DiagFaultStat_EAS_EcuAdr_ISig_4 255;
BA_ "NeedsUpdateBit" SG_ 1493 DiagFaultStat_EAS_EcuAdr_ISig_4 1;
BA_ "Platform_VMCU1_Sig" SG_ 1493 DiagFaultStat_EAS_EcuAdr_ISig_4 1;
BA_ "GenSigSendType" SG_ 1510 DiagFaultStat_DDM_DtcIdA_ISig_4 1;
BA_ "NeedsUpdateBit" SG_ 1510 DiagFaultStat_DDM_DtcIdA_ISig_4 1;
BA_ "Platform_VMCU1_Sig" SG_ 1510 DiagFaultStat_DDM_DtcIdA_ISig_4 1;
BA_ "GenSigSendType" SG_ 1510 DiagFaultStat_DDM_sg_UB_ISig_4 7;
BA_ "Platform_VMCU1_Sig" SG_ 1510 DiagFaultStat_DDM_sg_UB_ISig_4 1;
BA_ "GenSigSendType" SG_ 1510 DiagFaultStat_DDM_FailTA_ISig_4 1;
BA_ "NeedsUpdateBit" SG_ 1510 DiagFaultStat_DDM_FailTA_ISig_4 1;
BA_ "Platform_VMCU1_Sig" SG_ 1510 DiagFaultStat_DDM_FailTA_ISig_4 1;
BA_ "GenSigSendType" SG_ 1510 DiagFaultStat_DDM_EcuAdr_ISig_4 1;
BA_ "GenSigStartValue" SG_ 1510 DiagFaultStat_DDM_EcuAdr_ISig_4 255;
BA_ "NeedsUpdateBit" SG_ 1510 DiagFaultStat_DDM_EcuAdr_ISig_4 1;
BA_ "Platform_VMCU1_Sig" SG_ 1510 DiagFaultStat_DDM_EcuAdr_ISig_4 1;
BA_ "GenSigSendType" SG_ 1510 DiagFaultStat_DDM_FailTB_ISig_4 1;
BA_ "NeedsUpdateBit" SG_ 1510 DiagFaultStat_DDM_FailTB_ISig_4 1;
BA_ "Platform_VMCU1_Sig" SG_ 1510 DiagFaultStat_DDM_FailTB_ISig_4 1;
BA_ "GenSigSendType" SG_ 1510 DiagFaultStat_DDM_DtcIdB_ISig_4 1;
BA_ "NeedsUpdateBit" SG_ 1510 DiagFaultStat_DDM_DtcIdB_ISig_4 1;
BA_ "Platform_VMCU1_Sig" SG_ 1510 DiagFaultStat_DDM_DtcIdB_ISig_4 1;
BA_ "GenSigSendType" SG_ 1509 DiagFaultStat_DACU_DtcIdB_ISig_4 3;
BA_ "NeedsUpdateBit" SG_ 1509 DiagFaultStat_DACU_DtcIdB_ISig_4 1;
BA_ "Platform_VMCU1_Sig" SG_ 1509 DiagFaultStat_DACU_DtcIdB_ISig_4 1;
BA_ "GenSigSendType" SG_ 1509 DiagFaultStat_DACU_DtcIdA_ISig_4 3;
BA_ "NeedsUpdateBit" SG_ 1509 DiagFaultStat_DACU_DtcIdA_ISig_4 1;
BA_ "Platform_VMCU1_Sig" SG_ 1509 DiagFaultStat_DACU_DtcIdA_ISig_4 1;
BA_ "GenSigSendType" SG_ 1509 DiagFaultStat_DACU_EcuAdr_ISig_4 3;
BA_ "GenSigStartValue" SG_ 1509 DiagFaultStat_DACU_EcuAdr_ISig_4 255;
BA_ "NeedsUpdateBit" SG_ 1509 DiagFaultStat_DACU_EcuAdr_ISig_4 1;
BA_ "Platform_VMCU1_Sig" SG_ 1509 DiagFaultStat_DACU_EcuAdr_ISig_4 1;
BA_ "GenSigSendType" SG_ 1509 DiagFaultStat_DACU_FailTB_ISig_4 3;
BA_ "NeedsUpdateBit" SG_ 1509 DiagFaultStat_DACU_FailTB_ISig_4 1;
BA_ "Platform_VMCU1_Sig" SG_ 1509 DiagFaultStat_DACU_FailTB_ISig_4 1;
BA_ "GenSigSendType" SG_ 1509 DiagFaultStat_DACU_FailTA_ISig_4 3;
BA_ "NeedsUpdateBit" SG_ 1509 DiagFaultStat_DACU_FailTA_ISig_4 1;
BA_ "Platform_VMCU1_Sig" SG_ 1509 DiagFaultStat_DACU_FailTA_ISig_4 1;
BA_ "GenSigSendType" SG_ 1509 DiagFaultStat_DACU_sg_UB_ISig_4 7;
BA_ "Platform_VMCU1_Sig" SG_ 1509 DiagFaultStat_DACU_sg_UB_ISig_4 1;
BA_ "GenSigSendType" SG_ 1508 DiagFaultStat_CIOM_DtcIdA_ISig_4 3;
BA_ "NeedsUpdateBit" SG_ 1508 DiagFaultStat_CIOM_DtcIdA_ISig_4 1;
BA_ "Platform_VMCU1_Sig" SG_ 1508 DiagFaultStat_CIOM_DtcIdA_ISig_4 1;
BA_ "GenSigSendType" SG_ 1508 DiagFaultStat_CIOM_EcuAdr_ISig_4 3;
BA_ "GenSigStartValue" SG_ 1508 DiagFaultStat_CIOM_EcuAdr_ISig_4 255;
BA_ "NeedsUpdateBit" SG_ 1508 DiagFaultStat_CIOM_EcuAdr_ISig_4 1;
BA_ "Platform_VMCU1_Sig" SG_ 1508 DiagFaultStat_CIOM_EcuAdr_ISig_4 1;
BA_ "GenSigSendType" SG_ 1508 DiagFaultStat_CIOM_sg_UB_ISig_4 7;
BA_ "Platform_VMCU1_Sig" SG_ 1508 DiagFaultStat_CIOM_sg_UB_ISig_4 1;
BA_ "GenSigSendType" SG_ 1508 DiagFaultStat_CIOM_DtcIdB_ISig_4 3;
BA_ "NeedsUpdateBit" SG_ 1508 DiagFaultStat_CIOM_DtcIdB_ISig_4 1;
BA_ "Platform_VMCU1_Sig" SG_ 1508 DiagFaultStat_CIOM_DtcIdB_ISig_4 1;
BA_ "GenSigSendType" SG_ 1508 DiagFaultStat_CIOM_FailTA_ISig_4 3;
BA_ "NeedsUpdateBit" SG_ 1508 DiagFaultStat_CIOM_FailTA_ISig_4 1;
BA_ "Platform_VMCU1_Sig" SG_ 1508 DiagFaultStat_CIOM_FailTA_ISig_4 1;
BA_ "GenSigSendType" SG_ 1508 DiagFaultStat_CIOM_FailTB_ISig_4 3;
BA_ "NeedsUpdateBit" SG_ 1508 DiagFaultStat_CIOM_FailTB_ISig_4 1;
BA_ "Platform_VMCU1_Sig" SG_ 1508 DiagFaultStat_CIOM_FailTB_ISig_4 1;
BA_ "GenSigSendType" SG_ 1507 DiagFaultStat_CCM_FailTB_ISig_4 1;
BA_ "NeedsUpdateBit" SG_ 1507 DiagFaultStat_CCM_FailTB_ISig_4 1;
BA_ "Platform_VMCU1_Sig" SG_ 1507 DiagFaultStat_CCM_FailTB_ISig_4 1;
BA_ "GenSigSendType" SG_ 1507 DiagFaultStat_CCM_DtcIdA_ISig_4 1;
BA_ "NeedsUpdateBit" SG_ 1507 DiagFaultStat_CCM_DtcIdA_ISig_4 1;
BA_ "Platform_VMCU1_Sig" SG_ 1507 DiagFaultStat_CCM_DtcIdA_ISig_4 1;
BA_ "GenSigSendType" SG_ 1507 DiagFaultStat_CCM_DtcIdB_ISig_4 1;
BA_ "NeedsUpdateBit" SG_ 1507 DiagFaultStat_CCM_DtcIdB_ISig_4 1;
BA_ "Platform_VMCU1_Sig" SG_ 1507 DiagFaultStat_CCM_DtcIdB_ISig_4 1;
BA_ "GenSigSendType" SG_ 1507 DiagFaultStat_CCM_EcuAdr_ISig_4 1;
BA_ "GenSigStartValue" SG_ 1507 DiagFaultStat_CCM_EcuAdr_ISig_4 255;
BA_ "NeedsUpdateBit" SG_ 1507 DiagFaultStat_CCM_EcuAdr_ISig_4 1;
BA_ "Platform_VMCU1_Sig" SG_ 1507 DiagFaultStat_CCM_EcuAdr_ISig_4 1;
BA_ "GenSigSendType" SG_ 1507 DiagFaultStat_CCM_FailTA_ISig_4 1;
BA_ "NeedsUpdateBit" SG_ 1507 DiagFaultStat_CCM_FailTA_ISig_4 1;
BA_ "Platform_VMCU1_Sig" SG_ 1507 DiagFaultStat_CCM_FailTA_ISig_4 1;
BA_ "GenSigSendType" SG_ 1507 DiagFaultStat_CCM_sg_UB_ISig_4 7;
BA_ "Platform_VMCU1_Sig" SG_ 1507 DiagFaultStat_CCM_sg_UB_ISig_4 1;
BA_ "GenSigSendType" SG_ 1490 DiagFaultStat_CCIOM_sg_UB_ISig_4 7;
BA_ "Platform_VMCU1_Sig" SG_ 1490 DiagFaultStat_CCIOM_sg_UB_ISig_4 1;
BA_ "GenSigSendType" SG_ 1490 DiagFaultStat_CCIOM_EcuAdr_ISig_ 1;
BA_ "GenSigStartValue" SG_ 1490 DiagFaultStat_CCIOM_EcuAdr_ISig_ 255;
BA_ "NeedsUpdateBit" SG_ 1490 DiagFaultStat_CCIOM_EcuAdr_ISig_ 1;
BA_ "Platform_VMCU1_Sig" SG_ 1490 DiagFaultStat_CCIOM_EcuAdr_ISig_ 1;
BA_ "SystemSignalLongSymbol" SG_ 1490 DiagFaultStat_CCIOM_EcuAdr_ISig_ "DiagFaultStat_CCIOM_EcuAdr_ISig_4";
BA_ "GenSigSendType" SG_ 1490 DiagFaultStat_CCIOM_FailTA_ISig_ 1;
BA_ "NeedsUpdateBit" SG_ 1490 DiagFaultStat_CCIOM_FailTA_ISig_ 1;
BA_ "Platform_VMCU1_Sig" SG_ 1490 DiagFaultStat_CCIOM_FailTA_ISig_ 1;
BA_ "SystemSignalLongSymbol" SG_ 1490 DiagFaultStat_CCIOM_FailTA_ISig_ "DiagFaultStat_CCIOM_FailTA_ISig_4";
BA_ "GenSigSendType" SG_ 1490 DiagFaultStat_CCIOM_DtcIdB_ISig_ 1;
BA_ "NeedsUpdateBit" SG_ 1490 DiagFaultStat_CCIOM_DtcIdB_ISig_ 1;
BA_ "Platform_VMCU1_Sig" SG_ 1490 DiagFaultStat_CCIOM_DtcIdB_ISig_ 1;
BA_ "SystemSignalLongSymbol" SG_ 1490 DiagFaultStat_CCIOM_DtcIdB_ISig_ "DiagFaultStat_CCIOM_DtcIdB_ISig_4";
BA_ "GenSigSendType" SG_ 1490 DiagFaultStat_CCIOM_DtcIdA_ISig_ 1;
BA_ "NeedsUpdateBit" SG_ 1490 DiagFaultStat_CCIOM_DtcIdA_ISig_ 1;
BA_ "Platform_VMCU1_Sig" SG_ 1490 DiagFaultStat_CCIOM_DtcIdA_ISig_ 1;
BA_ "SystemSignalLongSymbol" SG_ 1490 DiagFaultStat_CCIOM_DtcIdA_ISig_ "DiagFaultStat_CCIOM_DtcIdA_ISig_4";
BA_ "GenSigSendType" SG_ 1490 DiagFaultStat_CCIOM_FailTB_ISig_ 1;
BA_ "NeedsUpdateBit" SG_ 1490 DiagFaultStat_CCIOM_FailTB_ISig_ 1;
BA_ "Platform_VMCU1_Sig" SG_ 1490 DiagFaultStat_CCIOM_FailTB_ISig_ 1;
BA_ "SystemSignalLongSymbol" SG_ 1490 DiagFaultStat_CCIOM_FailTB_ISig_ "DiagFaultStat_CCIOM_FailTB_ISig_4";
BA_ "GenSigSendType" SG_ 1494 DiagFaultStat_BPMU_EcuAdr_ISig_4 1;
BA_ "GenSigStartValue" SG_ 1494 DiagFaultStat_BPMU_EcuAdr_ISig_4 255;
BA_ "NeedsUpdateBit" SG_ 1494 DiagFaultStat_BPMU_EcuAdr_ISig_4 1;
BA_ "GenSigSendType" SG_ 1494 DiagFaultStat_BPMU_sg_UB_ISig_4 7;
BA_ "GenSigSendType" SG_ 1494 DiagFaultStat_BPMU_DtcIdB_ISig_4 1;
BA_ "NeedsUpdateBit" SG_ 1494 DiagFaultStat_BPMU_DtcIdB_ISig_4 1;
BA_ "GenSigSendType" SG_ 1494 DiagFaultStat_BPMU_FailTB_ISig_4 1;
BA_ "NeedsUpdateBit" SG_ 1494 DiagFaultStat_BPMU_FailTB_ISig_4 1;
BA_ "GenSigSendType" SG_ 1494 DiagFaultStat_BPMU_FailTA_ISig_4 1;
BA_ "NeedsUpdateBit" SG_ 1494 DiagFaultStat_BPMU_FailTA_ISig_4 1;
BA_ "GenSigSendType" SG_ 1494 DiagFaultStat_BPMU_DtcIdA_ISig_4 1;
BA_ "NeedsUpdateBit" SG_ 1494 DiagFaultStat_BPMU_DtcIdA_ISig_4 1;
BA_ "GenSigSendType" SG_ 1506 DiagFaultStat_BBM_EcuAdr_ISig_4 3;
BA_ "GenSigStartValue" SG_ 1506 DiagFaultStat_BBM_EcuAdr_ISig_4 255;
BA_ "NeedsUpdateBit" SG_ 1506 DiagFaultStat_BBM_EcuAdr_ISig_4 1;
BA_ "Platform_VMCU1_Sig" SG_ 1506 DiagFaultStat_BBM_EcuAdr_ISig_4 1;
BA_ "GenSigSendType" SG_ 1506 DiagFaultStat_BBM_DtcIdB_ISig_4 3;
BA_ "NeedsUpdateBit" SG_ 1506 DiagFaultStat_BBM_DtcIdB_ISig_4 1;
BA_ "Platform_VMCU1_Sig" SG_ 1506 DiagFaultStat_BBM_DtcIdB_ISig_4 1;
BA_ "GenSigSendType" SG_ 1506 DiagFaultStat_BBM_FailTB_ISig_4 3;
BA_ "NeedsUpdateBit" SG_ 1506 DiagFaultStat_BBM_FailTB_ISig_4 1;
BA_ "Platform_VMCU1_Sig" SG_ 1506 DiagFaultStat_BBM_FailTB_ISig_4 1;
BA_ "GenSigSendType" SG_ 1506 DiagFaultStat_BBM_sg_UB_ISig_4 7;
BA_ "Platform_VMCU1_Sig" SG_ 1506 DiagFaultStat_BBM_sg_UB_ISig_4 1;
BA_ "GenSigSendType" SG_ 1506 DiagFaultStat_BBM_DtcIdA_ISig_4 3;
BA_ "NeedsUpdateBit" SG_ 1506 DiagFaultStat_BBM_DtcIdA_ISig_4 1;
BA_ "Platform_VMCU1_Sig" SG_ 1506 DiagFaultStat_BBM_DtcIdA_ISig_4 1;
BA_ "GenSigSendType" SG_ 1506 DiagFaultStat_BBM_FailTA_ISig_4 3;
BA_ "NeedsUpdateBit" SG_ 1506 DiagFaultStat_BBM_FailTA_ISig_4 1;
BA_ "Platform_VMCU1_Sig" SG_ 1506 DiagFaultStat_BBM_FailTA_ISig_4 1;
BA_ "GenSigSendType" SG_ 1505 DiagFaultStat_BBIOM_sg_UB_ISig_4 7;
BA_ "GenSigMaxLatency" SG_ 1505 DiagFaultStat_BBIOM_sg_UB_ISig_4 1000;
BA_ "GenSigSendType" SG_ 1505 DiagFaultStat_BBIOM_FailTA_ISig_ 1;
BA_ "GenSigCycleTime" SG_ 1505 DiagFaultStat_BBIOM_FailTA_ISig_ 100;
BA_ "GenSigCycleTimeActive" SG_ 1505 DiagFaultStat_BBIOM_FailTA_ISig_ 100;
BA_ "GenSigMaxLatency" SG_ 1505 DiagFaultStat_BBIOM_FailTA_ISig_ 1000;
BA_ "NeedsUpdateBit" SG_ 1505 DiagFaultStat_BBIOM_FailTA_ISig_ 1;
BA_ "SystemSignalLongSymbol" SG_ 1505 DiagFaultStat_BBIOM_FailTA_ISig_ "DiagFaultStat_BBIOM_FailTA_ISig_4";
BA_ "GenSigSendType" SG_ 1505 DiagFaultStat_BBIOM_FailTB_ISig_ 1;
BA_ "GenSigCycleTime" SG_ 1505 DiagFaultStat_BBIOM_FailTB_ISig_ 100;
BA_ "GenSigCycleTimeActive" SG_ 1505 DiagFaultStat_BBIOM_FailTB_ISig_ 100;
BA_ "GenSigMaxLatency" SG_ 1505 DiagFaultStat_BBIOM_FailTB_ISig_ 1000;
BA_ "NeedsUpdateBit" SG_ 1505 DiagFaultStat_BBIOM_FailTB_ISig_ 1;
BA_ "SystemSignalLongSymbol" SG_ 1505 DiagFaultStat_BBIOM_FailTB_ISig_ "DiagFaultStat_BBIOM_FailTB_ISig_4";
BA_ "GenSigSendType" SG_ 1505 DiagFaultStat_BBIOM_DtcIdB_ISig_ 1;
BA_ "GenSigCycleTime" SG_ 1505 DiagFaultStat_BBIOM_DtcIdB_ISig_ 100;
BA_ "GenSigCycleTimeActive" SG_ 1505 DiagFaultStat_BBIOM_DtcIdB_ISig_ 100;
BA_ "GenSigMaxLatency" SG_ 1505 DiagFaultStat_BBIOM_DtcIdB_ISig_ 1000;
BA_ "NeedsUpdateBit" SG_ 1505 DiagFaultStat_BBIOM_DtcIdB_ISig_ 1;
BA_ "SystemSignalLongSymbol" SG_ 1505 DiagFaultStat_BBIOM_DtcIdB_ISig_ "DiagFaultStat_BBIOM_DtcIdB_ISig_4";
BA_ "GenSigSendType" SG_ 1505 DiagFaultStat_BBIOM_DtcIdA_ISig_ 1;
BA_ "GenSigCycleTime" SG_ 1505 DiagFaultStat_BBIOM_DtcIdA_ISig_ 100;
BA_ "GenSigCycleTimeActive" SG_ 1505 DiagFaultStat_BBIOM_DtcIdA_ISig_ 100;
BA_ "GenSigMaxLatency" SG_ 1505 DiagFaultStat_BBIOM_DtcIdA_ISig_ 1000;
BA_ "NeedsUpdateBit" SG_ 1505 DiagFaultStat_BBIOM_DtcIdA_ISig_ 1;
BA_ "SystemSignalLongSymbol" SG_ 1505 DiagFaultStat_BBIOM_DtcIdA_ISig_ "DiagFaultStat_BBIOM_DtcIdA_ISig_4";
BA_ "GenSigSendType" SG_ 1505 DiagFaultStat_BBIOM_EcuAdr_ISig_ 1;
BA_ "GenSigCycleTime" SG_ 1505 DiagFaultStat_BBIOM_EcuAdr_ISig_ 100;
BA_ "GenSigCycleTimeActive" SG_ 1505 DiagFaultStat_BBIOM_EcuAdr_ISig_ 100;
BA_ "GenSigStartValue" SG_ 1505 DiagFaultStat_BBIOM_EcuAdr_ISig_ 255;
BA_ "GenSigMaxLatency" SG_ 1505 DiagFaultStat_BBIOM_EcuAdr_ISig_ 1000;
BA_ "NeedsUpdateBit" SG_ 1505 DiagFaultStat_BBIOM_EcuAdr_ISig_ 1;
BA_ "SystemSignalLongSymbol" SG_ 1505 DiagFaultStat_BBIOM_EcuAdr_ISig_ "DiagFaultStat_BBIOM_EcuAdr_ISig_4";
BA_ "GenSigSendType" SG_ 1504 DiagFaultStat_Alarm_DtcIdA_ISig_ 1;
BA_ "NeedsUpdateBit" SG_ 1504 DiagFaultStat_Alarm_DtcIdA_ISig_ 1;
BA_ "Platform_VMCU1_Sig" SG_ 1504 DiagFaultStat_Alarm_DtcIdA_ISig_ 1;
BA_ "SystemSignalLongSymbol" SG_ 1504 DiagFaultStat_Alarm_DtcIdA_ISig_ "DiagFaultStat_Alarm_DtcIdA_ISig_4";
BA_ "GenSigSendType" SG_ 1504 DiagFaultStat_Alarm_EcuAdr_ISig_ 1;
BA_ "GenSigStartValue" SG_ 1504 DiagFaultStat_Alarm_EcuAdr_ISig_ 255;
BA_ "NeedsUpdateBit" SG_ 1504 DiagFaultStat_Alarm_EcuAdr_ISig_ 1;
BA_ "Platform_VMCU1_Sig" SG_ 1504 DiagFaultStat_Alarm_EcuAdr_ISig_ 1;
BA_ "SystemSignalLongSymbol" SG_ 1504 DiagFaultStat_Alarm_EcuAdr_ISig_ "DiagFaultStat_Alarm_EcuAdr_ISig_4";
BA_ "GenSigSendType" SG_ 1504 DiagFaultStat_Alarm_sg_UB_ISig_4 7;
BA_ "Platform_VMCU1_Sig" SG_ 1504 DiagFaultStat_Alarm_sg_UB_ISig_4 1;
BA_ "GenSigSendType" SG_ 1504 DiagFaultStat_Alarm_FailTB_ISig_ 1;
BA_ "NeedsUpdateBit" SG_ 1504 DiagFaultStat_Alarm_FailTB_ISig_ 1;
BA_ "Platform_VMCU1_Sig" SG_ 1504 DiagFaultStat_Alarm_FailTB_ISig_ 1;
BA_ "SystemSignalLongSymbol" SG_ 1504 DiagFaultStat_Alarm_FailTB_ISig_ "DiagFaultStat_Alarm_FailTB_ISig_4";
BA_ "GenSigSendType" SG_ 1504 DiagFaultStat_Alarm_FailTA_ISig_ 1;
BA_ "NeedsUpdateBit" SG_ 1504 DiagFaultStat_Alarm_FailTA_ISig_ 1;
BA_ "Platform_VMCU1_Sig" SG_ 1504 DiagFaultStat_Alarm_FailTA_ISig_ 1;
BA_ "SystemSignalLongSymbol" SG_ 1504 DiagFaultStat_Alarm_FailTA_ISig_ "DiagFaultStat_Alarm_FailTA_ISig_4";
BA_ "GenSigSendType" SG_ 1504 DiagFaultStat_Alarm_DtcIdB_ISig_ 1;
BA_ "NeedsUpdateBit" SG_ 1504 DiagFaultStat_Alarm_DtcIdB_ISig_ 1;
BA_ "Platform_VMCU1_Sig" SG_ 1504 DiagFaultStat_Alarm_DtcIdB_ISig_ 1;
BA_ "SystemSignalLongSymbol" SG_ 1504 DiagFaultStat_Alarm_DtcIdB_ISig_ "DiagFaultStat_Alarm_DtcIdB_ISig_4";
BA_ "GenSigSendType" SG_ 1489 DiagFaultStat_APM_DtcIdA_ISig_4 1;
BA_ "NeedsUpdateBit" SG_ 1489 DiagFaultStat_APM_DtcIdA_ISig_4 1;
BA_ "Platform_VMCU1_Sig" SG_ 1489 DiagFaultStat_APM_DtcIdA_ISig_4 1;
BA_ "GenSigSendType" SG_ 1489 DiagFaultStat_APM_EcuAdr_ISig_4 1;
BA_ "GenSigStartValue" SG_ 1489 DiagFaultStat_APM_EcuAdr_ISig_4 255;
BA_ "NeedsUpdateBit" SG_ 1489 DiagFaultStat_APM_EcuAdr_ISig_4 1;
BA_ "Platform_VMCU1_Sig" SG_ 1489 DiagFaultStat_APM_EcuAdr_ISig_4 1;
BA_ "GenSigSendType" SG_ 1489 DiagFaultStat_APM_FailTB_ISig_4 1;
BA_ "NeedsUpdateBit" SG_ 1489 DiagFaultStat_APM_FailTB_ISig_4 1;
BA_ "Platform_VMCU1_Sig" SG_ 1489 DiagFaultStat_APM_FailTB_ISig_4 1;
BA_ "GenSigSendType" SG_ 1489 DiagFaultStat_APM_sg_UB_ISig_4 7;
BA_ "Platform_VMCU1_Sig" SG_ 1489 DiagFaultStat_APM_sg_UB_ISig_4 1;
BA_ "GenSigSendType" SG_ 1489 DiagFaultStat_APM_DtcIdB_ISig_4 1;
BA_ "NeedsUpdateBit" SG_ 1489 DiagFaultStat_APM_DtcIdB_ISig_4 1;
BA_ "Platform_VMCU1_Sig" SG_ 1489 DiagFaultStat_APM_DtcIdB_ISig_4 1;
BA_ "GenSigSendType" SG_ 1489 DiagFaultStat_APM_FailTA_ISig_4 1;
BA_ "NeedsUpdateBit" SG_ 1489 DiagFaultStat_APM_FailTA_ISig_4 1;
BA_ "Platform_VMCU1_Sig" SG_ 1489 DiagFaultStat_APM_FailTA_ISig_4 1;
BA_ "GenSigSendType" SG_ 1919 Debug_9_TECU 1;
BA_ "GenSigMaxLatency" SG_ 1919 Debug_9_TECU 55;
BA_ "Platform_VMCU1_Sig" SG_ 1919 Debug_9_TECU 1;
BA_ "GenSigSendType" SG_ 1972 Debug_9_DACU 1;
BA_ "GenSigMaxLatency" SG_ 1972 Debug_9_DACU 25;
BA_ "Platform_VMCU1_Sig" SG_ 1972 Debug_9_DACU 1;
BA_ "GenSigSendType" SG_ 1918 Debug_8_TECU 1;
BA_ "GenSigMaxLatency" SG_ 1918 Debug_8_TECU 55;
BA_ "Platform_VMCU1_Sig" SG_ 1918 Debug_8_TECU 1;
BA_ "GenSigSendType" SG_ 1976 Debug_8_IC_BB2 1;
BA_ "GenSigMaxLatency" SG_ 1976 Debug_8_IC_BB2 55;
BA_ "GenSigSendType" SG_ 1971 Debug_8_DACU 1;
BA_ "GenSigMaxLatency" SG_ 1971 Debug_8_DACU 25;
BA_ "Platform_VMCU1_Sig" SG_ 1971 Debug_8_DACU 1;
BA_ "GenSigSendType" SG_ 1917 Debug_7_TECU 1;
BA_ "GenSigMaxLatency" SG_ 1917 Debug_7_TECU 55;
BA_ "Platform_VMCU1_Sig" SG_ 1917 Debug_7_TECU 1;
BA_ "GenSigSendType" SG_ 1975 Debug_7_IC_BB2 1;
BA_ "GenSigMaxLatency" SG_ 1975 Debug_7_IC_BB2 55;
BA_ "GenSigSendType" SG_ 1969 Debug_7_DACU 1;
BA_ "GenSigMaxLatency" SG_ 1969 Debug_7_DACU 25;
BA_ "Platform_VMCU1_Sig" SG_ 1969 Debug_7_DACU 1;
BA_ "GenSigSendType" SG_ 1970 Debug_7_BBM 1;
BA_ "Platform_VMCU1_Sig" SG_ 1970 Debug_7_BBM 1;
BA_ "GenSigSendType" SG_ 1963 Debug_6_VMCU 1;
BA_ "GenSigMaxLatency" SG_ 1963 Debug_6_VMCU 55;
BA_ "Platform_VMCU1_Sig" SG_ 1963 Debug_6_VMCU 1;
BA_ "GenSigSendType" SG_ 1916 Debug_6_TECU 1;
BA_ "GenSigMaxLatency" SG_ 1916 Debug_6_TECU 55;
BA_ "Platform_VMCU1_Sig" SG_ 1916 Debug_6_TECU 1;
BA_ "GenSigSendType" SG_ 1878 Debug_6_HPCU 1;
BA_ "GenSigSendType" SG_ 1966 Debug_6_HMIIOM 1;
BA_ "GenSigMaxLatency" SG_ 1966 Debug_6_HMIIOM 55;
BA_ "Platform_VMCU1_Sig" SG_ 1966 Debug_6_HMIIOM 1;
BA_ "GenSigSendType" SG_ 1961 Debug_6_EMS 1;
BA_ "GenSigMaxLatency" SG_ 1961 Debug_6_EMS 55;
BA_ "Platform_VMCU1_Sig" SG_ 1961 Debug_6_EMS 1;
BA_ "GenSigSendType" SG_ 1965 Debug_6_DACU 1;
BA_ "GenSigMaxLatency" SG_ 1965 Debug_6_DACU 25;
BA_ "Platform_VMCU1_Sig" SG_ 1965 Debug_6_DACU 1;
BA_ "GenSigSendType" SG_ 1964 Debug_6_CIOM 1;
BA_ "GenSigMaxLatency" SG_ 1964 Debug_6_CIOM 55;
BA_ "Platform_VMCU1_Sig" SG_ 1964 Debug_6_CIOM 1;
BA_ "GenSigSendType" SG_ 1967 Debug_6_BBM 1;
BA_ "GenSigMaxLatency" SG_ 1967 Debug_6_BBM 59;
BA_ "Platform_VMCU1_Sig" SG_ 1967 Debug_6_BBM 1;
BA_ "GenSigSendType" SG_ 1956 Debug_5_VMCU 1;
BA_ "GenSigMaxLatency" SG_ 1956 Debug_5_VMCU 55;
BA_ "Platform_VMCU1_Sig" SG_ 1956 Debug_5_VMCU 1;
BA_ "GenSigSendType" SG_ 1915 Debug_5_TECU 1;
BA_ "GenSigMaxLatency" SG_ 1915 Debug_5_TECU 55;
BA_ "Platform_VMCU1_Sig" SG_ 1915 Debug_5_TECU 1;
BA_ "GenSigSendType" SG_ 1877 Debug_5_HPCU 1;
BA_ "GenSigSendType" SG_ 1959 Debug_5_HMIIOM 1;
BA_ "GenSigMaxLatency" SG_ 1959 Debug_5_HMIIOM 55;
BA_ "Platform_VMCU1_Sig" SG_ 1959 Debug_5_HMIIOM 1;
BA_ "GenSigSendType" SG_ 1954 Debug_5_EMS 1;
BA_ "GenSigMaxLatency" SG_ 1954 Debug_5_EMS 55;
BA_ "Platform_VMCU1_Sig" SG_ 1954 Debug_5_EMS 1;
BA_ "GenSigSendType" SG_ 1958 Debug_5_DACU 1;
BA_ "GenSigMaxLatency" SG_ 1958 Debug_5_DACU 25;
BA_ "Platform_VMCU1_Sig" SG_ 1958 Debug_5_DACU 1;
BA_ "GenSigSendType" SG_ 1957 Debug_5_CIOM 1;
BA_ "GenSigMaxLatency" SG_ 1957 Debug_5_CIOM 55;
BA_ "Platform_VMCU1_Sig" SG_ 1957 Debug_5_CIOM 1;
BA_ "GenSigSendType" SG_ 1960 Debug_5_BBM 1;
BA_ "GenSigMaxLatency" SG_ 1960 Debug_5_BBM 59;
BA_ "Platform_VMCU1_Sig" SG_ 1960 Debug_5_BBM 1;
BA_ "GenSigSendType" SG_ 1949 Debug_4_VMCU 1;
BA_ "GenSigMaxLatency" SG_ 1949 Debug_4_VMCU 55;
BA_ "Platform_VMCU1_Sig" SG_ 1949 Debug_4_VMCU 1;
BA_ "GenSigSendType" SG_ 1914 Debug_4_TECU 1;
BA_ "GenSigMaxLatency" SG_ 1914 Debug_4_TECU 55;
BA_ "Platform_VMCU1_Sig" SG_ 1914 Debug_4_TECU 1;
BA_ "GenSigSendType" SG_ 1876 Debug_4_HPCU 1;
BA_ "GenSigSendType" SG_ 1952 Debug_4_HMIIOM 1;
BA_ "GenSigMaxLatency" SG_ 1952 Debug_4_HMIIOM 55;
BA_ "Platform_VMCU1_Sig" SG_ 1952 Debug_4_HMIIOM 1;
BA_ "GenSigSendType" SG_ 1947 Debug_4_EMS 1;
BA_ "GenSigMaxLatency" SG_ 1947 Debug_4_EMS 55;
BA_ "Platform_VMCU1_Sig" SG_ 1947 Debug_4_EMS 1;
BA_ "GenSigSendType" SG_ 1951 Debug_4_DACU 1;
BA_ "GenSigMaxLatency" SG_ 1951 Debug_4_DACU 25;
BA_ "Platform_VMCU1_Sig" SG_ 1951 Debug_4_DACU 1;
BA_ "GenSigSendType" SG_ 1950 Debug_4_CIOM 1;
BA_ "GenSigMaxLatency" SG_ 1950 Debug_4_CIOM 55;
BA_ "Platform_VMCU1_Sig" SG_ 1950 Debug_4_CIOM 1;
BA_ "GenSigSendType" SG_ 1953 Debug_4_BBM 1;
BA_ "GenSigMaxLatency" SG_ 1953 Debug_4_BBM 59;
BA_ "Platform_VMCU1_Sig" SG_ 1953 Debug_4_BBM 1;
BA_ "GenSigSendType" SG_ 1942 Debug_3_VMCU 1;
BA_ "GenSigMaxLatency" SG_ 1942 Debug_3_VMCU 55;
BA_ "Platform_VMCU1_Sig" SG_ 1942 Debug_3_VMCU 1;
BA_ "GenSigSendType" SG_ 1897 Debug_3_TECU 1;
BA_ "GenSigMaxLatency" SG_ 1897 Debug_3_TECU 55;
BA_ "Platform_VMCU1_Sig" SG_ 1897 Debug_3_TECU 1;
BA_ "GenSigSendType" SG_ 1875 Debug_3_HPCU 1;
BA_ "GenSigSendType" SG_ 1945 Debug_3_HMIIOM 1;
BA_ "GenSigMaxLatency" SG_ 1945 Debug_3_HMIIOM 55;
BA_ "Platform_VMCU1_Sig" SG_ 1945 Debug_3_HMIIOM 1;
BA_ "GenSigSendType" SG_ 1940 Debug_3_EMS 1;
BA_ "GenSigMaxLatency" SG_ 1940 Debug_3_EMS 55;
BA_ "Platform_VMCU1_Sig" SG_ 1940 Debug_3_EMS 1;
BA_ "GenSigSendType" SG_ 1944 Debug_3_DACU 1;
BA_ "GenSigMaxLatency" SG_ 1944 Debug_3_DACU 25;
BA_ "Platform_VMCU1_Sig" SG_ 1944 Debug_3_DACU 1;
BA_ "GenSigSendType" SG_ 1943 Debug_3_CIOM 1;
BA_ "GenSigMaxLatency" SG_ 1943 Debug_3_CIOM 55;
BA_ "Platform_VMCU1_Sig" SG_ 1943 Debug_3_CIOM 1;
BA_ "GenSigSendType" SG_ 1946 Debug_3_BBM 1;
BA_ "GenSigMaxLatency" SG_ 1946 Debug_3_BBM 59;
BA_ "Platform_VMCU1_Sig" SG_ 1946 Debug_3_BBM 1;
BA_ "GenSigSendType" SG_ 1935 Debug_2_VMCU 1;
BA_ "GenSigMaxLatency" SG_ 1935 Debug_2_VMCU 55;
BA_ "Platform_VMCU1_Sig" SG_ 1935 Debug_2_VMCU 1;
BA_ "GenSigSendType" SG_ 1896 Debug_2_TECU 1;
BA_ "GenSigMaxLatency" SG_ 1896 Debug_2_TECU 55;
BA_ "Platform_VMCU1_Sig" SG_ 1896 Debug_2_TECU 1;
BA_ "GenSigSendType" SG_ 1874 Debug_2_HPCU 1;
BA_ "GenSigSendType" SG_ 1938 Debug_2_HMIIOM 1;
BA_ "GenSigMaxLatency" SG_ 1938 Debug_2_HMIIOM 55;
BA_ "Platform_VMCU1_Sig" SG_ 1938 Debug_2_HMIIOM 1;
BA_ "GenSigSendType" SG_ 1933 Debug_2_EMS 1;
BA_ "GenSigMaxLatency" SG_ 1933 Debug_2_EMS 55;
BA_ "Platform_VMCU1_Sig" SG_ 1933 Debug_2_EMS 1;
BA_ "GenSigSendType" SG_ 1937 Debug_2_DACU 1;
BA_ "GenSigMaxLatency" SG_ 1937 Debug_2_DACU 25;
BA_ "Platform_VMCU1_Sig" SG_ 1937 Debug_2_DACU 1;
BA_ "GenSigSendType" SG_ 1936 Debug_2_CIOM 1;
BA_ "GenSigMaxLatency" SG_ 1936 Debug_2_CIOM 55;
BA_ "Platform_VMCU1_Sig" SG_ 1936 Debug_2_CIOM 1;
BA_ "GenSigSendType" SG_ 1939 Debug_2_BBM 1;
BA_ "GenSigMaxLatency" SG_ 1939 Debug_2_BBM 59;
BA_ "Platform_VMCU1_Sig" SG_ 1939 Debug_2_BBM 1;
BA_ "GenSigSendType" SG_ 1968 Debug_21_TECU 1;
BA_ "Platform_VMCU1_Sig" SG_ 1968 Debug_21_TECU 1;
BA_ "GenSigSendType" SG_ 1962 Debug_20_TECU 1;
BA_ "Platform_VMCU1_Sig" SG_ 1962 Debug_20_TECU 1;
BA_ "GenSigSendType" SG_ 1928 Debug_1_VMCU 1;
BA_ "Platform_VMCU1_Sig" SG_ 1928 Debug_1_VMCU 1;
BA_ "GenSigSendType" SG_ 1927 Debug_1_TECU 1;
BA_ "Platform_VMCU1_Sig" SG_ 1927 Debug_1_TECU 1;
BA_ "GenSigSendType" SG_ 1873 Debug_1_HPCU 1;
BA_ "GenSigSendType" SG_ 1931 Debug_1_HMIIOM 1;
BA_ "Platform_VMCU1_Sig" SG_ 1931 Debug_1_HMIIOM 1;
BA_ "GenSigSendType" SG_ 1926 Debug_1_EMS 1;
BA_ "Platform_VMCU1_Sig" SG_ 1926 Debug_1_EMS 1;
BA_ "GenSigSendType" SG_ 1930 Debug_1_DACU 1;
BA_ "Platform_VMCU1_Sig" SG_ 1930 Debug_1_DACU 1;
BA_ "GenSigSendType" SG_ 1929 Debug_1_CIOM 1;
BA_ "Platform_VMCU1_Sig" SG_ 1929 Debug_1_CIOM 1;
BA_ "GenSigSendType" SG_ 1932 Debug_1_BBM 1;
BA_ "Platform_VMCU1_Sig" SG_ 1932 Debug_1_BBM 1;
BA_ "GenSigSendType" SG_ 1955 Debug_19_TECU 1;
BA_ "Platform_VMCU1_Sig" SG_ 1955 Debug_19_TECU 1;
BA_ "GenSigSendType" SG_ 1948 Debug_18_TECU 1;
BA_ "Platform_VMCU1_Sig" SG_ 1948 Debug_18_TECU 1;
BA_ "GenSigSendType" SG_ 1941 Debug_17_TECU 1;
BA_ "Platform_VMCU1_Sig" SG_ 1941 Debug_17_TECU 1;
BA_ "GenSigSendType" SG_ 1934 Debug_16_TECU 1;
BA_ "Platform_VMCU1_Sig" SG_ 1934 Debug_16_TECU 1;
BA_ "GenSigSendType" SG_ 1925 Debug_15_TECU 1;
BA_ "Platform_VMCU1_Sig" SG_ 1925 Debug_15_TECU 1;
BA_ "GenSigSendType" SG_ 1924 Debug_14_TECU 1;
BA_ "Platform_VMCU1_Sig" SG_ 1924 Debug_14_TECU 1;
BA_ "GenSigSendType" SG_ 1923 Debug_13_TECU 1;
BA_ "GenSigMaxLatency" SG_ 1923 Debug_13_TECU 55;
BA_ "Platform_VMCU1_Sig" SG_ 1923 Debug_13_TECU 1;
BA_ "GenSigSendType" SG_ 1922 Debug_12_TECU 1;
BA_ "GenSigMaxLatency" SG_ 1922 Debug_12_TECU 55;
BA_ "Platform_VMCU1_Sig" SG_ 1922 Debug_12_TECU 1;
BA_ "GenSigSendType" SG_ 1921 Debug_11_TECU 1;
BA_ "GenSigMaxLatency" SG_ 1921 Debug_11_TECU 55;
BA_ "Platform_VMCU1_Sig" SG_ 1921 Debug_11_TECU 1;
BA_ "GenSigSendType" SG_ 1974 Debug_11_DACU 1;
BA_ "GenSigCycleTime" SG_ 1974 Debug_11_DACU 100;
BA_ "GenSigCycleTimeActive" SG_ 1974 Debug_11_DACU 100;
BA_ "Platform_VMCU1_Sig" SG_ 1974 Debug_11_DACU 1;
BA_ "GenSigSendType" SG_ 1920 Debug_10_TECU 1;
BA_ "GenSigMaxLatency" SG_ 1920 Debug_10_TECU 55;
BA_ "Platform_VMCU1_Sig" SG_ 1920 Debug_10_TECU 1;
BA_ "GenSigSendType" SG_ 1973 Debug_10_DACU 1;
BA_ "GenSigMaxLatency" SG_ 1973 Debug_10_DACU 25;
BA_ "Platform_VMCU1_Sig" SG_ 1973 Debug_10_DACU 1;
BA_ "GenSigCycleTime" SG_ 1191 PS_TrafficSitPathEvt1_Type 100;
BA_ "GenSigCycleTimeActive" SG_ 1191 PS_TrafficSitPathEvt1_Type 100;
BA_ "GenSigStartValue" SG_ 1191 PS_TrafficSitPathEvt1_Type 255;
BA_ "GenSigCycleTime" SG_ 1191 PS_TrafficSitPathEvt2_Distance 100;
BA_ "GenSigCycleTimeActive" SG_ 1191 PS_TrafficSitPathEvt2_Distance 100;
BA_ "GenSigStartValue" SG_ 1191 PS_TrafficSitPathEvt2_Distance 16383;
BA_ "GenSigCycleTime" SG_ 1191 PS_TrafficSitPathEvt2_Speed 100;
BA_ "GenSigCycleTimeActive" SG_ 1191 PS_TrafficSitPathEvt2_Speed 100;
BA_ "GenSigStartValue" SG_ 1191 PS_TrafficSitPathEvt2_Speed 1023;
BA_ "GenSigCycleTime" SG_ 1191 PS_TrafficSitPathEvt2_Type 100;
BA_ "GenSigCycleTimeActive" SG_ 1191 PS_TrafficSitPathEvt2_Type 100;
BA_ "GenSigStartValue" SG_ 1191 PS_TrafficSitPathEvt2_Type 255;
BA_ "GenSigCycleTime" SG_ 1191 PS_TrafficSitPathEvt1_Speed 100;
BA_ "GenSigCycleTimeActive" SG_ 1191 PS_TrafficSitPathEvt1_Speed 100;
BA_ "GenSigStartValue" SG_ 1191 PS_TrafficSitPathEvt1_Speed 1023;
BA_ "GenSigCycleTime" SG_ 1191 PS_TrafficSitPathEvt1_Distance 100;
BA_ "GenSigCycleTimeActive" SG_ 1191 PS_TrafficSitPathEvt1_Distance 100;
BA_ "GenSigStartValue" SG_ 1191 PS_TrafficSitPathEvt1_Distance 16383;
BA_ "GenSigCycleTime" SG_ 1484 DACU_Available_Log_ISig_4 100;
BA_ "GenSigCycleTimeActive" SG_ 1484 DACU_Available_Log_ISig_4 100;
BA_ "GenSigStartValue" SG_ 1484 DACU_Available_Log_ISig_4 255;
BA_ "GenSigMaxLatency" SG_ 1484 DACU_Available_Log_ISig_4 5000;
BA_ "GenSigCycleTime" SG_ 1253 LSMS_RevDirSupportUASens1 100;
BA_ "GenSigCycleTimeActive" SG_ 1253 LSMS_RevDirSupportUASens1 100;
BA_ "GenSigStartValue" SG_ 1253 LSMS_RevDirSupportUASens1 7;
BA_ "GenSigCycleTime" SG_ 1253 LSMS_KnbSteerUASens1 100;
BA_ "GenSigCycleTimeActive" SG_ 1253 LSMS_KnbSteerUASens1 100;
BA_ "GenSigStartValue" SG_ 1253 LSMS_KnbSteerUASens1 7;
BA_ "GenSigCycleTime" SG_ 1253 LSMS_RevDirSupportUAPreCon1 100;
BA_ "GenSigCycleTimeActive" SG_ 1253 LSMS_RevDirSupportUAPreCon1 100;
BA_ "GenSigStartValue" SG_ 1253 LSMS_RevDirSupportUAPreCon1 7;
BA_ "GenSigCycleTime" SG_ 1253 LSMS_UndoUAPreCon1 100;
BA_ "GenSigCycleTimeActive" SG_ 1253 LSMS_UndoUAPreCon1 100;
BA_ "GenSigStartValue" SG_ 1253 LSMS_UndoUAPreCon1 7;
BA_ "GenSigCycleTime" SG_ 1253 LSMS_KnbSteerUAPreCon1 100;
BA_ "GenSigCycleTimeActive" SG_ 1253 LSMS_KnbSteerUAPreCon1 100;
BA_ "GenSigStartValue" SG_ 1253 LSMS_KnbSteerUAPreCon1 7;
BA_ "GenSigCycleTime" SG_ 1253 LSMS_UndoUASens1 100;
BA_ "GenSigCycleTimeActive" SG_ 1253 LSMS_UndoUASens1 100;
BA_ "GenSigStartValue" SG_ 1253 LSMS_UndoUASens1 7;
BA_ "GenSigCycleTime" SG_ 1082 LSMS_KnobAngle1 100;
BA_ "GenSigCycleTimeActive" SG_ 1082 LSMS_KnobAngle1 100;
BA_ "GenSigStartValue" SG_ 1082 LSMS_KnobAngle1 65535;
BA_ "GenSigCycleTime" SG_ 1082 FrontRoadWheelAngleEstimate1 100;
BA_ "GenSigCycleTimeActive" SG_ 1082 FrontRoadWheelAngleEstimate1 100;
BA_ "GenSigStartValue" SG_ 1082 FrontRoadWheelAngleEstimate1 65535;
BA_ "GenSigCycleTime" SG_ 1082 LSMS_RecordedPathLeft1 100;
BA_ "GenSigCycleTimeActive" SG_ 1082 LSMS_RecordedPathLeft1 100;
BA_ "GenSigStartValue" SG_ 1082 LSMS_RecordedPathLeft1 65535;
BA_ "GenSigCycleTime" SG_ 1082 LSMS_AngleMatch1 100;
BA_ "GenSigCycleTimeActive" SG_ 1082 LSMS_AngleMatch1 100;
BA_ "GenSigStartValue" SG_ 1082 LSMS_AngleMatch1 3;
BA_ "GenSigCycleTime" SG_ 1082 LSMS_LED_IndicationCmd_ISig_4 100;
BA_ "GenSigCycleTimeActive" SG_ 1082 LSMS_LED_IndicationCmd_ISig_4 100;
BA_ "GenSigStartValue" SG_ 1082 LSMS_LED_IndicationCmd_ISig_4 3;
BA_ "GenSigCycleTime" SG_ 1082 LSMS_FunctionState1 100;
BA_ "GenSigCycleTimeActive" SG_ 1082 LSMS_FunctionState1 100;
BA_ "GenSigStartValue" SG_ 1082 LSMS_FunctionState1 7;
BA_ "GenSigCycleTime" SG_ 1082 LSMS_JackKnifeWarning1 100;
BA_ "GenSigCycleTimeActive" SG_ 1082 LSMS_JackKnifeWarning1 100;
BA_ "GenSigStartValue" SG_ 1082 LSMS_JackKnifeWarning1 3;
BA_ "GenSigCycleTime" SG_ 1079 LSMS_ReqstdArticlatnAngle2_1 100;
BA_ "GenSigCycleTimeActive" SG_ 1079 LSMS_ReqstdArticlatnAngle2_1 100;
BA_ "GenSigStartValue" SG_ 1079 LSMS_ReqstdArticlatnAngle2_1 65535;
BA_ "GenSigCycleTime" SG_ 1079 LSMS_ReqstdArticlatnAngle1_1 100;
BA_ "GenSigCycleTimeActive" SG_ 1079 LSMS_ReqstdArticlatnAngle1_1 100;
BA_ "GenSigStartValue" SG_ 1079 LSMS_ReqstdArticlatnAngle1_1 65535;
BA_ "GenSigCycleTime" SG_ 1079 LSMS_TrailrArticlatnAngle2_1 100;
BA_ "GenSigCycleTimeActive" SG_ 1079 LSMS_TrailrArticlatnAngle2_1 100;
BA_ "GenSigStartValue" SG_ 1079 LSMS_TrailrArticlatnAngle2_1 65535;
BA_ "GenSigCycleTime" SG_ 1079 LSMS_TrailrArticlatnAngle1_1 100;
BA_ "GenSigCycleTimeActive" SG_ 1079 LSMS_TrailrArticlatnAngle1_1 100;
BA_ "GenSigStartValue" SG_ 1079 LSMS_TrailrArticlatnAngle1_1 65535;
BA_ "GenSigSendType" SG_ 1066 TrafficSitSpdProfile_MinSpd 1;
BA_ "GenSigCycleTime" SG_ 1066 TrafficSitSpdProfile_MinSpd 100;
BA_ "GenSigCycleTimeActive" SG_ 1066 TrafficSitSpdProfile_MinSpd 100;
BA_ "GenSigStartValue" SG_ 1066 TrafficSitSpdProfile_MinSpd 1023;
BA_ "GenSigSendType" SG_ 1066 TrafficSitSpdProfile_Offset 1;
BA_ "GenSigCycleTime" SG_ 1066 TrafficSitSpdProfile_Offset 100;
BA_ "GenSigCycleTimeActive" SG_ 1066 TrafficSitSpdProfile_Offset 100;
BA_ "GenSigStartValue" SG_ 1066 TrafficSitSpdProfile_Offset 8191;
BA_ "GenSigSendType" SG_ 1066 TrafficSitSpdProfile_MaxSpd 1;
BA_ "GenSigCycleTime" SG_ 1066 TrafficSitSpdProfile_MaxSpd 100;
BA_ "GenSigCycleTimeActive" SG_ 1066 TrafficSitSpdProfile_MaxSpd 100;
BA_ "GenSigStartValue" SG_ 1066 TrafficSitSpdProfile_MaxSpd 1023;
BA_ "GenSigSendType" SG_ 1066 TrafficSitSpdProfile_Speed 1;
BA_ "GenSigCycleTime" SG_ 1066 TrafficSitSpdProfile_Speed 100;
BA_ "GenSigCycleTimeActive" SG_ 1066 TrafficSitSpdProfile_Speed 100;
BA_ "GenSigStartValue" SG_ 1066 TrafficSitSpdProfile_Speed 1023;
BA_ "GenSigSendType" SG_ 1066 TrafficSitSpdProfile_PathIndex 1;
BA_ "GenSigCycleTime" SG_ 1066 TrafficSitSpdProfile_PathIndex 100;
BA_ "GenSigCycleTimeActive" SG_ 1066 TrafficSitSpdProfile_PathIndex 100;
BA_ "GenSigStartValue" SG_ 1066 TrafficSitSpdProfile_PathIndex 63;
BA_ "GenSigSendType" SG_ 1066 TrafficSitSpdProfile_Type 1;
BA_ "GenSigCycleTime" SG_ 1066 TrafficSitSpdProfile_Type 100;
BA_ "GenSigCycleTimeActive" SG_ 1066 TrafficSitSpdProfile_Type 100;
BA_ "GenSigStartValue" SG_ 1066 TrafficSitSpdProfile_Type 255;
BA_ "GenSigCycleTime" SG_ 1338 RoadSpeedRestriction 100;
BA_ "GenSigCycleTimeActive" SG_ 1338 RoadSpeedRestriction 100;
BA_ "GenSigStartValue" SG_ 1338 RoadSpeedRestriction 255;
BA_ "GenSigCycleTime" SG_ 1338 ObserveRoadRestriction_OpCap 100;
BA_ "GenSigCycleTimeActive" SG_ 1338 ObserveRoadRestriction_OpCap 100;
BA_ "GenSigStartValue" SG_ 1338 ObserveRoadRestriction_OpCap 3;
BA_ "GenSigCycleTime" SG_ 1338 RoadSpeedUnitType 100;
BA_ "GenSigCycleTimeActive" SG_ 1338 RoadSpeedUnitType 100;
BA_ "GenSigStartValue" SG_ 1338 RoadSpeedUnitType 7;
BA_ "GenSigCycleTime" SG_ 1338 RoadOvertakingRestriction 100;
BA_ "GenSigCycleTimeActive" SG_ 1338 RoadOvertakingRestriction 100;
BA_ "GenSigStartValue" SG_ 1338 RoadOvertakingRestriction 7;
BA_ "GenSigCycleTime" SG_ 1338 RoadTypeSpeedRestriction 100;
BA_ "GenSigCycleTimeActive" SG_ 1338 RoadTypeSpeedRestriction 100;
BA_ "GenSigStartValue" SG_ 1338 RoadTypeSpeedRestriction 7;
BA_ "GenSigCycleTime" SG_ 1338 ObserveRoadRestrictionStatus 100;
BA_ "GenSigCycleTimeActive" SG_ 1338 ObserveRoadRestrictionStatus 100;
BA_ "GenSigStartValue" SG_ 1338 ObserveRoadRestrictionStatus 3;
BA_REL_ "GenSigFirstTimeoutTime" BU_SG_REL_ IC3 SG_ 1520 DiagFaultStat_WRCS_EcuAdr_ISig_4 24000;
BA_REL_ "GenSigTimeoutTime" BU_SG_REL_ IC3 SG_ 1520 DiagFaultStat_WRCS_EcuAdr_ISig_4 6000;
BA_REL_ "GenSigFirstTimeoutTime" BU_SG_REL_ IC3 SG_ 1520 DiagFaultStat_WRCS_DtcIdB_ISig_4 24000;
BA_REL_ "GenSigTimeoutTime" BU_SG_REL_ IC3 SG_ 1520 DiagFaultStat_WRCS_DtcIdB_ISig_4 6000;
BA_REL_ "GenSigFirstTimeoutTime" BU_SG_REL_ IC3 SG_ 1520 DiagFaultStat_WRCS_FailTB_ISig_4 24000;
BA_REL_ "GenSigTimeoutTime" BU_SG_REL_ IC3 SG_ 1520 DiagFaultStat_WRCS_FailTB_ISig_4 6000;
BA_REL_ "GenSigFirstTimeoutTime" BU_SG_REL_ IC3 SG_ 1520 DiagFaultStat_WRCS_FailTA_ISig_4 24000;
BA_REL_ "GenSigTimeoutTime" BU_SG_REL_ IC3 SG_ 1520 DiagFaultStat_WRCS_FailTA_ISig_4 6000;
BA_REL_ "GenSigFirstTimeoutTime" BU_SG_REL_ IC3 SG_ 1520 DiagFaultStat_WRCS_DtcIdA_ISig_4 24000;
BA_REL_ "GenSigTimeoutTime" BU_SG_REL_ IC3 SG_ 1520 DiagFaultStat_WRCS_DtcIdA_ISig_4 6000;
BA_REL_ "GenSigFirstTimeoutTime" BU_SG_REL_ IC3 SG_ 1488 DiagFaultStat_VMCU_DtcIdA_ISig_4 24000;
BA_REL_ "GenSigTimeoutTime" BU_SG_REL_ IC3 SG_ 1488 DiagFaultStat_VMCU_DtcIdA_ISig_4 6000;
BA_REL_ "GenSigFirstTimeoutTime" BU_SG_REL_ IC3 SG_ 1488 DiagFaultStat_VMCU_EcuAdr_ISig_4 24000;
BA_REL_ "GenSigTimeoutTime" BU_SG_REL_ IC3 SG_ 1488 DiagFaultStat_VMCU_EcuAdr_ISig_4 6000;
BA_REL_ "GenSigFirstTimeoutTime" BU_SG_REL_ IC3 SG_ 1488 DiagFaultStat_VMCU_FailTA_ISig_4 24000;
BA_REL_ "GenSigTimeoutTime" BU_SG_REL_ IC3 SG_ 1488 DiagFaultStat_VMCU_FailTA_ISig_4 6000;
BA_REL_ "GenSigFirstTimeoutTime" BU_SG_REL_ IC3 SG_ 1488 DiagFaultStat_VMCU_FailTB_ISig_4 24000;
BA_REL_ "GenSigTimeoutTime" BU_SG_REL_ IC3 SG_ 1488 DiagFaultStat_VMCU_FailTB_ISig_4 6000;
BA_REL_ "GenSigFirstTimeoutTime" BU_SG_REL_ IC3 SG_ 1488 DiagFaultStat_VMCU_DtcIdB_ISig_4 24000;
BA_REL_ "GenSigTimeoutTime" BU_SG_REL_ IC3 SG_ 1488 DiagFaultStat_VMCU_DtcIdB_ISig_4 6000;
BA_REL_ "GenSigFirstTimeoutTime" BU_SG_REL_ IC3 SG_ 1502 DiagFaultStat_TPM_EcuAdr_ISig_4 24000;
BA_REL_ "GenSigTimeoutTime" BU_SG_REL_ IC3 SG_ 1502 DiagFaultStat_TPM_EcuAdr_ISig_4 6000;
BA_REL_ "GenSigFirstTimeoutTime" BU_SG_REL_ IC3 SG_ 1502 DiagFaultStat_TPM_FailTB_ISig_4 24000;
BA_REL_ "GenSigTimeoutTime" BU_SG_REL_ IC3 SG_ 1502 DiagFaultStat_TPM_FailTB_ISig_4 6000;
BA_REL_ "GenSigFirstTimeoutTime" BU_SG_REL_ IC3 SG_ 1502 DiagFaultStat_TPM_DtcIdA_ISig_4 24000;
BA_REL_ "GenSigTimeoutTime" BU_SG_REL_ IC3 SG_ 1502 DiagFaultStat_TPM_DtcIdA_ISig_4 6000;
BA_REL_ "GenSigFirstTimeoutTime" BU_SG_REL_ IC3 SG_ 1502 DiagFaultStat_TPM_DtcIdB_ISig_4 24000;
BA_REL_ "GenSigTimeoutTime" BU_SG_REL_ IC3 SG_ 1502 DiagFaultStat_TPM_DtcIdB_ISig_4 6000;
BA_REL_ "GenSigFirstTimeoutTime" BU_SG_REL_ IC3 SG_ 1502 DiagFaultStat_TPM_FailTA_ISig_4 24000;
BA_REL_ "GenSigTimeoutTime" BU_SG_REL_ IC3 SG_ 1502 DiagFaultStat_TPM_FailTA_ISig_4 6000;
BA_REL_ "GenSigFirstTimeoutTime" BU_SG_REL_ IC3 SG_ 1519 DiagFaultStat_TECU_FailTA_ISig_4 24000;
BA_REL_ "GenSigTimeoutTime" BU_SG_REL_ IC3 SG_ 1519 DiagFaultStat_TECU_FailTA_ISig_4 6000;
BA_REL_ "GenSigFirstTimeoutTime" BU_SG_REL_ IC3 SG_ 1519 DiagFaultStat_TECU_FailTB_ISig_4 24000;
BA_REL_ "GenSigTimeoutTime" BU_SG_REL_ IC3 SG_ 1519 DiagFaultStat_TECU_FailTB_ISig_4 6000;
BA_REL_ "GenSigFirstTimeoutTime" BU_SG_REL_ IC3 SG_ 1519 DiagFaultStat_TECU_DtcIdA_ISig_4 24000;
BA_REL_ "GenSigTimeoutTime" BU_SG_REL_ IC3 SG_ 1519 DiagFaultStat_TECU_DtcIdA_ISig_4 6000;
BA_REL_ "GenSigFirstTimeoutTime" BU_SG_REL_ IC3 SG_ 1519 DiagFaultStat_TECU_EcuAdr_ISig_4 24000;
BA_REL_ "GenSigTimeoutTime" BU_SG_REL_ IC3 SG_ 1519 DiagFaultStat_TECU_EcuAdr_ISig_4 6000;
BA_REL_ "GenSigFirstTimeoutTime" BU_SG_REL_ IC3 SG_ 1519 DiagFaultStat_TECU_DtcIdB_ISig_4 24000;
BA_REL_ "GenSigTimeoutTime" BU_SG_REL_ IC3 SG_ 1519 DiagFaultStat_TECU_DtcIdB_ISig_4 6000;
BA_REL_ "GenSigFirstTimeoutTime" BU_SG_REL_ IC3 SG_ 1517 DiagFaultStat_SRS_DtcIdB_ISig_4 24000;
BA_REL_ "GenSigTimeoutTime" BU_SG_REL_ IC3 SG_ 1517 DiagFaultStat_SRS_DtcIdB_ISig_4 6000;
BA_REL_ "GenSigFirstTimeoutTime" BU_SG_REL_ IC3 SG_ 1517 DiagFaultStat_SRS_FailTB_ISig_4 24000;
BA_REL_ "GenSigTimeoutTime" BU_SG_REL_ IC3 SG_ 1517 DiagFaultStat_SRS_FailTB_ISig_4 6000;
BA_REL_ "GenSigFirstTimeoutTime" BU_SG_REL_ IC3 SG_ 1517 DiagFaultStat_SRS_EcuAdr_ISig_4 24000;
BA_REL_ "GenSigTimeoutTime" BU_SG_REL_ IC3 SG_ 1517 DiagFaultStat_SRS_EcuAdr_ISig_4 6000;
BA_REL_ "GenSigFirstTimeoutTime" BU_SG_REL_ IC3 SG_ 1517 DiagFaultStat_SRS_DtcIdA_ISig_4 24000;
BA_REL_ "GenSigTimeoutTime" BU_SG_REL_ IC3 SG_ 1517 DiagFaultStat_SRS_DtcIdA_ISig_4 6000;
BA_REL_ "GenSigFirstTimeoutTime" BU_SG_REL_ IC3 SG_ 1517 DiagFaultStat_SRS_FailTA_ISig_4 24000;
BA_REL_ "GenSigTimeoutTime" BU_SG_REL_ IC3 SG_ 1517 DiagFaultStat_SRS_FailTA_ISig_4 6000;
BA_REL_ "GenSigFirstTimeoutTime" BU_SG_REL_ IC3 SG_ 1516 DiagFaultStat_RCIOM_FailTA_ISig_ 24000;
BA_REL_ "GenSigTimeoutTime" BU_SG_REL_ IC3 SG_ 1516 DiagFaultStat_RCIOM_FailTA_ISig_ 6000;
BA_REL_ "GenSigFirstTimeoutTime" BU_SG_REL_ IC3 SG_ 1516 DiagFaultStat_RCIOM_FailTB_ISig_ 24000;
BA_REL_ "GenSigTimeoutTime" BU_SG_REL_ IC3 SG_ 1516 DiagFaultStat_RCIOM_FailTB_ISig_ 6000;
BA_REL_ "GenSigFirstTimeoutTime" BU_SG_REL_ IC3 SG_ 1516 DiagFaultStat_RCIOM_DtcIdB_ISig_ 24000;
BA_REL_ "GenSigTimeoutTime" BU_SG_REL_ IC3 SG_ 1516 DiagFaultStat_RCIOM_DtcIdB_ISig_ 6000;
BA_REL_ "GenSigFirstTimeoutTime" BU_SG_REL_ IC3 SG_ 1516 DiagFaultStat_RCIOM_DtcIdA_ISig_ 24000;
BA_REL_ "GenSigTimeoutTime" BU_SG_REL_ IC3 SG_ 1516 DiagFaultStat_RCIOM_DtcIdA_ISig_ 6000;
BA_REL_ "GenSigFirstTimeoutTime" BU_SG_REL_ IC3 SG_ 1516 DiagFaultStat_RCIOM_EcuAdr_ISig_ 24000;
BA_REL_ "GenSigTimeoutTime" BU_SG_REL_ IC3 SG_ 1516 DiagFaultStat_RCIOM_EcuAdr_ISig_ 6000;
BA_REL_ "GenSigFirstTimeoutTime" BU_SG_REL_ IC3 SG_ 1515 DiagFaultStat_PDM_EcuAdr_ISig_4 24000;
BA_REL_ "GenSigTimeoutTime" BU_SG_REL_ IC3 SG_ 1515 DiagFaultStat_PDM_EcuAdr_ISig_4 6000;
BA_REL_ "GenSigFirstTimeoutTime" BU_SG_REL_ IC3 SG_ 1515 DiagFaultStat_PDM_DtcIdB_ISig_4 24000;
BA_REL_ "GenSigTimeoutTime" BU_SG_REL_ IC3 SG_ 1515 DiagFaultStat_PDM_DtcIdB_ISig_4 6000;
BA_REL_ "GenSigFirstTimeoutTime" BU_SG_REL_ IC3 SG_ 1515 DiagFaultStat_PDM_FailTB_ISig_4 24000;
BA_REL_ "GenSigTimeoutTime" BU_SG_REL_ IC3 SG_ 1515 DiagFaultStat_PDM_FailTB_ISig_4 6000;
BA_REL_ "GenSigFirstTimeoutTime" BU_SG_REL_ IC3 SG_ 1515 DiagFaultStat_PDM_DtcIdA_ISig_4 24000;
BA_REL_ "GenSigTimeoutTime" BU_SG_REL_ IC3 SG_ 1515 DiagFaultStat_PDM_DtcIdA_ISig_4 6000;
BA_REL_ "GenSigFirstTimeoutTime" BU_SG_REL_ IC3 SG_ 1515 DiagFaultStat_PDM_FailTA_ISig_4 24000;
BA_REL_ "GenSigTimeoutTime" BU_SG_REL_ IC3 SG_ 1515 DiagFaultStat_PDM_FailTA_ISig_4 6000;
BA_REL_ "GenSigFirstTimeoutTime" BU_SG_REL_ IC3 SG_ 1514 DiagFaultStat_LPOS_DtcIdB_ISig_4 24000;
BA_REL_ "GenSigTimeoutTime" BU_SG_REL_ IC3 SG_ 1514 DiagFaultStat_LPOS_DtcIdB_ISig_4 6000;
BA_REL_ "GenSigFirstTimeoutTime" BU_SG_REL_ IC3 SG_ 1514 DiagFaultStat_LPOS_FailTB_ISig_4 24000;
BA_REL_ "GenSigTimeoutTime" BU_SG_REL_ IC3 SG_ 1514 DiagFaultStat_LPOS_FailTB_ISig_4 6000;
BA_REL_ "GenSigFirstTimeoutTime" BU_SG_REL_ IC3 SG_ 1514 DiagFaultStat_LPOS_DtcIdA_ISig_4 24000;
BA_REL_ "GenSigTimeoutTime" BU_SG_REL_ IC3 SG_ 1514 DiagFaultStat_LPOS_DtcIdA_ISig_4 6000;
BA_REL_ "GenSigFirstTimeoutTime" BU_SG_REL_ IC3 SG_ 1514 DiagFaultStat_LPOS_FailTA_ISig_4 24000;
BA_REL_ "GenSigTimeoutTime" BU_SG_REL_ IC3 SG_ 1514 DiagFaultStat_LPOS_FailTA_ISig_4 6000;
BA_REL_ "GenSigFirstTimeoutTime" BU_SG_REL_ IC3 SG_ 1514 DiagFaultStat_LPOS_EcuAdr_ISig_4 24000;
BA_REL_ "GenSigTimeoutTime" BU_SG_REL_ IC3 SG_ 1514 DiagFaultStat_LPOS_EcuAdr_ISig_4 6000;
BA_REL_ "GenSigFirstTimeoutTime" BU_SG_REL_ IC3 SG_ 1513 DiagFaultStat_LECM_EcuAdr_ISig_4 24000;
BA_REL_ "GenSigTimeoutTime" BU_SG_REL_ IC3 SG_ 1513 DiagFaultStat_LECM_EcuAdr_ISig_4 6000;
BA_REL_ "GenSigFirstTimeoutTime" BU_SG_REL_ IC3 SG_ 1513 DiagFaultStat_LECM_FailTB_ISig_4 24000;
BA_REL_ "GenSigTimeoutTime" BU_SG_REL_ IC3 SG_ 1513 DiagFaultStat_LECM_FailTB_ISig_4 6000;
BA_REL_ "GenSigFirstTimeoutTime" BU_SG_REL_ IC3 SG_ 1513 DiagFaultStat_LECM_FailTA_ISig_4 24000;
BA_REL_ "GenSigTimeoutTime" BU_SG_REL_ IC3 SG_ 1513 DiagFaultStat_LECM_FailTA_ISig_4 6000;
BA_REL_ "GenSigFirstTimeoutTime" BU_SG_REL_ IC3 SG_ 1513 DiagFaultStat_LECM_DtcIdB_ISig_4 24000;
BA_REL_ "GenSigTimeoutTime" BU_SG_REL_ IC3 SG_ 1513 DiagFaultStat_LECM_DtcIdB_ISig_4 6000;
BA_REL_ "GenSigFirstTimeoutTime" BU_SG_REL_ IC3 SG_ 1513 DiagFaultStat_LECM_DtcIdA_ISig_4 24000;
BA_REL_ "GenSigTimeoutTime" BU_SG_REL_ IC3 SG_ 1513 DiagFaultStat_LECM_DtcIdA_ISig_4 6000;
BA_REL_ "GenSigFirstTimeoutTime" BU_SG_REL_ IC3 SG_ 1497 DiagFaultStat_GFHCM2_DtcIdB_ISig 24000;
BA_REL_ "GenSigTimeoutTime" BU_SG_REL_ IC3 SG_ 1497 DiagFaultStat_GFHCM2_DtcIdB_ISig 6000;
BA_REL_ "GenSigFirstTimeoutTime" BU_SG_REL_ IC3 SG_ 1497 DiagFaultStat_GFHCM2_DtcIdA_ISig 24000;
BA_REL_ "GenSigTimeoutTime" BU_SG_REL_ IC3 SG_ 1497 DiagFaultStat_GFHCM2_DtcIdA_ISig 6000;
BA_REL_ "GenSigFirstTimeoutTime" BU_SG_REL_ IC3 SG_ 1497 DiagFaultStat_GFHCM2_FailTA_ISig 24000;
BA_REL_ "GenSigTimeoutTime" BU_SG_REL_ IC3 SG_ 1497 DiagFaultStat_GFHCM2_FailTA_ISig 6000;
BA_REL_ "GenSigFirstTimeoutTime" BU_SG_REL_ IC3 SG_ 1497 DiagFaultStat_GFHCM2_EcuAdr_ISig 24000;
BA_REL_ "GenSigTimeoutTime" BU_SG_REL_ IC3 SG_ 1497 DiagFaultStat_GFHCM2_EcuAdr_ISig 6000;
BA_REL_ "GenSigFirstTimeoutTime" BU_SG_REL_ IC3 SG_ 1497 DiagFaultStat_GFHCM2_FailTB_ISig 24000;
BA_REL_ "GenSigTimeoutTime" BU_SG_REL_ IC3 SG_ 1497 DiagFaultStat_GFHCM2_FailTB_ISig 6000;
BA_REL_ "GenSigFirstTimeoutTime" BU_SG_REL_ IC3 SG_ 1496 DiagFaultStat_GFHCM1_DtcIdA_ISig 24000;
BA_REL_ "GenSigTimeoutTime" BU_SG_REL_ IC3 SG_ 1496 DiagFaultStat_GFHCM1_DtcIdA_ISig 6000;
BA_REL_ "GenSigFirstTimeoutTime" BU_SG_REL_ IC3 SG_ 1496 DiagFaultStat_GFHCM1_FailTB_ISig 24000;
BA_REL_ "GenSigTimeoutTime" BU_SG_REL_ IC3 SG_ 1496 DiagFaultStat_GFHCM1_FailTB_ISig 6000;
BA_REL_ "GenSigFirstTimeoutTime" BU_SG_REL_ IC3 SG_ 1496 DiagFaultStat_GFHCM1_FailTA_ISig 24000;
BA_REL_ "GenSigTimeoutTime" BU_SG_REL_ IC3 SG_ 1496 DiagFaultStat_GFHCM1_FailTA_ISig 6000;
BA_REL_ "GenSigFirstTimeoutTime" BU_SG_REL_ IC3 SG_ 1496 DiagFaultStat_GFHCM1_EcuAdr_ISig 24000;
BA_REL_ "GenSigTimeoutTime" BU_SG_REL_ IC3 SG_ 1496 DiagFaultStat_GFHCM1_EcuAdr_ISig 6000;
BA_REL_ "GenSigFirstTimeoutTime" BU_SG_REL_ IC3 SG_ 1496 DiagFaultStat_GFHCM1_DtcIdB_ISig 24000;
BA_REL_ "GenSigTimeoutTime" BU_SG_REL_ IC3 SG_ 1496 DiagFaultStat_GFHCM1_DtcIdB_ISig 6000;
BA_REL_ "GenSigFirstTimeoutTime" BU_SG_REL_ IC3 SG_ 1512 DiagFaultStat_FLS_DtcIdB_ISig_4 24000;
BA_REL_ "GenSigTimeoutTime" BU_SG_REL_ IC3 SG_ 1512 DiagFaultStat_FLS_DtcIdB_ISig_4 6000;
BA_REL_ "GenSigFirstTimeoutTime" BU_SG_REL_ IC3 SG_ 1512 DiagFaultStat_FLS_FailTB_ISig_4 24000;
BA_REL_ "GenSigTimeoutTime" BU_SG_REL_ IC3 SG_ 1512 DiagFaultStat_FLS_FailTB_ISig_4 6000;
BA_REL_ "GenSigFirstTimeoutTime" BU_SG_REL_ IC3 SG_ 1512 DiagFaultStat_FLS_DtcIdA_ISig_4 24000;
BA_REL_ "GenSigTimeoutTime" BU_SG_REL_ IC3 SG_ 1512 DiagFaultStat_FLS_DtcIdA_ISig_4 6000;
BA_REL_ "GenSigFirstTimeoutTime" BU_SG_REL_ IC3 SG_ 1512 DiagFaultStat_FLS_EcuAdr_ISig_4 24000;
BA_REL_ "GenSigTimeoutTime" BU_SG_REL_ IC3 SG_ 1512 DiagFaultStat_FLS_EcuAdr_ISig_4 6000;
BA_REL_ "GenSigFirstTimeoutTime" BU_SG_REL_ IC3 SG_ 1512 DiagFaultStat_FLS_FailTA_ISig_4 24000;
BA_REL_ "GenSigTimeoutTime" BU_SG_REL_ IC3 SG_ 1512 DiagFaultStat_FLS_FailTA_ISig_4 6000;
BA_REL_ "GenSigFirstTimeoutTime" BU_SG_REL_ IC3 SG_ 1499 DiagFaultStat_FCIOM_DtcIdB_ISig_ 24000;
BA_REL_ "GenSigTimeoutTime" BU_SG_REL_ IC3 SG_ 1499 DiagFaultStat_FCIOM_DtcIdB_ISig_ 6000;
BA_REL_ "GenSigFirstTimeoutTime" BU_SG_REL_ IC3 SG_ 1499 DiagFaultStat_FCIOM_FailTA_ISig_ 24000;
BA_REL_ "GenSigTimeoutTime" BU_SG_REL_ IC3 SG_ 1499 DiagFaultStat_FCIOM_FailTA_ISig_ 6000;
BA_REL_ "GenSigFirstTimeoutTime" BU_SG_REL_ IC3 SG_ 1499 DiagFaultStat_FCIOM_FailTB_ISig_ 24000;
BA_REL_ "GenSigTimeoutTime" BU_SG_REL_ IC3 SG_ 1499 DiagFaultStat_FCIOM_FailTB_ISig_ 6000;
BA_REL_ "GenSigFirstTimeoutTime" BU_SG_REL_ IC3 SG_ 1499 DiagFaultStat_FCIOM_EcuAdr_ISig_ 24000;
BA_REL_ "GenSigTimeoutTime" BU_SG_REL_ IC3 SG_ 1499 DiagFaultStat_FCIOM_EcuAdr_ISig_ 6000;
BA_REL_ "GenSigFirstTimeoutTime" BU_SG_REL_ IC3 SG_ 1499 DiagFaultStat_FCIOM_DtcIdA_ISig_ 24000;
BA_REL_ "GenSigTimeoutTime" BU_SG_REL_ IC3 SG_ 1499 DiagFaultStat_FCIOM_DtcIdA_ISig_ 6000;
BA_REL_ "GenSigFirstTimeoutTime" BU_SG_REL_ IC3 SG_ 1491 DiagFaultStat_FAS_FailTA_ISig_4 24000;
BA_REL_ "GenSigTimeoutTime" BU_SG_REL_ IC3 SG_ 1491 DiagFaultStat_FAS_FailTA_ISig_4 6000;
BA_REL_ "GenSigFirstTimeoutTime" BU_SG_REL_ IC3 SG_ 1491 DiagFaultStat_FAS_DtcIdA_ISig_4 24000;
BA_REL_ "GenSigTimeoutTime" BU_SG_REL_ IC3 SG_ 1491 DiagFaultStat_FAS_DtcIdA_ISig_4 6000;
BA_REL_ "GenSigFirstTimeoutTime" BU_SG_REL_ IC3 SG_ 1491 DiagFaultStat_FAS_FailTB_ISig_4 24000;
BA_REL_ "GenSigTimeoutTime" BU_SG_REL_ IC3 SG_ 1491 DiagFaultStat_FAS_FailTB_ISig_4 6000;
BA_REL_ "GenSigFirstTimeoutTime" BU_SG_REL_ IC3 SG_ 1491 DiagFaultStat_FAS_EcuAdr_ISig_4 24000;
BA_REL_ "GenSigTimeoutTime" BU_SG_REL_ IC3 SG_ 1491 DiagFaultStat_FAS_EcuAdr_ISig_4 6000;
BA_REL_ "GenSigFirstTimeoutTime" BU_SG_REL_ IC3 SG_ 1491 DiagFaultStat_FAS_DtcIdB_ISig_4 24000;
BA_REL_ "GenSigTimeoutTime" BU_SG_REL_ IC3 SG_ 1491 DiagFaultStat_FAS_DtcIdB_ISig_4 6000;
BA_REL_ "GenSigFirstTimeoutTime" BU_SG_REL_ IC3 SG_ 1511 DiagFaultStat_EMS_EcuAdr_ISig_4 24000;
BA_REL_ "GenSigTimeoutTime" BU_SG_REL_ IC3 SG_ 1511 DiagFaultStat_EMS_EcuAdr_ISig_4 6000;
BA_REL_ "GenSigFirstTimeoutTime" BU_SG_REL_ IC3 SG_ 1511 DiagFaultStat_EMS_DtcIdB_ISig_4 24000;
BA_REL_ "GenSigTimeoutTime" BU_SG_REL_ IC3 SG_ 1511 DiagFaultStat_EMS_DtcIdB_ISig_4 6000;
BA_REL_ "GenSigFirstTimeoutTime" BU_SG_REL_ IC3 SG_ 1511 DiagFaultStat_EMS_DtcIdA_ISig_4 24000;
BA_REL_ "GenSigTimeoutTime" BU_SG_REL_ IC3 SG_ 1511 DiagFaultStat_EMS_DtcIdA_ISig_4 6000;
BA_REL_ "GenSigFirstTimeoutTime" BU_SG_REL_ IC3 SG_ 1511 DiagFaultStat_EMS_FailTB_ISig_4 24000;
BA_REL_ "GenSigTimeoutTime" BU_SG_REL_ IC3 SG_ 1511 DiagFaultStat_EMS_FailTB_ISig_4 6000;
BA_REL_ "GenSigFirstTimeoutTime" BU_SG_REL_ IC3 SG_ 1511 DiagFaultStat_EMS_FailTA_ISig_4 24000;
BA_REL_ "GenSigTimeoutTime" BU_SG_REL_ IC3 SG_ 1511 DiagFaultStat_EMS_FailTA_ISig_4 6000;
BA_REL_ "GenSigFirstTimeoutTime" BU_SG_REL_ IC3 SG_ 1493 DiagFaultStat_EAS_DtcIdB_ISig_4 24000;
BA_REL_ "GenSigTimeoutTime" BU_SG_REL_ IC3 SG_ 1493 DiagFaultStat_EAS_DtcIdB_ISig_4 6000;
BA_REL_ "GenSigFirstTimeoutTime" BU_SG_REL_ IC3 SG_ 1493 DiagFaultStat_EAS_DtcIdA_ISig_4 24000;
BA_REL_ "GenSigTimeoutTime" BU_SG_REL_ IC3 SG_ 1493 DiagFaultStat_EAS_DtcIdA_ISig_4 6000;
BA_REL_ "GenSigFirstTimeoutTime" BU_SG_REL_ IC3 SG_ 1493 DiagFaultStat_EAS_FailTB_ISig_4 24000;
BA_REL_ "GenSigTimeoutTime" BU_SG_REL_ IC3 SG_ 1493 DiagFaultStat_EAS_FailTB_ISig_4 6000;
BA_REL_ "GenSigFirstTimeoutTime" BU_SG_REL_ IC3 SG_ 1493 DiagFaultStat_EAS_FailTA_ISig_4 24000;
BA_REL_ "GenSigTimeoutTime" BU_SG_REL_ IC3 SG_ 1493 DiagFaultStat_EAS_FailTA_ISig_4 6000;
BA_REL_ "GenSigFirstTimeoutTime" BU_SG_REL_ IC3 SG_ 1493 DiagFaultStat_EAS_EcuAdr_ISig_4 24000;
BA_REL_ "GenSigTimeoutTime" BU_SG_REL_ IC3 SG_ 1493 DiagFaultStat_EAS_EcuAdr_ISig_4 6000;
BA_REL_ "GenSigFirstTimeoutTime" BU_SG_REL_ IC3 SG_ 1510 DiagFaultStat_DDM_DtcIdA_ISig_4 24000;
BA_REL_ "GenSigTimeoutTime" BU_SG_REL_ IC3 SG_ 1510 DiagFaultStat_DDM_DtcIdA_ISig_4 6000;
BA_REL_ "GenSigFirstTimeoutTime" BU_SG_REL_ IC3 SG_ 1510 DiagFaultStat_DDM_FailTA_ISig_4 24000;
BA_REL_ "GenSigTimeoutTime" BU_SG_REL_ IC3 SG_ 1510 DiagFaultStat_DDM_FailTA_ISig_4 6000;
BA_REL_ "GenSigFirstTimeoutTime" BU_SG_REL_ IC3 SG_ 1510 DiagFaultStat_DDM_EcuAdr_ISig_4 24000;
BA_REL_ "GenSigTimeoutTime" BU_SG_REL_ IC3 SG_ 1510 DiagFaultStat_DDM_EcuAdr_ISig_4 6000;
BA_REL_ "GenSigFirstTimeoutTime" BU_SG_REL_ IC3 SG_ 1510 DiagFaultStat_DDM_FailTB_ISig_4 24000;
BA_REL_ "GenSigTimeoutTime" BU_SG_REL_ IC3 SG_ 1510 DiagFaultStat_DDM_FailTB_ISig_4 6000;
BA_REL_ "GenSigFirstTimeoutTime" BU_SG_REL_ IC3 SG_ 1510 DiagFaultStat_DDM_DtcIdB_ISig_4 24000;
BA_REL_ "GenSigTimeoutTime" BU_SG_REL_ IC3 SG_ 1510 DiagFaultStat_DDM_DtcIdB_ISig_4 6000;
BA_REL_ "GenSigFirstTimeoutTime" BU_SG_REL_ IC3 SG_ 1509 DiagFaultStat_DACU_DtcIdB_ISig_4 24000;
BA_REL_ "GenSigTimeoutTime" BU_SG_REL_ IC3 SG_ 1509 DiagFaultStat_DACU_DtcIdB_ISig_4 6000;
BA_REL_ "GenSigFirstTimeoutTime" BU_SG_REL_ IC3 SG_ 1509 DiagFaultStat_DACU_DtcIdA_ISig_4 24000;
BA_REL_ "GenSigTimeoutTime" BU_SG_REL_ IC3 SG_ 1509 DiagFaultStat_DACU_DtcIdA_ISig_4 6000;
BA_REL_ "GenSigFirstTimeoutTime" BU_SG_REL_ IC3 SG_ 1509 DiagFaultStat_DACU_EcuAdr_ISig_4 24000;
BA_REL_ "GenSigTimeoutTime" BU_SG_REL_ IC3 SG_ 1509 DiagFaultStat_DACU_EcuAdr_ISig_4 6000;
BA_REL_ "GenSigFirstTimeoutTime" BU_SG_REL_ IC3 SG_ 1509 DiagFaultStat_DACU_FailTB_ISig_4 24000;
BA_REL_ "GenSigTimeoutTime" BU_SG_REL_ IC3 SG_ 1509 DiagFaultStat_DACU_FailTB_ISig_4 6000;
BA_REL_ "GenSigFirstTimeoutTime" BU_SG_REL_ IC3 SG_ 1509 DiagFaultStat_DACU_FailTA_ISig_4 24000;
BA_REL_ "GenSigTimeoutTime" BU_SG_REL_ IC3 SG_ 1509 DiagFaultStat_DACU_FailTA_ISig_4 6000;
BA_REL_ "GenSigFirstTimeoutTime" BU_SG_REL_ IC3 SG_ 1508 DiagFaultStat_CIOM_DtcIdA_ISig_4 24000;
BA_REL_ "GenSigTimeoutTime" BU_SG_REL_ IC3 SG_ 1508 DiagFaultStat_CIOM_DtcIdA_ISig_4 6000;
BA_REL_ "GenSigFirstTimeoutTime" BU_SG_REL_ IC3 SG_ 1508 DiagFaultStat_CIOM_EcuAdr_ISig_4 24000;
BA_REL_ "GenSigTimeoutTime" BU_SG_REL_ IC3 SG_ 1508 DiagFaultStat_CIOM_EcuAdr_ISig_4 6000;
BA_REL_ "GenSigFirstTimeoutTime" BU_SG_REL_ IC3 SG_ 1508 DiagFaultStat_CIOM_DtcIdB_ISig_4 24000;
BA_REL_ "GenSigTimeoutTime" BU_SG_REL_ IC3 SG_ 1508 DiagFaultStat_CIOM_DtcIdB_ISig_4 6000;
BA_REL_ "GenSigFirstTimeoutTime" BU_SG_REL_ IC3 SG_ 1508 DiagFaultStat_CIOM_FailTA_ISig_4 24000;
BA_REL_ "GenSigTimeoutTime" BU_SG_REL_ IC3 SG_ 1508 DiagFaultStat_CIOM_FailTA_ISig_4 6000;
BA_REL_ "GenSigFirstTimeoutTime" BU_SG_REL_ IC3 SG_ 1508 DiagFaultStat_CIOM_FailTB_ISig_4 24000;
BA_REL_ "GenSigTimeoutTime" BU_SG_REL_ IC3 SG_ 1508 DiagFaultStat_CIOM_FailTB_ISig_4 6000;
BA_REL_ "GenSigFirstTimeoutTime" BU_SG_REL_ IC3 SG_ 1507 DiagFaultStat_CCM_FailTB_ISig_4 24000;
BA_REL_ "GenSigTimeoutTime" BU_SG_REL_ IC3 SG_ 1507 DiagFaultStat_CCM_FailTB_ISig_4 6000;
BA_REL_ "GenSigFirstTimeoutTime" BU_SG_REL_ IC3 SG_ 1507 DiagFaultStat_CCM_DtcIdA_ISig_4 24000;
BA_REL_ "GenSigTimeoutTime" BU_SG_REL_ IC3 SG_ 1507 DiagFaultStat_CCM_DtcIdA_ISig_4 6000;
BA_REL_ "GenSigFirstTimeoutTime" BU_SG_REL_ IC3 SG_ 1507 DiagFaultStat_CCM_DtcIdB_ISig_4 24000;
BA_REL_ "GenSigTimeoutTime" BU_SG_REL_ IC3 SG_ 1507 DiagFaultStat_CCM_DtcIdB_ISig_4 6000;
BA_REL_ "GenSigFirstTimeoutTime" BU_SG_REL_ IC3 SG_ 1507 DiagFaultStat_CCM_EcuAdr_ISig_4 24000;
BA_REL_ "GenSigTimeoutTime" BU_SG_REL_ IC3 SG_ 1507 DiagFaultStat_CCM_EcuAdr_ISig_4 6000;
BA_REL_ "GenSigFirstTimeoutTime" BU_SG_REL_ IC3 SG_ 1507 DiagFaultStat_CCM_FailTA_ISig_4 24000;
BA_REL_ "GenSigTimeoutTime" BU_SG_REL_ IC3 SG_ 1507 DiagFaultStat_CCM_FailTA_ISig_4 6000;
BA_REL_ "GenSigFirstTimeoutTime" BU_SG_REL_ IC3 SG_ 1490 DiagFaultStat_CCIOM_EcuAdr_ISig_ 24000;
BA_REL_ "GenSigTimeoutTime" BU_SG_REL_ IC3 SG_ 1490 DiagFaultStat_CCIOM_EcuAdr_ISig_ 6000;
BA_REL_ "GenSigFirstTimeoutTime" BU_SG_REL_ IC3 SG_ 1490 DiagFaultStat_CCIOM_FailTA_ISig_ 24000;
BA_REL_ "GenSigTimeoutTime" BU_SG_REL_ IC3 SG_ 1490 DiagFaultStat_CCIOM_FailTA_ISig_ 6000;
BA_REL_ "GenSigFirstTimeoutTime" BU_SG_REL_ IC3 SG_ 1490 DiagFaultStat_CCIOM_DtcIdB_ISig_ 24000;
BA_REL_ "GenSigTimeoutTime" BU_SG_REL_ IC3 SG_ 1490 DiagFaultStat_CCIOM_DtcIdB_ISig_ 6000;
BA_REL_ "GenSigFirstTimeoutTime" BU_SG_REL_ IC3 SG_ 1490 DiagFaultStat_CCIOM_DtcIdA_ISig_ 24000;
BA_REL_ "GenSigTimeoutTime" BU_SG_REL_ IC3 SG_ 1490 DiagFaultStat_CCIOM_DtcIdA_ISig_ 6000;
BA_REL_ "GenSigFirstTimeoutTime" BU_SG_REL_ IC3 SG_ 1490 DiagFaultStat_CCIOM_FailTB_ISig_ 24000;
BA_REL_ "GenSigTimeoutTime" BU_SG_REL_ IC3 SG_ 1490 DiagFaultStat_CCIOM_FailTB_ISig_ 6000;
BA_REL_ "GenSigFirstTimeoutTime" BU_SG_REL_ IC3 SG_ 1494 DiagFaultStat_BPMU_EcuAdr_ISig_4 24000;
BA_REL_ "GenSigTimeoutTime" BU_SG_REL_ IC3 SG_ 1494 DiagFaultStat_BPMU_EcuAdr_ISig_4 6000;
BA_REL_ "GenSigFirstTimeoutTime" BU_SG_REL_ IC3 SG_ 1494 DiagFaultStat_BPMU_DtcIdB_ISig_4 24000;
BA_REL_ "GenSigTimeoutTime" BU_SG_REL_ IC3 SG_ 1494 DiagFaultStat_BPMU_DtcIdB_ISig_4 6000;
BA_REL_ "GenSigFirstTimeoutTime" BU_SG_REL_ IC3 SG_ 1494 DiagFaultStat_BPMU_FailTB_ISig_4 24000;
BA_REL_ "GenSigTimeoutTime" BU_SG_REL_ IC3 SG_ 1494 DiagFaultStat_BPMU_FailTB_ISig_4 6000;
BA_REL_ "GenSigFirstTimeoutTime" BU_SG_REL_ IC3 SG_ 1494 DiagFaultStat_BPMU_FailTA_ISig_4 24000;
BA_REL_ "GenSigTimeoutTime" BU_SG_REL_ IC3 SG_ 1494 DiagFaultStat_BPMU_FailTA_ISig_4 6000;
BA_REL_ "GenSigFirstTimeoutTime" BU_SG_REL_ IC3 SG_ 1494 DiagFaultStat_BPMU_DtcIdA_ISig_4 24000;
BA_REL_ "GenSigTimeoutTime" BU_SG_REL_ IC3 SG_ 1494 DiagFaultStat_BPMU_DtcIdA_ISig_4 6000;
BA_REL_ "GenSigFirstTimeoutTime" BU_SG_REL_ IC3 SG_ 1506 DiagFaultStat_BBM_EcuAdr_ISig_4 24000;
BA_REL_ "GenSigTimeoutTime" BU_SG_REL_ IC3 SG_ 1506 DiagFaultStat_BBM_EcuAdr_ISig_4 6000;
BA_REL_ "GenSigFirstTimeoutTime" BU_SG_REL_ IC3 SG_ 1506 DiagFaultStat_BBM_DtcIdB_ISig_4 24000;
BA_REL_ "GenSigTimeoutTime" BU_SG_REL_ IC3 SG_ 1506 DiagFaultStat_BBM_DtcIdB_ISig_4 6000;
BA_REL_ "GenSigFirstTimeoutTime" BU_SG_REL_ IC3 SG_ 1506 DiagFaultStat_BBM_FailTB_ISig_4 24000;
BA_REL_ "GenSigTimeoutTime" BU_SG_REL_ IC3 SG_ 1506 DiagFaultStat_BBM_FailTB_ISig_4 6000;
BA_REL_ "GenSigFirstTimeoutTime" BU_SG_REL_ IC3 SG_ 1506 DiagFaultStat_BBM_DtcIdA_ISig_4 24000;
BA_REL_ "GenSigTimeoutTime" BU_SG_REL_ IC3 SG_ 1506 DiagFaultStat_BBM_DtcIdA_ISig_4 6000;
BA_REL_ "GenSigFirstTimeoutTime" BU_SG_REL_ IC3 SG_ 1506 DiagFaultStat_BBM_FailTA_ISig_4 24000;
BA_REL_ "GenSigTimeoutTime" BU_SG_REL_ IC3 SG_ 1506 DiagFaultStat_BBM_FailTA_ISig_4 6000;
BA_REL_ "GenSigFirstTimeoutTime" BU_SG_REL_ IC3 SG_ 1505 DiagFaultStat_BBIOM_FailTA_ISig_ 24000;
BA_REL_ "GenSigTimeoutTime" BU_SG_REL_ IC3 SG_ 1505 DiagFaultStat_BBIOM_FailTA_ISig_ 6000;
BA_REL_ "GenSigFirstTimeoutTime" BU_SG_REL_ IC3 SG_ 1505 DiagFaultStat_BBIOM_FailTB_ISig_ 24000;
BA_REL_ "GenSigTimeoutTime" BU_SG_REL_ IC3 SG_ 1505 DiagFaultStat_BBIOM_FailTB_ISig_ 6000;
BA_REL_ "GenSigFirstTimeoutTime" BU_SG_REL_ IC3 SG_ 1505 DiagFaultStat_BBIOM_DtcIdB_ISig_ 24000;
BA_REL_ "GenSigTimeoutTime" BU_SG_REL_ IC3 SG_ 1505 DiagFaultStat_BBIOM_DtcIdB_ISig_ 6000;
BA_REL_ "GenSigFirstTimeoutTime" BU_SG_REL_ IC3 SG_ 1505 DiagFaultStat_BBIOM_DtcIdA_ISig_ 24000;
BA_REL_ "GenSigTimeoutTime" BU_SG_REL_ IC3 SG_ 1505 DiagFaultStat_BBIOM_DtcIdA_ISig_ 6000;
BA_REL_ "GenSigFirstTimeoutTime" BU_SG_REL_ IC3 SG_ 1505 DiagFaultStat_BBIOM_EcuAdr_ISig_ 24000;
BA_REL_ "GenSigTimeoutTime" BU_SG_REL_ IC3 SG_ 1505 DiagFaultStat_BBIOM_EcuAdr_ISig_ 6000;
BA_REL_ "GenSigFirstTimeoutTime" BU_SG_REL_ IC3 SG_ 1504 DiagFaultStat_Alarm_DtcIdA_ISig_ 24000;
BA_REL_ "GenSigTimeoutTime" BU_SG_REL_ IC3 SG_ 1504 DiagFaultStat_Alarm_DtcIdA_ISig_ 6000;
BA_REL_ "GenSigFirstTimeoutTime" BU_SG_REL_ IC3 SG_ 1504 DiagFaultStat_Alarm_EcuAdr_ISig_ 24000;
BA_REL_ "GenSigTimeoutTime" BU_SG_REL_ IC3 SG_ 1504 DiagFaultStat_Alarm_EcuAdr_ISig_ 6000;
BA_REL_ "GenSigFirstTimeoutTime" BU_SG_REL_ IC3 SG_ 1504 DiagFaultStat_Alarm_FailTB_ISig_ 24000;
BA_REL_ "GenSigTimeoutTime" BU_SG_REL_ IC3 SG_ 1504 DiagFaultStat_Alarm_FailTB_ISig_ 6000;
BA_REL_ "GenSigFirstTimeoutTime" BU_SG_REL_ IC3 SG_ 1504 DiagFaultStat_Alarm_FailTA_ISig_ 24000;
BA_REL_ "GenSigTimeoutTime" BU_SG_REL_ IC3 SG_ 1504 DiagFaultStat_Alarm_FailTA_ISig_ 6000;
BA_REL_ "GenSigFirstTimeoutTime" BU_SG_REL_ IC3 SG_ 1504 DiagFaultStat_Alarm_DtcIdB_ISig_ 24000;
BA_REL_ "GenSigTimeoutTime" BU_SG_REL_ IC3 SG_ 1504 DiagFaultStat_Alarm_DtcIdB_ISig_ 6000;
BA_REL_ "GenSigFirstTimeoutTime" BU_SG_REL_ IC3 SG_ 1489 DiagFaultStat_APM_DtcIdA_ISig_4 12000;
BA_REL_ "GenSigTimeoutTime" BU_SG_REL_ IC3 SG_ 1489 DiagFaultStat_APM_DtcIdA_ISig_4 3000;
BA_REL_ "GenSigFirstTimeoutTime" BU_SG_REL_ IC3 SG_ 1489 DiagFaultStat_APM_EcuAdr_ISig_4 12000;
BA_REL_ "GenSigTimeoutTime" BU_SG_REL_ IC3 SG_ 1489 DiagFaultStat_APM_EcuAdr_ISig_4 3000;
BA_REL_ "GenSigFirstTimeoutTime" BU_SG_REL_ IC3 SG_ 1489 DiagFaultStat_APM_FailTB_ISig_4 12000;
BA_REL_ "GenSigTimeoutTime" BU_SG_REL_ IC3 SG_ 1489 DiagFaultStat_APM_FailTB_ISig_4 3000;
BA_REL_ "GenSigFirstTimeoutTime" BU_SG_REL_ IC3 SG_ 1489 DiagFaultStat_APM_DtcIdB_ISig_4 12000;
BA_REL_ "GenSigTimeoutTime" BU_SG_REL_ IC3 SG_ 1489 DiagFaultStat_APM_DtcIdB_ISig_4 3000;
BA_REL_ "GenSigFirstTimeoutTime" BU_SG_REL_ IC3 SG_ 1489 DiagFaultStat_APM_FailTA_ISig_4 12000;
BA_REL_ "GenSigTimeoutTime" BU_SG_REL_ IC3 SG_ 1489 DiagFaultStat_APM_FailTA_ISig_4 3000;
BA_REL_ "GenSigFirstTimeoutTime" BU_SG_REL_ IC3 SG_ 1191 PS_TrafficSitPathEvt1_Type 3000;
BA_REL_ "GenSigTimeoutTime" BU_SG_REL_ IC3 SG_ 1191 PS_TrafficSitPathEvt1_Type 600;
BA_REL_ "GenSigFirstTimeoutTime" BU_SG_REL_ IC3 SG_ 1191 PS_TrafficSitPathEvt2_Distance 3000;
BA_REL_ "GenSigTimeoutTime" BU_SG_REL_ IC3 SG_ 1191 PS_TrafficSitPathEvt2_Distance 600;
BA_REL_ "GenSigFirstTimeoutTime" BU_SG_REL_ IC3 SG_ 1191 PS_TrafficSitPathEvt2_Speed 3000;
BA_REL_ "GenSigTimeoutTime" BU_SG_REL_ IC3 SG_ 1191 PS_TrafficSitPathEvt2_Speed 600;
BA_REL_ "GenSigFirstTimeoutTime" BU_SG_REL_ IC3 SG_ 1191 PS_TrafficSitPathEvt2_Type 3000;
BA_REL_ "GenSigTimeoutTime" BU_SG_REL_ IC3 SG_ 1191 PS_TrafficSitPathEvt2_Type 600;
BA_REL_ "GenSigFirstTimeoutTime" BU_SG_REL_ IC3 SG_ 1191 PS_TrafficSitPathEvt1_Speed 3000;
BA_REL_ "GenSigTimeoutTime" BU_SG_REL_ IC3 SG_ 1191 PS_TrafficSitPathEvt1_Speed 600;
BA_REL_ "GenSigFirstTimeoutTime" BU_SG_REL_ IC3 SG_ 1191 PS_TrafficSitPathEvt1_Distance 3000;
BA_REL_ "GenSigTimeoutTime" BU_SG_REL_ IC3 SG_ 1191 PS_TrafficSitPathEvt1_Distance 600;
BA_REL_ "GenSigFirstTimeoutTime" BU_SG_REL_ IC3 SG_ 1484 DACU_Available_Log_ISig_4 60000;
BA_REL_ "GenSigTimeoutTime" BU_SG_REL_ IC3 SG_ 1484 DACU_Available_Log_ISig_4 30000;
BA_REL_ "GenSigFirstTimeoutTime" BU_SG_REL_ IC3 SG_ 1253 LSMS_RevDirSupportUASens1 6000;
BA_REL_ "GenSigTimeoutTime" BU_SG_REL_ IC3 SG_ 1253 LSMS_RevDirSupportUASens1 1500;
BA_REL_ "GenSigFirstTimeoutTime" BU_SG_REL_ IC3 SG_ 1253 LSMS_KnbSteerUASens1 6000;
BA_REL_ "GenSigTimeoutTime" BU_SG_REL_ IC3 SG_ 1253 LSMS_KnbSteerUASens1 1500;
BA_REL_ "GenSigFirstTimeoutTime" BU_SG_REL_ IC3 SG_ 1253 LSMS_RevDirSupportUAPreCon1 6000;
BA_REL_ "GenSigTimeoutTime" BU_SG_REL_ IC3 SG_ 1253 LSMS_RevDirSupportUAPreCon1 1500;
BA_REL_ "GenSigFirstTimeoutTime" BU_SG_REL_ IC3 SG_ 1253 LSMS_UndoUAPreCon1 6000;
BA_REL_ "GenSigTimeoutTime" BU_SG_REL_ IC3 SG_ 1253 LSMS_UndoUAPreCon1 1500;
BA_REL_ "GenSigFirstTimeoutTime" BU_SG_REL_ IC3 SG_ 1253 LSMS_KnbSteerUAPreCon1 6000;
BA_REL_ "GenSigTimeoutTime" BU_SG_REL_ IC3 SG_ 1253 LSMS_KnbSteerUAPreCon1 1500;
BA_REL_ "GenSigFirstTimeoutTime" BU_SG_REL_ IC3 SG_ 1253 LSMS_UndoUASens1 6000;
BA_REL_ "GenSigTimeoutTime" BU_SG_REL_ IC3 SG_ 1253 LSMS_UndoUASens1 1500;
BA_REL_ "GenSigFirstTimeoutTime" BU_SG_REL_ IC3 SG_ 1082 LSMS_KnobAngle1 3000;
BA_REL_ "GenSigTimeoutTime" BU_SG_REL_ IC3 SG_ 1082 LSMS_KnobAngle1 600;
BA_REL_ "GenSigFirstTimeoutTime" BU_SG_REL_ IC3 SG_ 1082 FrontRoadWheelAngleEstimate1 3000;
BA_REL_ "GenSigTimeoutTime" BU_SG_REL_ IC3 SG_ 1082 FrontRoadWheelAngleEstimate1 600;
BA_REL_ "GenSigFirstTimeoutTime" BU_SG_REL_ IC3 SG_ 1082 LSMS_RecordedPathLeft1 3000;
BA_REL_ "GenSigTimeoutTime" BU_SG_REL_ IC3 SG_ 1082 LSMS_RecordedPathLeft1 600;
BA_REL_ "GenSigFirstTimeoutTime" BU_SG_REL_ IC3 SG_ 1082 LSMS_AngleMatch1 3000;
BA_REL_ "GenSigTimeoutTime" BU_SG_REL_ IC3 SG_ 1082 LSMS_AngleMatch1 600;
BA_REL_ "GenSigFirstTimeoutTime" BU_SG_REL_ IC3 SG_ 1082 LSMS_LED_IndicationCmd_ISig_4 3000;
BA_REL_ "GenSigTimeoutTime" BU_SG_REL_ IC3 SG_ 1082 LSMS_LED_IndicationCmd_ISig_4 600;
BA_REL_ "GenSigFirstTimeoutTime" BU_SG_REL_ IC3 SG_ 1082 LSMS_FunctionState1 3000;
BA_REL_ "GenSigTimeoutTime" BU_SG_REL_ IC3 SG_ 1082 LSMS_FunctionState1 600;
BA_REL_ "GenSigFirstTimeoutTime" BU_SG_REL_ IC3 SG_ 1082 LSMS_JackKnifeWarning1 3000;
BA_REL_ "GenSigTimeoutTime" BU_SG_REL_ IC3 SG_ 1082 LSMS_JackKnifeWarning1 600;
BA_REL_ "GenSigFirstTimeoutTime" BU_SG_REL_ IC3 SG_ 1079 LSMS_ReqstdArticlatnAngle2_1 3000;
BA_REL_ "GenSigTimeoutTime" BU_SG_REL_ IC3 SG_ 1079 LSMS_ReqstdArticlatnAngle2_1 600;
BA_REL_ "GenSigFirstTimeoutTime" BU_SG_REL_ IC3 SG_ 1079 LSMS_ReqstdArticlatnAngle1_1 3000;
BA_REL_ "GenSigTimeoutTime" BU_SG_REL_ IC3 SG_ 1079 LSMS_ReqstdArticlatnAngle1_1 600;
BA_REL_ "GenSigFirstTimeoutTime" BU_SG_REL_ IC3 SG_ 1079 LSMS_TrailrArticlatnAngle2_1 3000;
BA_REL_ "GenSigTimeoutTime" BU_SG_REL_ IC3 SG_ 1079 LSMS_TrailrArticlatnAngle2_1 600;
BA_REL_ "GenSigFirstTimeoutTime" BU_SG_REL_ IC3 SG_ 1079 LSMS_TrailrArticlatnAngle1_1 3000;
BA_REL_ "GenSigTimeoutTime" BU_SG_REL_ IC3 SG_ 1079 LSMS_TrailrArticlatnAngle1_1 600;
BA_REL_ "GenSigFirstTimeoutTime" BU_SG_REL_ IC3 SG_ 1338 RoadSpeedRestriction 12000;
BA_REL_ "GenSigTimeoutTime" BU_SG_REL_ IC3 SG_ 1338 RoadSpeedRestriction 3000;
BA_REL_ "GenSigFirstTimeoutTime" BU_SG_REL_ IC3 SG_ 1338 ObserveRoadRestriction_OpCap 12000;
BA_REL_ "GenSigTimeoutTime" BU_SG_REL_ IC3 SG_ 1338 ObserveRoadRestriction_OpCap 3000;
BA_REL_ "GenSigFirstTimeoutTime" BU_SG_REL_ IC3 SG_ 1338 RoadSpeedUnitType 12000;
BA_REL_ "GenSigTimeoutTime" BU_SG_REL_ IC3 SG_ 1338 RoadSpeedUnitType 3000;
BA_REL_ "GenSigFirstTimeoutTime" BU_SG_REL_ IC3 SG_ 1338 RoadOvertakingRestriction 12000;
BA_REL_ "GenSigTimeoutTime" BU_SG_REL_ IC3 SG_ 1338 RoadOvertakingRestriction 3000;
BA_REL_ "GenSigFirstTimeoutTime" BU_SG_REL_ IC3 SG_ 1338 RoadTypeSpeedRestriction 12000;
BA_REL_ "GenSigTimeoutTime" BU_SG_REL_ IC3 SG_ 1338 RoadTypeSpeedRestriction 3000;
BA_REL_ "GenSigFirstTimeoutTime" BU_SG_REL_ IC3 SG_ 1338 ObserveRoadRestrictionStatus 12000;
BA_REL_ "GenSigTimeoutTime" BU_SG_REL_ IC3 SG_ 1338 ObserveRoadRestrictionStatus 3000;
VAL_ 1191 PS_TrafficSitPathEvt1_Type 255 "TrafficSitEventType_NotAvailable" 254 "TrafficSitEventType_Error" 253 "TrafficSitEventType_NotUsed3" 252 "TrafficSitEventType_NotUsed2" 251 "TrafficSitEventType_NotUsed1" 250 "TrafficSitEventType_GeneralEvent" 249 "TrafficSitEventType_spare242" 248 "TrafficSitEventType_spare241" 247 "TrafficSitEventType_spare240" 246 "TrafficSitEventType_spare239" 245 "TrafficSitEventType_spare238" 244 "TrafficSitEventType_spare237" 243 "TrafficSitEventType_spare236" 242 "TrafficSitEventType_spare235" 241 "TrafficSitEventType_spare234" 240 "TrafficSitEventType_spare233" 239 "TrafficSitEventType_spare232" 238 "TrafficSitEventType_spare231" 237 "TrafficSitEventType_spare230" 236 "TrafficSitEventType_spare229" 235 "TrafficSitEventType_spare228" 234 "TrafficSitEventType_spare227" 233 "TrafficSitEventType_spare226" 232 "TrafficSitEventType_spare225" 231 "TrafficSitEventType_spare224" 230 "TrafficSitEventType_spare223" 229 "TrafficSitEventType_spare222" 228 "TrafficSitEventType_spare221" 227 "TrafficSitEventType_spare220" 226 "TrafficSitEventType_spare219" 225 "TrafficSitEventType_spare218" 224 "TrafficSitEventType_spare217" 223 "TrafficSitEventType_spare216" 222 "TrafficSitEventType_spare215" 221 "TrafficSitEventType_spare214" 220 "TrafficSitEventType_spare213" 219 "TrafficSitEventType_spare212" 218 "TrafficSitEventType_spare211" 217 "TrafficSitEventType_spare210" 216 "TrafficSitEventType_spare209" 215 "TrafficSitEventType_spare208" 214 "TrafficSitEventType_spare207" 213 "TrafficSitEventType_spare206" 212 "TrafficSitEventType_spare205" 211 "TrafficSitEventType_spare204" 210 "TrafficSitEventType_spare203" 209 "TrafficSitEventType_spare202" 208 "TrafficSitEventType_spare201" 207 "TrafficSitEventType_spare200" 206 "TrafficSitEventType_spare199" 205 "TrafficSitEventType_spare198" 204 "TrafficSitEventType_spare197" 203 "TrafficSitEventType_spare196" 202 "TrafficSitEventType_spare195" 201 "TrafficSitEventType_spare194" 200 "TrafficSitEventType_spare193" 199 "TrafficSitEventType_spare192" 198 "TrafficSitEventType_spare191" 197 "TrafficSitEventType_spare190" 196 "TrafficSitEventType_spare189" 195 "TrafficSitEventType_spare188" 194 "TrafficSitEventType_spare187" 193 "TrafficSitEventType_spare186" 192 "TrafficSitEventType_spare185" 191 "TrafficSitEventType_spare184" 190 "TrafficSitEventType_spare183" 189 "TrafficSitEventType_spare182" 188 "TrafficSitEventType_spare181" 187 "TrafficSitEventType_spare180" 186 "TrafficSitEventType_spare179" 185 "TrafficSitEventType_spare178" 184 "TrafficSitEventType_spare177" 183 "TrafficSitEventType_spare176" 182 "TrafficSitEventType_spare175" 181 "TrafficSitEventType_spare174" 180 "TrafficSitEventType_spare173" 179 "TrafficSitEventType_spare172" 178 "TrafficSitEventType_spare171" 177 "TrafficSitEventType_spare170" 176 "TrafficSitEventType_spare169" 175 "TrafficSitEventType_spare168" 174 "TrafficSitEventType_spare167" 173 "TrafficSitEventType_spare166" 172 "TrafficSitEventType_spare165" 171 "TrafficSitEventType_spare164" 170 "TrafficSitEventType_spare163" 169 "TrafficSitEventType_spare162" 168 "TrafficSitEventType_spare161" 167 "TrafficSitEventType_spare160" 166 "TrafficSitEventType_spare159" 165 "TrafficSitEventType_spare158" 164 "TrafficSitEventType_spare157" 163 "TrafficSitEventType_spare156" 162 "TrafficSitEventType_spare155" 161 "TrafficSitEventType_spare154" 160 "TrafficSitEventType_spare153" 159 "TrafficSitEventType_spare152" 158 "TrafficSitEventType_spare151" 157 "TrafficSitEventType_spare150" 156 "TrafficSitEventType_spare149" 155 "TrafficSitEventType_spare148" 154 "TrafficSitEventType_spare147" 153 "TrafficSitEventType_spare146" 152 "TrafficSitEventType_spare145" 151 "TrafficSitEventType_spare144" 150 "TrafficSitEventType_spare143" 149 "TrafficSitEventType_spare142" 148 "TrafficSitEventType_spare141" 147 "TrafficSitEventType_spare140" 146 "TrafficSitEventType_spare139" 145 "TrafficSitEventType_spare138" 144 "TrafficSitEventType_spare137" 143 "TrafficSitEventType_spare136" 142 "TrafficSitEventType_spare135" 141 "TrafficSitEventType_spare134" 140 "TrafficSitEventType_spare133" 139 "TrafficSitEventType_spare132" 138 "TrafficSitEventType_spare131" 137 "TrafficSitEventType_spare130" 136 "TrafficSitEventType_spare129" 135 "TrafficSitEventType_spare128" 134 "TrafficSitEventType_spare127" 133 "TrafficSitEventType_spare126" 132 "TrafficSitEventType_spare125" 131 "TrafficSitEventType_spare124" 130 "TrafficSitEventType_spare123" 129 "TrafficSitEventType_spare122" 128 "TrafficSitEventType_spare121" 127 "TrafficSitEventType_spare120" 126 "TrafficSitEventType_spare119" 125 "TrafficSitEventType_spare118" 124 "TrafficSitEventType_spare117" 123 "TrafficSitEventType_spare116" 122 "TrafficSitEventType_spare115" 121 "TrafficSitEventType_spare114" 120 "TrafficSitEventType_spare113" 119 "TrafficSitEventType_spare112" 118 "TrafficSitEventType_spare111" 117 "TrafficSitEventType_spare110" 116 "TrafficSitEventType_spare109" 115 "TrafficSitEventType_spare108" 114 "TrafficSitEventType_spare107" 113 "TrafficSitEventType_spare106" 112 "TrafficSitEventType_spare105" 111 "TrafficSitEventType_spare104" 110 "TrafficSitEventType_spare103" 109 "TrafficSitEventType_spare102" 108 "TrafficSitEventType_spare101" 107 "TrafficSitEventType_spare100" 106 "TrafficSitEventType_spare99" 105 "TrafficSitEventType_spare98" 104 "TrafficSitEventType_spare97" 103 "TrafficSitEventType_spare96" 102 "TrafficSitEventType_spare95" 101 "TrafficSitEventType_spare94" 100 "TrafficSitEventType_spare93" 99 "TrafficSitEventType_spare92" 98 "TrafficSitEventType_spare91" 97 "TrafficSitEventType_spare90" 96 "TrafficSitEventType_spare89" 95 "TrafficSitEventType_spare88" 94 "TrafficSitEventType_spare87" 93 "TrafficSitEventType_spare86" 92 "TrafficSitEventType_spare85" 91 "TrafficSitEventType_spare84" 90 "TrafficSitEventType_spare83" 89 "TrafficSitEventType_spare82" 88 "TrafficSitEventType_spare81" 87 "TrafficSitEventType_spare80" 86 "TrafficSitEventType_spare79" 85 "TrafficSitEventType_spare78" 84 "TrafficSitEventType_spare77" 83 "TrafficSitEventType_spare76" 82 "TrafficSitEventType_spare75" 81 "TrafficSitEventType_spare74" 80 "TrafficSitEventType_spare73" 79 "TrafficSitEventType_spare72" 78 "TrafficSitEventType_spare71" 77 "TrafficSitEventType_spare70" 76 "TrafficSitEventType_spare69" 75 "TrafficSitEventType_spare68" 74 "TrafficSitEventType_spare67" 73 "TrafficSitEventType_spare66" 72 "TrafficSitEventType_spare65" 71 "TrafficSitEventType_spare64" 70 "TrafficSitEventType_spare63" 69 "TrafficSitEventType_spare62" 68 "TrafficSitEventType_spare61" 67 "TrafficSitEventType_spare60" 66 "TrafficSitEventType_spare59" 65 "TrafficSitEventType_spare58" 64 "TrafficSitEventType_spare57" 63 "TrafficSitEventType_spare56" 62 "TrafficSitEventType_spare55" 61 "TrafficSitEventType_spare54" 60 "TrafficSitEventType_spare53" 59 "TrafficSitEventType_spare52" 58 "TrafficSitEventType_spare51" 57 "TrafficSitEventType_spare50" 56 "TrafficSitEventType_spare49" 55 "TrafficSitEventType_spare48" 54 "TrafficSitEventType_spare47" 53 "TrafficSitEventType_spare46" 52 "TrafficSitEventType_spare45" 51 "TrafficSitEventType_spare44" 50 "TrafficSitEventType_spare43" 49 "TrafficSitEventType_spare42" 48 "TrafficSitEventType_spare41" 47 "TrafficSitEventType_spare40" 46 "TrafficSitEventType_spare39" 45 "TrafficSitEventType_spare38" 44 "TrafficSitEventType_spare37" 43 "TrafficSitEventType_spare36" 42 "TrafficSitEventType_spare35" 41 "TrafficSitEventType_spare34" 40 "TrafficSitEventType_spare33" 39 "TrafficSitEventType_spare32" 38 "TrafficSitEventType_spare31" 37 "TrafficSitEventType_spare30" 36 "TrafficSitEventType_spare29" 35 "TrafficSitEventType_spare28" 34 "TrafficSitEventType_spare27" 33 "TrafficSitEventType_spare26" 32 "TrafficSitEventType_spare25" 31 "TrafficSitEventType_spare24" 30 "TrafficSitEventType_spare23" 29 "TrafficSitEventType_spare22" 28 "TrafficSitEventType_spare21" 27 "TrafficSitEventType_spare20" 26 "TrafficSitEventType_spare19" 25 "TrafficSitEventType_spare18" 24 "TrafficSitEventType_spare17" 23 "TrafficSitEventType_spare16" 22 "TrafficSitEventType_spare15" 21 "TrafficSitEventType_spare14" 20 "TrafficSitEventType_spare13" 19 "TrafficSitEventType_spare12" 18 "TrafficSitEventType_spare11" 17 "TrafficSitEventType_spare10" 16 "TrafficSitEventType_spare9" 15 "TrafficSitEventType_spare8" 14 "TrafficSitEventType_spare7" 13 "TrafficSitEventType_spare6" 12 "TrafficSitEventType_spare5" 11 "TrafficSitEventType_spare4" 10 "TrafficSitEventType_spare3" 9 "TrafficSitEventType_spare2" 8 "TrafficSitEventType_spare1" 7 "TrafficSitEventType_NarrowRoad" 6 "TrafficSitEventType_TrafficJam_OR_SlowTraffic" 5 "TrafficSitEventType_Crossing" 4 "TrafficSitEventType_Roundabout" 3 "TrafficSitEventType_CurveRight" 2 "TrafficSitEventType_CurveLeft" 1 "TrafficSitEventType_SpeedLimit" 0 "TrafficSitEventType_NoEvent" ;
VAL_ 1191 PS_TrafficSitPathEvt2_Type 255 "TrafficSitEventType_NotAvailable" 254 "TrafficSitEventType_Error" 253 "TrafficSitEventType_NotUsed3" 252 "TrafficSitEventType_NotUsed2" 251 "TrafficSitEventType_NotUsed1" 250 "TrafficSitEventType_GeneralEvent" 249 "TrafficSitEventType_spare242" 248 "TrafficSitEventType_spare241" 247 "TrafficSitEventType_spare240" 246 "TrafficSitEventType_spare239" 245 "TrafficSitEventType_spare238" 244 "TrafficSitEventType_spare237" 243 "TrafficSitEventType_spare236" 242 "TrafficSitEventType_spare235" 241 "TrafficSitEventType_spare234" 240 "TrafficSitEventType_spare233" 239 "TrafficSitEventType_spare232" 238 "TrafficSitEventType_spare231" 237 "TrafficSitEventType_spare230" 236 "TrafficSitEventType_spare229" 235 "TrafficSitEventType_spare228" 234 "TrafficSitEventType_spare227" 233 "TrafficSitEventType_spare226" 232 "TrafficSitEventType_spare225" 231 "TrafficSitEventType_spare224" 230 "TrafficSitEventType_spare223" 229 "TrafficSitEventType_spare222" 228 "TrafficSitEventType_spare221" 227 "TrafficSitEventType_spare220" 226 "TrafficSitEventType_spare219" 225 "TrafficSitEventType_spare218" 224 "TrafficSitEventType_spare217" 223 "TrafficSitEventType_spare216" 222 "TrafficSitEventType_spare215" 221 "TrafficSitEventType_spare214" 220 "TrafficSitEventType_spare213" 219 "TrafficSitEventType_spare212" 218 "TrafficSitEventType_spare211" 217 "TrafficSitEventType_spare210" 216 "TrafficSitEventType_spare209" 215 "TrafficSitEventType_spare208" 214 "TrafficSitEventType_spare207" 213 "TrafficSitEventType_spare206" 212 "TrafficSitEventType_spare205" 211 "TrafficSitEventType_spare204" 210 "TrafficSitEventType_spare203" 209 "TrafficSitEventType_spare202" 208 "TrafficSitEventType_spare201" 207 "TrafficSitEventType_spare200" 206 "TrafficSitEventType_spare199" 205 "TrafficSitEventType_spare198" 204 "TrafficSitEventType_spare197" 203 "TrafficSitEventType_spare196" 202 "TrafficSitEventType_spare195" 201 "TrafficSitEventType_spare194" 200 "TrafficSitEventType_spare193" 199 "TrafficSitEventType_spare192" 198 "TrafficSitEventType_spare191" 197 "TrafficSitEventType_spare190" 196 "TrafficSitEventType_spare189" 195 "TrafficSitEventType_spare188" 194 "TrafficSitEventType_spare187" 193 "TrafficSitEventType_spare186" 192 "TrafficSitEventType_spare185" 191 "TrafficSitEventType_spare184" 190 "TrafficSitEventType_spare183" 189 "TrafficSitEventType_spare182" 188 "TrafficSitEventType_spare181" 187 "TrafficSitEventType_spare180" 186 "TrafficSitEventType_spare179" 185 "TrafficSitEventType_spare178" 184 "TrafficSitEventType_spare177" 183 "TrafficSitEventType_spare176" 182 "TrafficSitEventType_spare175" 181 "TrafficSitEventType_spare174" 180 "TrafficSitEventType_spare173" 179 "TrafficSitEventType_spare172" 178 "TrafficSitEventType_spare171" 177 "TrafficSitEventType_spare170" 176 "TrafficSitEventType_spare169" 175 "TrafficSitEventType_spare168" 174 "TrafficSitEventType_spare167" 173 "TrafficSitEventType_spare166" 172 "TrafficSitEventType_spare165" 171 "TrafficSitEventType_spare164" 170 "TrafficSitEventType_spare163" 169 "TrafficSitEventType_spare162" 168 "TrafficSitEventType_spare161" 167 "TrafficSitEventType_spare160" 166 "TrafficSitEventType_spare159" 165 "TrafficSitEventType_spare158" 164 "TrafficSitEventType_spare157" 163 "TrafficSitEventType_spare156" 162 "TrafficSitEventType_spare155" 161 "TrafficSitEventType_spare154" 160 "TrafficSitEventType_spare153" 159 "TrafficSitEventType_spare152" 158 "TrafficSitEventType_spare151" 157 "TrafficSitEventType_spare150" 156 "TrafficSitEventType_spare149" 155 "TrafficSitEventType_spare148" 154 "TrafficSitEventType_spare147" 153 "TrafficSitEventType_spare146" 152 "TrafficSitEventType_spare145" 151 "TrafficSitEventType_spare144" 150 "TrafficSitEventType_spare143" 149 "TrafficSitEventType_spare142" 148 "TrafficSitEventType_spare141" 147 "TrafficSitEventType_spare140" 146 "TrafficSitEventType_spare139" 145 "TrafficSitEventType_spare138" 144 "TrafficSitEventType_spare137" 143 "TrafficSitEventType_spare136" 142 "TrafficSitEventType_spare135" 141 "TrafficSitEventType_spare134" 140 "TrafficSitEventType_spare133" 139 "TrafficSitEventType_spare132" 138 "TrafficSitEventType_spare131" 137 "TrafficSitEventType_spare130" 136 "TrafficSitEventType_spare129" 135 "TrafficSitEventType_spare128" 134 "TrafficSitEventType_spare127" 133 "TrafficSitEventType_spare126" 132 "TrafficSitEventType_spare125" 131 "TrafficSitEventType_spare124" 130 "TrafficSitEventType_spare123" 129 "TrafficSitEventType_spare122" 128 "TrafficSitEventType_spare121" 127 "TrafficSitEventType_spare120" 126 "TrafficSitEventType_spare119" 125 "TrafficSitEventType_spare118" 124 "TrafficSitEventType_spare117" 123 "TrafficSitEventType_spare116" 122 "TrafficSitEventType_spare115" 121 "TrafficSitEventType_spare114" 120 "TrafficSitEventType_spare113" 119 "TrafficSitEventType_spare112" 118 "TrafficSitEventType_spare111" 117 "TrafficSitEventType_spare110" 116 "TrafficSitEventType_spare109" 115 "TrafficSitEventType_spare108" 114 "TrafficSitEventType_spare107" 113 "TrafficSitEventType_spare106" 112 "TrafficSitEventType_spare105" 111 "TrafficSitEventType_spare104" 110 "TrafficSitEventType_spare103" 109 "TrafficSitEventType_spare102" 108 "TrafficSitEventType_spare101" 107 "TrafficSitEventType_spare100" 106 "TrafficSitEventType_spare99" 105 "TrafficSitEventType_spare98" 104 "TrafficSitEventType_spare97" 103 "TrafficSitEventType_spare96" 102 "TrafficSitEventType_spare95" 101 "TrafficSitEventType_spare94" 100 "TrafficSitEventType_spare93" 99 "TrafficSitEventType_spare92" 98 "TrafficSitEventType_spare91" 97 "TrafficSitEventType_spare90" 96 "TrafficSitEventType_spare89" 95 "TrafficSitEventType_spare88" 94 "TrafficSitEventType_spare87" 93 "TrafficSitEventType_spare86" 92 "TrafficSitEventType_spare85" 91 "TrafficSitEventType_spare84" 90 "TrafficSitEventType_spare83" 89 "TrafficSitEventType_spare82" 88 "TrafficSitEventType_spare81" 87 "TrafficSitEventType_spare80" 86 "TrafficSitEventType_spare79" 85 "TrafficSitEventType_spare78" 84 "TrafficSitEventType_spare77" 83 "TrafficSitEventType_spare76" 82 "TrafficSitEventType_spare75" 81 "TrafficSitEventType_spare74" 80 "TrafficSitEventType_spare73" 79 "TrafficSitEventType_spare72" 78 "TrafficSitEventType_spare71" 77 "TrafficSitEventType_spare70" 76 "TrafficSitEventType_spare69" 75 "TrafficSitEventType_spare68" 74 "TrafficSitEventType_spare67" 73 "TrafficSitEventType_spare66" 72 "TrafficSitEventType_spare65" 71 "TrafficSitEventType_spare64" 70 "TrafficSitEventType_spare63" 69 "TrafficSitEventType_spare62" 68 "TrafficSitEventType_spare61" 67 "TrafficSitEventType_spare60" 66 "TrafficSitEventType_spare59" 65 "TrafficSitEventType_spare58" 64 "TrafficSitEventType_spare57" 63 "TrafficSitEventType_spare56" 62 "TrafficSitEventType_spare55" 61 "TrafficSitEventType_spare54" 60 "TrafficSitEventType_spare53" 59 "TrafficSitEventType_spare52" 58 "TrafficSitEventType_spare51" 57 "TrafficSitEventType_spare50" 56 "TrafficSitEventType_spare49" 55 "TrafficSitEventType_spare48" 54 "TrafficSitEventType_spare47" 53 "TrafficSitEventType_spare46" 52 "TrafficSitEventType_spare45" 51 "TrafficSitEventType_spare44" 50 "TrafficSitEventType_spare43" 49 "TrafficSitEventType_spare42" 48 "TrafficSitEventType_spare41" 47 "TrafficSitEventType_spare40" 46 "TrafficSitEventType_spare39" 45 "TrafficSitEventType_spare38" 44 "TrafficSitEventType_spare37" 43 "TrafficSitEventType_spare36" 42 "TrafficSitEventType_spare35" 41 "TrafficSitEventType_spare34" 40 "TrafficSitEventType_spare33" 39 "TrafficSitEventType_spare32" 38 "TrafficSitEventType_spare31" 37 "TrafficSitEventType_spare30" 36 "TrafficSitEventType_spare29" 35 "TrafficSitEventType_spare28" 34 "TrafficSitEventType_spare27" 33 "TrafficSitEventType_spare26" 32 "TrafficSitEventType_spare25" 31 "TrafficSitEventType_spare24" 30 "TrafficSitEventType_spare23" 29 "TrafficSitEventType_spare22" 28 "TrafficSitEventType_spare21" 27 "TrafficSitEventType_spare20" 26 "TrafficSitEventType_spare19" 25 "TrafficSitEventType_spare18" 24 "TrafficSitEventType_spare17" 23 "TrafficSitEventType_spare16" 22 "TrafficSitEventType_spare15" 21 "TrafficSitEventType_spare14" 20 "TrafficSitEventType_spare13" 19 "TrafficSitEventType_spare12" 18 "TrafficSitEventType_spare11" 17 "TrafficSitEventType_spare10" 16 "TrafficSitEventType_spare9" 15 "TrafficSitEventType_spare8" 14 "TrafficSitEventType_spare7" 13 "TrafficSitEventType_spare6" 12 "TrafficSitEventType_spare5" 11 "TrafficSitEventType_spare4" 10 "TrafficSitEventType_spare3" 9 "TrafficSitEventType_spare2" 8 "TrafficSitEventType_spare1" 7 "TrafficSitEventType_NarrowRoad" 6 "TrafficSitEventType_TrafficJam_OR_SlowTraffic" 5 "TrafficSitEventType_Crossing" 4 "TrafficSitEventType_Roundabout" 3 "TrafficSitEventType_CurveRight" 2 "TrafficSitEventType_CurveLeft" 1 "TrafficSitEventType_SpeedLimit" 0 "TrafficSitEventType_NoEvent" ;
VAL_ 1253 LSMS_RevDirSupportUASens1 7 "ReverseDirectionSupport_NotAvailable" 6 "ReverseDirectionSupport_Error" 5 "ReverseDirectionSupport_Spare4" 4 "ReverseDirectionSupport_Spare3" 3 "ReverseDirectionSupport_Spare2" 2 "ReverseDirectionSupport_Spare1" 1 "ReverseDirectionSupport_Unavailable" 0 "ReverseDirectionSupport_Available" ;
VAL_ 1253 LSMS_KnbSteerUASens1 7 "KnobSteerFunction_NotAvailable" 6 "KnobSteerFunction_Error" 5 "KnobSteerFunction_Spare5" 4 "KnobSteerFunction_Spare3" 3 "KnobSteerFunction_Spare2" 2 "KnobSteerFunction_Spare1" 1 "KnobSteerFunction_Unavailable" 0 "KnobSteerFunction_Available" ;
VAL_ 1253 LSMS_RevDirSupportUAPreCon1 7 "ReverseDirectionSupport_NotAvailable" 6 "ReverseDirectionSupport_Error" 5 "ReverseDirectionSupport_Spare4" 4 "ReverseDirectionSupport_Spare3" 3 "ReverseDirectionSupport_Spare2" 2 "ReverseDirectionSupport_Spare1" 1 "ReverseDirectionSupport_Unavailable" 0 "ReverseDirectionSupport_Available" ;
VAL_ 1253 LSMS_UndoUAPreCon1 7 "LSMS_UndoUAPreCon_NotAvailable" 6 "LSMS_UndoUAPreCon_Error" 5 "LSMS_UndoUAPreCon_Spare4" 4 "LSMS_UndoUAPreCon_Spare3" 3 "LSMS_UndoUAPreCon_Spare2" 2 "LSMS_UndoUAPreCon_Spare1" 1 "LSMS_UndoUAPreCon_Unavailable" 0 "LSMS_UndoUAPreCon_Available" ;
VAL_ 1253 LSMS_KnbSteerUAPreCon1 7 "KnobSteerFunction_NotAvailable" 6 "KnobSteerFunction_Error" 5 "KnobSteerFunction_Spare5" 4 "KnobSteerFunction_Spare3" 3 "KnobSteerFunction_Spare2" 2 "KnobSteerFunction_Spare1" 1 "KnobSteerFunction_Unavailable" 0 "KnobSteerFunction_Available" ;
VAL_ 1253 LSMS_UndoUASens1 7 "LSMS_UndoUASens_NotAvailable" 6 "LSMS_UndoUASens_Error" 5 "LSMS_UndoUASens_Spare4" 4 "LSMS_UndoUASens_Spare3" 3 "LSMS_UndoUASens_Spare2" 2 "LSMS_UndoUASens_Spare1" 1 "LSMS_UndoUASens_UndoUnavailable" 0 "LSMS_UndoUASens_UndoAvailable" ;
VAL_ 1082 LSMS_AngleMatch1 3 "LSMS_AngleMatch_NotAvailable" 2 "LSMS_AngleMatch_Error" 1 "LSMS_AngleMatch_Match" 0 "LSMS_AngleMatch_NoMatch" ;
VAL_ 1082 LSMS_LED_IndicationCmd_ISig_4 3 "OffOn_NotAvailable" 2 "OffOn_Error" 1 "OffOn_On" 0 "OffOn_Off" ;
VAL_ 1082 LSMS_FunctionState1 7 "LSMS_FunctionState_NotAvailable" 6 "LSMS_FunctionState_Error" 5 "LSMS_FunctionState_Spare2" 4 "LSMS_FunctionState_Spare1" 3 "LSMS_FunctionState_UNDO_FunctionActive" 2 "LSMS_FunctionState_RevDirSupportReverseFuncActive" 1 "LSMS_FunctionState_KnobSteer_RevDirSupportForwardFuncActive" 0 "LSMS_FunctionState_FunctionsNotActive" ;
VAL_ 1082 LSMS_JackKnifeWarning1 3 "InactiveActive_NotAvailable" 2 "InactiveActive_Error" 1 "InactiveActive_Active" 0 "InactiveActive_Inactive" ;
VAL_ 1066 TrafficSitSpdProfile_PathIndex 63 "PathIndex_Index63" 62 "PathIndex_Index62" 61 "PathIndex_Index61" 60 "PathIndex_Index60" 59 "PathIndex_Index59" 58 "PathIndex_Index58" 57 "PathIndex_Index57" 56 "PathIndex_Index56" 55 "PathIndex_Index55" 54 "PathIndex_Index54" 53 "PathIndex_Index53" 52 "PathIndex_Index52" 51 "PathIndex_Index51" 50 "PathIndex_Index50" 49 "PathIndex_Index49" 48 "PathIndex_Index48" 47 "PathIndex_Index47" 46 "PathIndex_Index46" 45 "PathIndex_Index45" 44 "PathIndex_Index44" 43 "PathIndex_Index43" 42 "PathIndex_Index42" 41 "PathIndex_Index41" 40 "PathIndex_Index40" 39 "PathIndex_Index39" 38 "PathIndex_Index38" 37 "PathIndex_Index37" 36 "PathIndex_Index36" 35 "PathIndex_Index35" 34 "PathIndex_Index34" 33 "PathIndex_Index33" 32 "PathIndex_Index32" 31 "PathIndex_Index31" 30 "PathIndex_Index30" 29 "PathIndex_Index29" 28 "PathIndex_Index28" 27 "PathIndex_Index27" 26 "PathIndex_Index26" 25 "PathIndex_Index25" 24 "PathIndex_Index24" 23 "PathIndex_Index23" 22 "PathIndex_Index22" 21 "PathIndex_Index21" 20 "PathIndex_Index20" 19 "PathIndex_Index19" 18 "PathIndex_Index18" 17 "PathIndex_Index17" 16 "PathIndex_Index16" 15 "PathIndex_Index15" 14 "PathIndex_Index14" 13 "PathIndex_Index13" 12 "PathIndex_Index12" 11 "PathIndex_Index11" 10 "PathIndex_Index10" 9 "PathIndex_Index9" 8 "PathIndex_Index8" 7 "PathIndex_DoNotUse4" 6 "PathIndex_DoNotUse3" 5 "PathIndex_DoNotUse2" 4 "PathIndex_DoNotUse1" 3 "PathIndex_PositionSignalInvalid" 2 "PathIndex_NotOnRoad" 1 "PathIndex_NoMapDataOnBoard" 0 "PathIndex_DoNotUse" ;
VAL_ 1066 TrafficSitSpdProfile_Type 255 "TrafficSitEventType_NotAvailable" 254 "TrafficSitEventType_Error" 253 "TrafficSitEventType_NotUsed3" 252 "TrafficSitEventType_NotUsed2" 251 "TrafficSitEventType_NotUsed1" 250 "TrafficSitEventType_GeneralEvent" 249 "TrafficSitEventType_spare242" 248 "TrafficSitEventType_spare241" 247 "TrafficSitEventType_spare240" 246 "TrafficSitEventType_spare239" 245 "TrafficSitEventType_spare238" 244 "TrafficSitEventType_spare237" 243 "TrafficSitEventType_spare236" 242 "TrafficSitEventType_spare235" 241 "TrafficSitEventType_spare234" 240 "TrafficSitEventType_spare233" 239 "TrafficSitEventType_spare232" 238 "TrafficSitEventType_spare231" 237 "TrafficSitEventType_spare230" 236 "TrafficSitEventType_spare229" 235 "TrafficSitEventType_spare228" 234 "TrafficSitEventType_spare227" 233 "TrafficSitEventType_spare226" 232 "TrafficSitEventType_spare225" 231 "TrafficSitEventType_spare224" 230 "TrafficSitEventType_spare223" 229 "TrafficSitEventType_spare222" 228 "TrafficSitEventType_spare221" 227 "TrafficSitEventType_spare220" 226 "TrafficSitEventType_spare219" 225 "TrafficSitEventType_spare218" 224 "TrafficSitEventType_spare217" 223 "TrafficSitEventType_spare216" 222 "TrafficSitEventType_spare215" 221 "TrafficSitEventType_spare214" 220 "TrafficSitEventType_spare213" 219 "TrafficSitEventType_spare212" 218 "TrafficSitEventType_spare211" 217 "TrafficSitEventType_spare210" 216 "TrafficSitEventType_spare209" 215 "TrafficSitEventType_spare208" 214 "TrafficSitEventType_spare207" 213 "TrafficSitEventType_spare206" 212 "TrafficSitEventType_spare205" 211 "TrafficSitEventType_spare204" 210 "TrafficSitEventType_spare203" 209 "TrafficSitEventType_spare202" 208 "TrafficSitEventType_spare201" 207 "TrafficSitEventType_spare200" 206 "TrafficSitEventType_spare199" 205 "TrafficSitEventType_spare198" 204 "TrafficSitEventType_spare197" 203 "TrafficSitEventType_spare196" 202 "TrafficSitEventType_spare195" 201 "TrafficSitEventType_spare194" 200 "TrafficSitEventType_spare193" 199 "TrafficSitEventType_spare192" 198 "TrafficSitEventType_spare191" 197 "TrafficSitEventType_spare190" 196 "TrafficSitEventType_spare189" 195 "TrafficSitEventType_spare188" 194 "TrafficSitEventType_spare187" 193 "TrafficSitEventType_spare186" 192 "TrafficSitEventType_spare185" 191 "TrafficSitEventType_spare184" 190 "TrafficSitEventType_spare183" 189 "TrafficSitEventType_spare182" 188 "TrafficSitEventType_spare181" 187 "TrafficSitEventType_spare180" 186 "TrafficSitEventType_spare179" 185 "TrafficSitEventType_spare178" 184 "TrafficSitEventType_spare177" 183 "TrafficSitEventType_spare176" 182 "TrafficSitEventType_spare175" 181 "TrafficSitEventType_spare174" 180 "TrafficSitEventType_spare173" 179 "TrafficSitEventType_spare172" 178 "TrafficSitEventType_spare171" 177 "TrafficSitEventType_spare170" 176 "TrafficSitEventType_spare169" 175 "TrafficSitEventType_spare168" 174 "TrafficSitEventType_spare167" 173 "TrafficSitEventType_spare166" 172 "TrafficSitEventType_spare165" 171 "TrafficSitEventType_spare164" 170 "TrafficSitEventType_spare163" 169 "TrafficSitEventType_spare162" 168 "TrafficSitEventType_spare161" 167 "TrafficSitEventType_spare160" 166 "TrafficSitEventType_spare159" 165 "TrafficSitEventType_spare158" 164 "TrafficSitEventType_spare157" 163 "TrafficSitEventType_spare156" 162 "TrafficSitEventType_spare155" 161 "TrafficSitEventType_spare154" 160 "TrafficSitEventType_spare153" 159 "TrafficSitEventType_spare152" 158 "TrafficSitEventType_spare151" 157 "TrafficSitEventType_spare150" 156 "TrafficSitEventType_spare149" 155 "TrafficSitEventType_spare148" 154 "TrafficSitEventType_spare147" 153 "TrafficSitEventType_spare146" 152 "TrafficSitEventType_spare145" 151 "TrafficSitEventType_spare144" 150 "TrafficSitEventType_spare143" 149 "TrafficSitEventType_spare142" 148 "TrafficSitEventType_spare141" 147 "TrafficSitEventType_spare140" 146 "TrafficSitEventType_spare139" 145 "TrafficSitEventType_spare138" 144 "TrafficSitEventType_spare137" 143 "TrafficSitEventType_spare136" 142 "TrafficSitEventType_spare135" 141 "TrafficSitEventType_spare134" 140 "TrafficSitEventType_spare133" 139 "TrafficSitEventType_spare132" 138 "TrafficSitEventType_spare131" 137 "TrafficSitEventType_spare130" 136 "TrafficSitEventType_spare129" 135 "TrafficSitEventType_spare128" 134 "TrafficSitEventType_spare127" 133 "TrafficSitEventType_spare126" 132 "TrafficSitEventType_spare125" 131 "TrafficSitEventType_spare124" 130 "TrafficSitEventType_spare123" 129 "TrafficSitEventType_spare122" 128 "TrafficSitEventType_spare121" 127 "TrafficSitEventType_spare120" 126 "TrafficSitEventType_spare119" 125 "TrafficSitEventType_spare118" 124 "TrafficSitEventType_spare117" 123 "TrafficSitEventType_spare116" 122 "TrafficSitEventType_spare115" 121 "TrafficSitEventType_spare114" 120 "TrafficSitEventType_spare113" 119 "TrafficSitEventType_spare112" 118 "TrafficSitEventType_spare111" 117 "TrafficSitEventType_spare110" 116 "TrafficSitEventType_spare109" 115 "TrafficSitEventType_spare108" 114 "TrafficSitEventType_spare107" 113 "TrafficSitEventType_spare106" 112 "TrafficSitEventType_spare105" 111 "TrafficSitEventType_spare104" 110 "TrafficSitEventType_spare103" 109 "TrafficSitEventType_spare102" 108 "TrafficSitEventType_spare101" 107 "TrafficSitEventType_spare100" 106 "TrafficSitEventType_spare99" 105 "TrafficSitEventType_spare98" 104 "TrafficSitEventType_spare97" 103 "TrafficSitEventType_spare96" 102 "TrafficSitEventType_spare95" 101 "TrafficSitEventType_spare94" 100 "TrafficSitEventType_spare93" 99 "TrafficSitEventType_spare92" 98 "TrafficSitEventType_spare91" 97 "TrafficSitEventType_spare90" 96 "TrafficSitEventType_spare89" 95 "TrafficSitEventType_spare88" 94 "TrafficSitEventType_spare87" 93 "TrafficSitEventType_spare86" 92 "TrafficSitEventType_spare85" 91 "TrafficSitEventType_spare84" 90 "TrafficSitEventType_spare83" 89 "TrafficSitEventType_spare82" 88 "TrafficSitEventType_spare81" 87 "TrafficSitEventType_spare80" 86 "TrafficSitEventType_spare79" 85 "TrafficSitEventType_spare78" 84 "TrafficSitEventType_spare77" 83 "TrafficSitEventType_spare76" 82 "TrafficSitEventType_spare75" 81 "TrafficSitEventType_spare74" 80 "TrafficSitEventType_spare73" 79 "TrafficSitEventType_spare72" 78 "TrafficSitEventType_spare71" 77 "TrafficSitEventType_spare70" 76 "TrafficSitEventType_spare69" 75 "TrafficSitEventType_spare68" 74 "TrafficSitEventType_spare67" 73 "TrafficSitEventType_spare66" 72 "TrafficSitEventType_spare65" 71 "TrafficSitEventType_spare64" 70 "TrafficSitEventType_spare63" 69 "TrafficSitEventType_spare62" 68 "TrafficSitEventType_spare61" 67 "TrafficSitEventType_spare60" 66 "TrafficSitEventType_spare59" 65 "TrafficSitEventType_spare58" 64 "TrafficSitEventType_spare57" 63 "TrafficSitEventType_spare56" 62 "TrafficSitEventType_spare55" 61 "TrafficSitEventType_spare54" 60 "TrafficSitEventType_spare53" 59 "TrafficSitEventType_spare52" 58 "TrafficSitEventType_spare51" 57 "TrafficSitEventType_spare50" 56 "TrafficSitEventType_spare49" 55 "TrafficSitEventType_spare48" 54 "TrafficSitEventType_spare47" 53 "TrafficSitEventType_spare46" 52 "TrafficSitEventType_spare45" 51 "TrafficSitEventType_spare44" 50 "TrafficSitEventType_spare43" 49 "TrafficSitEventType_spare42" 48 "TrafficSitEventType_spare41" 47 "TrafficSitEventType_spare40" 46 "TrafficSitEventType_spare39" 45 "TrafficSitEventType_spare38" 44 "TrafficSitEventType_spare37" 43 "TrafficSitEventType_spare36" 42 "TrafficSitEventType_spare35" 41 "TrafficSitEventType_spare34" 40 "TrafficSitEventType_spare33" 39 "TrafficSitEventType_spare32" 38 "TrafficSitEventType_spare31" 37 "TrafficSitEventType_spare30" 36 "TrafficSitEventType_spare29" 35 "TrafficSitEventType_spare28" 34 "TrafficSitEventType_spare27" 33 "TrafficSitEventType_spare26" 32 "TrafficSitEventType_spare25" 31 "TrafficSitEventType_spare24" 30 "TrafficSitEventType_spare23" 29 "TrafficSitEventType_spare22" 28 "TrafficSitEventType_spare21" 27 "TrafficSitEventType_spare20" 26 "TrafficSitEventType_spare19" 25 "TrafficSitEventType_spare18" 24 "TrafficSitEventType_spare17" 23 "TrafficSitEventType_spare16" 22 "TrafficSitEventType_spare15" 21 "TrafficSitEventType_spare14" 20 "TrafficSitEventType_spare13" 19 "TrafficSitEventType_spare12" 18 "TrafficSitEventType_spare11" 17 "TrafficSitEventType_spare10" 16 "TrafficSitEventType_spare9" 15 "TrafficSitEventType_spare8" 14 "TrafficSitEventType_spare7" 13 "TrafficSitEventType_spare6" 12 "TrafficSitEventType_spare5" 11 "TrafficSitEventType_spare4" 10 "TrafficSitEventType_spare3" 9 "TrafficSitEventType_spare2" 8 "TrafficSitEventType_spare1" 7 "TrafficSitEventType_NarrowRoad" 6 "TrafficSitEventType_TrafficJam_OR_SlowTraffic" 5 "TrafficSitEventType_Crossing" 4 "TrafficSitEventType_Roundabout" 3 "TrafficSitEventType_CurveRight" 2 "TrafficSitEventType_CurveLeft" 1 "TrafficSitEventType_SpeedLimit" 0 "TrafficSitEventType_NoEvent" ;
VAL_ 1338 ObserveRoadRestriction_OpCap 3 "ObserveRoadRestriction_NotAvailable" 2 "ObserveRoadRestriction_Spare" 1 "ObserveRoadRestriction_FullPerformance" 0 "ObserveRoadRestriction_NoPerformance" ;
VAL_ 1338 RoadSpeedUnitType 7 "SpeedUnitType_NotAvailable" 6 "SpeedUnitType_Error" 5 "SpeedUnitType_Undetermined" 4 "SpeedUnitType_Spare3" 3 "SpeedUnitType_Spare2" 2 "SpeedUnitType_Spare1" 1 "SpeedUnitType_mph" 0 "SpeedUnitType_Km_per_h" ;
VAL_ 1338 RoadOvertakingRestriction 7 "RoadOvertakingRestriction_NotAvailable" 6 "RoadOvertakingRestriction_Error" 5 "RoadOvertakingRestriction_Spare3" 4 "RoadOvertakingRestriction_Spare2" 3 "RoadOvertakingRestriction_Spare1" 2 "RoadOvertakingRestriction_OvertakingRestrictedTrucks" 1 "RoadOvertakingRestriction_OvertakingRestricted" 0 "RoadOvertakingRestriction_OvertakingAllowedNotRestricted" ;
VAL_ 1338 RoadTypeSpeedRestriction 7 "RoadTypeSpeedRestriction_NotAvailable" 6 "RoadTypeSpeedRestriction_Error" 5 "RoadTypeSpeedRestriction_Spare3" 4 "RoadTypeSpeedRestriction_Spare2" 3 "RoadTypeSpeedRestriction_Spare1" 2 "RoadTypeSpeedRestriction_Expressway" 1 "RoadTypeSpeedRestriction_Motorway" 0 "RoadTypeSpeedRestriction_Highway_undefined" ;
VAL_ 1338 ObserveRoadRestrictionStatus 3 "OffOn_NotAvailable" 2 "OffOn_Error" 1 "OffOn_On" 0 "OffOn_Off" ;
SIG_GROUP_ 1520 DiagFaultStat_WRCS_sg_ISig_4 1 : DiagFaultStat_WRCS_EcuAdr_ISig_4 DiagFaultStat_WRCS_DtcIdB_ISig_4 DiagFaultStat_WRCS_FailTB_ISig_4 DiagFaultStat_WRCS_FailTA_ISig_4 DiagFaultStat_WRCS_DtcIdA_ISig_4;
SIG_GROUP_ 1488 DiagFaultStat_VMCU_sg_ISig_4 1 : DiagFaultStat_VMCU_DtcIdA_ISig_4 DiagFaultStat_VMCU_EcuAdr_ISig_4 DiagFaultStat_VMCU_FailTA_ISig_4 DiagFaultStat_VMCU_FailTB_ISig_4 DiagFaultStat_VMCU_DtcIdB_ISig_4;
SIG_GROUP_ 1502 DiagFaultStat_TPM_sg_ISig_4 1 : DiagFaultStat_TPM_EcuAdr_ISig_4 DiagFaultStat_TPM_FailTB_ISig_4 DiagFaultStat_TPM_DtcIdA_ISig_4 DiagFaultStat_TPM_DtcIdB_ISig_4 DiagFaultStat_TPM_FailTA_ISig_4;
SIG_GROUP_ 1519 DiagFaultStat_TECU_sg_ISig_4 1 : DiagFaultStat_TECU_FailTA_ISig_4 DiagFaultStat_TECU_FailTB_ISig_4 DiagFaultStat_TECU_DtcIdA_ISig_4 DiagFaultStat_TECU_EcuAdr_ISig_4 DiagFaultStat_TECU_DtcIdB_ISig_4;
SIG_GROUP_ 1517 DiagFaultStat_SRS_sg_ISig_4 1 : DiagFaultStat_SRS_DtcIdB_ISig_4 DiagFaultStat_SRS_FailTB_ISig_4 DiagFaultStat_SRS_EcuAdr_ISig_4 DiagFaultStat_SRS_DtcIdA_ISig_4 DiagFaultStat_SRS_FailTA_ISig_4;
SIG_GROUP_ 1516 DiagFaultStat_RCIOM_sg_ISig_4 1 : DiagFaultStat_RCIOM_FailTA_ISig_ DiagFaultStat_RCIOM_FailTB_ISig_ DiagFaultStat_RCIOM_DtcIdB_ISig_ DiagFaultStat_RCIOM_DtcIdA_ISig_ DiagFaultStat_RCIOM_EcuAdr_ISig_;
SIG_GROUP_ 1515 DiagFaultStat_PDM_sg_ISig_4 1 : DiagFaultStat_PDM_EcuAdr_ISig_4 DiagFaultStat_PDM_DtcIdB_ISig_4 DiagFaultStat_PDM_FailTB_ISig_4 DiagFaultStat_PDM_DtcIdA_ISig_4 DiagFaultStat_PDM_FailTA_ISig_4;
SIG_GROUP_ 1514 DiagFaultStat_LPOS_sg_ISig_4 1 : DiagFaultStat_LPOS_DtcIdB_ISig_4 DiagFaultStat_LPOS_FailTB_ISig_4 DiagFaultStat_LPOS_DtcIdA_ISig_4 DiagFaultStat_LPOS_FailTA_ISig_4 DiagFaultStat_LPOS_EcuAdr_ISig_4;
SIG_GROUP_ 1513 DiagFaultStat_LECM_sg_ISig_4 1 : DiagFaultStat_LECM_EcuAdr_ISig_4 DiagFaultStat_LECM_FailTB_ISig_4 DiagFaultStat_LECM_FailTA_ISig_4 DiagFaultStat_LECM_DtcIdB_ISig_4 DiagFaultStat_LECM_DtcIdA_ISig_4;
SIG_GROUP_ 1497 DiagFaultStat_GFHCM2_sg_ISig_4 1 : DiagFaultStat_GFHCM2_DtcIdB_ISig DiagFaultStat_GFHCM2_DtcIdA_ISig DiagFaultStat_GFHCM2_FailTA_ISig DiagFaultStat_GFHCM2_EcuAdr_ISig DiagFaultStat_GFHCM2_FailTB_ISig;
SIG_GROUP_ 1496 DiagFaultStat_GFHCM1_sg_ISig_4 1 : DiagFaultStat_GFHCM1_DtcIdA_ISig DiagFaultStat_GFHCM1_FailTB_ISig DiagFaultStat_GFHCM1_FailTA_ISig DiagFaultStat_GFHCM1_EcuAdr_ISig DiagFaultStat_GFHCM1_DtcIdB_ISig;
SIG_GROUP_ 1512 DiagFaultStat_FLS_sg_ISig_4 1 : DiagFaultStat_FLS_DtcIdB_ISig_4 DiagFaultStat_FLS_FailTB_ISig_4 DiagFaultStat_FLS_DtcIdA_ISig_4 DiagFaultStat_FLS_EcuAdr_ISig_4 DiagFaultStat_FLS_FailTA_ISig_4;
SIG_GROUP_ 1499 DiagFaultStat_FCIOM_sg_ISig_4 1 : DiagFaultStat_FCIOM_DtcIdB_ISig_ DiagFaultStat_FCIOM_FailTA_ISig_ DiagFaultStat_FCIOM_FailTB_ISig_ DiagFaultStat_FCIOM_EcuAdr_ISig_ DiagFaultStat_FCIOM_DtcIdA_ISig_;
SIG_GROUP_ 1491 DiagFaultStat_FAS_sg_ISig_4 1 : DiagFaultStat_FAS_FailTA_ISig_4 DiagFaultStat_FAS_DtcIdA_ISig_4 DiagFaultStat_FAS_FailTB_ISig_4 DiagFaultStat_FAS_EcuAdr_ISig_4 DiagFaultStat_FAS_DtcIdB_ISig_4;
SIG_GROUP_ 1511 DiagFaultStat_EMS_sg_ISig_4 1 : DiagFaultStat_EMS_EcuAdr_ISig_4 DiagFaultStat_EMS_DtcIdB_ISig_4 DiagFaultStat_EMS_DtcIdA_ISig_4 DiagFaultStat_EMS_FailTB_ISig_4 DiagFaultStat_EMS_FailTA_ISig_4;
SIG_GROUP_ 1493 DiagFaultStat_EAS_sg_ISig_4 1 : DiagFaultStat_EAS_DtcIdB_ISig_4 DiagFaultStat_EAS_DtcIdA_ISig_4 DiagFaultStat_EAS_FailTB_ISig_4 DiagFaultStat_EAS_FailTA_ISig_4 DiagFaultStat_EAS_EcuAdr_ISig_4;
SIG_GROUP_ 1510 DiagFaultStat_DDM_sg_ISig_4 1 : DiagFaultStat_DDM_DtcIdA_ISig_4 DiagFaultStat_DDM_FailTA_ISig_4 DiagFaultStat_DDM_EcuAdr_ISig_4 DiagFaultStat_DDM_FailTB_ISig_4 DiagFaultStat_DDM_DtcIdB_ISig_4;
SIG_GROUP_ 1509 DiagFaultStat_DACU_sg_ISig_4 1 : DiagFaultStat_DACU_DtcIdB_ISig_4 DiagFaultStat_DACU_DtcIdA_ISig_4 DiagFaultStat_DACU_EcuAdr_ISig_4 DiagFaultStat_DACU_FailTB_ISig_4 DiagFaultStat_DACU_FailTA_ISig_4;
SIG_GROUP_ 1508 DiagFaultStat_CIOM_sg_ISig_4 1 : DiagFaultStat_CIOM_DtcIdA_ISig_4 DiagFaultStat_CIOM_EcuAdr_ISig_4 DiagFaultStat_CIOM_DtcIdB_ISig_4 DiagFaultStat_CIOM_FailTA_ISig_4 DiagFaultStat_CIOM_FailTB_ISig_4;
SIG_GROUP_ 1507 DiagFaultStat_CCM_sg_ISig_4 1 : DiagFaultStat_CCM_FailTB_ISig_4 DiagFaultStat_CCM_DtcIdA_ISig_4 DiagFaultStat_CCM_DtcIdB_ISig_4 DiagFaultStat_CCM_EcuAdr_ISig_4 DiagFaultStat_CCM_FailTA_ISig_4;
SIG_GROUP_ 1490 DiagFaultStat_CCIOM_sg_ISig_4 1 : DiagFaultStat_CCIOM_EcuAdr_ISig_ DiagFaultStat_CCIOM_FailTA_ISig_ DiagFaultStat_CCIOM_DtcIdB_ISig_ DiagFaultStat_CCIOM_DtcIdA_ISig_ DiagFaultStat_CCIOM_FailTB_ISig_;
SIG_GROUP_ 1494 DiagFaultStat_BPMU_sg_ISig_4 1 : DiagFaultStat_BPMU_EcuAdr_ISig_4 DiagFaultStat_BPMU_DtcIdB_ISig_4 DiagFaultStat_BPMU_FailTB_ISig_4 DiagFaultStat_BPMU_FailTA_ISig_4 DiagFaultStat_BPMU_DtcIdA_ISig_4;
SIG_GROUP_ 1506 DiagFaultStat_BBM_sg_ISig_4 1 : DiagFaultStat_BBM_EcuAdr_ISig_4 DiagFaultStat_BBM_DtcIdB_ISig_4 DiagFaultStat_BBM_FailTB_ISig_4 DiagFaultStat_BBM_DtcIdA_ISig_4 DiagFaultStat_BBM_FailTA_ISig_4;
SIG_GROUP_ 1505 DiagFaultStat_BBIOM_sg_ISig_4 1 : DiagFaultStat_BBIOM_FailTA_ISig_ DiagFaultStat_BBIOM_FailTB_ISig_ DiagFaultStat_BBIOM_DtcIdB_ISig_ DiagFaultStat_BBIOM_DtcIdA_ISig_ DiagFaultStat_BBIOM_EcuAdr_ISig_;
SIG_GROUP_ 1504 DiagFaultStat_Alarm_sg_ISig_4 1 : DiagFaultStat_Alarm_DtcIdA_ISig_ DiagFaultStat_Alarm_EcuAdr_ISig_ DiagFaultStat_Alarm_FailTB_ISig_ DiagFaultStat_Alarm_FailTA_ISig_ DiagFaultStat_Alarm_DtcIdB_ISig_;
SIG_GROUP_ 1489 DiagFaultStat_APM_sg_ISig_4 1 : DiagFaultStat_APM_DtcIdA_ISig_4 DiagFaultStat_APM_EcuAdr_ISig_4 DiagFaultStat_APM_FailTB_ISig_4 DiagFaultStat_APM_DtcIdB_ISig_4 DiagFaultStat_APM_FailTA_ISig_4;
SIG_GROUP_ 1191 PS_TrafficSitPathEvt1_sg 1 : PS_TrafficSitPathEvt1_Type PS_TrafficSitPathEvt1_Speed PS_TrafficSitPathEvt1_Distance;
SIG_GROUP_ 1191 PS_TrafficSitPathEvt2_sg 1 : PS_TrafficSitPathEvt2_Distance PS_TrafficSitPathEvt2_Speed PS_TrafficSitPathEvt2_Type;
SIG_GROUP_ 1066 TrafficSitSpdProfile_sg 1 : TrafficSitSpdProfile_MinSpd TrafficSitSpdProfile_Offset TrafficSitSpdProfile_MaxSpd TrafficSitSpdProfile_Speed TrafficSitSpdProfile_PathIndex TrafficSitSpdProfile_Type;
